VERSION ""

NS_ :

BS_:

BU_: BMS_Controller NF_Controller NF_Controllers

BO_ 2499758692 BATT_Version: 8 BMS_Controller
 SG_ BATT_SwVerSubMinorApp m0 : 24|8@1+ (1,0) [0|255] ""  NF_Controller
 SG_ BATT_SwVerMinorApp m0 : 16|8@1+ (1,0) [0|255] ""  NF_Controller
 SG_ BATT_SwVerMajorApp m0 : 8|8@1+ (1,0) [0|255] ""  NF_Controller
 SG_ BATT_HwVerApp m0 : 32|8@1+ (1,0) [0|255] ""  NF_Controller
 SG_ BATT_SwVerAbsCusApp m0 : 40|8@1+ (1,0) [0|255] ""  NF_Controller
 SG_ BATT_SwVerAbsIntApp m0 : 48|8@1+ (1,0) [0|255] ""  NF_Controller
 SG_ BATT_SwVerSubMinorBl m1 : 24|8@1+ (1,0) [0|255] ""  NF_Controller
 SG_ BATT_SwVerMinorBl m1 : 16|8@1+ (1,0) [0|255] ""  NF_Controller
 SG_ BATT_SwVerMajorBl m1 : 8|8@1+ (1,0) [0|255] ""  NF_Controller
 SG_ BATT_HwVerBl m1 : 32|8@1+ (1,0) [0|255] ""  NF_Controller
 SG_ BATT_SwVerAbsCusBl m1 : 40|8@1+ (1,0) [0|255] ""  NF_Controller
 SG_ BATT_SwVerAbsIntBl m1 : 48|8@1+ (1,0) [0|255] ""  NF_Controller
 SG_ BATT_SwVerSubMinorCal m2 : 24|8@1+ (1,0) [0|255] ""  NF_Controller
 SG_ BATT_SwVerMinorCal m2 : 16|8@1+ (1,0) [0|255] ""  NF_Controller
 SG_ BATT_SwVerMajorCal m2 : 8|8@1+ (1,0) [0|255] ""  NF_Controller
 SG_ BATT_HwVerCal m2 : 32|8@1+ (1,0) [0|255] ""  NF_Controller
 SG_ BATT_SwVerAbsCusCal m2 : 40|8@1+ (1,0) [0|255] ""  NF_Controller
 SG_ BATT_SwVerAbsIntCal m2 : 48|8@1+ (1,0) [0|255] ""  NF_Controller
 SG_ multiplexorvr M : 0|2@1+ (1,0) [0|2] ""  NF_Controllers

BO_ 2499763812 BATT_Pack_Inhibition: 8 BMS_Controller
 SG_ BATT_01_inhibitionPyroFuse m0 : 11|1@1+ (1,0) [0|1] ""  NF_Controller
 SG_ BATT_01_inhibitionRegen m0 : 10|1@1+ (1,0) [0|1] ""  NF_Controller
 SG_ BATT_01_inhibitionFullPower m0 : 9|1@1+ (1,0) [0|1] ""  NF_Controller
 SG_ BATT_01_inhibitionRampDown m0 : 8|1@1+ (1,0) [0|1] ""  NF_Controller
 SG_ BATT_01_inhibitionDriveEntry m0 : 3|1@1+ (1,0) [0|1] ""  NF_Controller
 SG_ BATT_01_inhibitionDrive m0 : 2|1@1+ (1,0) [0|1] ""  NF_Controller
 SG_ BATT_01_inhibitionCharge m0 : 1|1@1+ (1,0) [0|1] ""  NF_Controller
 SG_ BATT_01_inhibitionChargeEntry m0 : 0|1@1+ (1,0) [0|1] ""  NF_Controller
 SG_ BATT_02_inhibitionPyroFuse m1 : 11|1@1+ (1,0) [0|1] ""  NF_Controller
 SG_ BATT_02_inhibitionRegen m1 : 10|1@1+ (1,0) [0|1] ""  NF_Controller
 SG_ BATT_02_inhibitionFullPower m1 : 9|1@1+ (1,0) [0|1] ""  NF_Controller
 SG_ BATT_02_inhibitionRampDown m1 : 8|1@1+ (1,0) [0|1] ""  NF_Controller
 SG_ BATT_02_inhibitionDriveEntry m1 : 3|1@1+ (1,0) [0|1] ""  NF_Controller
 SG_ BATT_02_inhibitionDrive m1 : 2|1@1+ (1,0) [0|1] ""  NF_Controller
 SG_ BATT_02_inhibitionCharge m1 : 1|1@1+ (1,0) [0|1] ""  NF_Controller
 SG_ BATT_02_inhibitionChargeEntry m1 : 0|1@1+ (1,0) [0|1] ""  NF_Controller
 SG_ BATT_03_inhibitionPyroFuse m2 : 11|1@1+ (1,0) [0|1] ""  NF_Controller
 SG_ BATT_03_inhibitionRegen m2 : 10|1@1+ (1,0) [0|1] ""  NF_Controller
 SG_ BATT_03_inhibitionFullPower m2 : 9|1@1+ (1,0) [0|1] ""  NF_Controller
 SG_ BATT_03_inhibitionRampDown m2 : 8|1@1+ (1,0) [0|1] ""  NF_Controller
 SG_ BATT_03_inhibitionDriveEntry m2 : 3|1@1+ (1,0) [0|1] ""  NF_Controller
 SG_ BATT_03_inhibitionDrive m2 : 2|1@1+ (1,0) [0|1] ""  NF_Controller
 SG_ BATT_03_inhibitionCharge m2 : 1|1@1+ (1,0) [0|1] ""  NF_Controller
 SG_ BATT_03_inhibitionChargeEntry m2 : 0|1@1+ (1,0) [0|1] ""  NF_Controller
 SG_ BATT_04_inhibitionPyroFuse m3 : 11|1@1+ (1,0) [0|1] ""  NF_Controller
 SG_ BATT_04_inhibitionRegen m3 : 10|1@1+ (1,0) [0|1] ""  NF_Controller
 SG_ BATT_04_inhibitionFullPower m3 : 9|1@1+ (1,0) [0|1] ""  NF_Controller
 SG_ BATT_04_inhibitionRampDown m3 : 8|1@1+ (1,0) [0|1] ""  NF_Controller
 SG_ BATT_04_inhibitionDriveEntry m3 : 3|1@1+ (1,0) [0|1] ""  NF_Controller
 SG_ BATT_04_inhibitionDrive m3 : 2|1@1+ (1,0) [0|1] ""  NF_Controller
 SG_ BATT_04_inhibitionCharge m3 : 1|1@1+ (1,0) [0|1] ""  NF_Controller
 SG_ BATT_04_inhibitionChargeEntry m3 : 0|1@1+ (1,0) [0|1] ""  NF_Controller
 SG_ BATT_05_inhibitionPyroFuse m4 : 11|1@1+ (1,0) [0|1] ""  NF_Controller
 SG_ BATT_05_inhibitionRegen m4 : 10|1@1+ (1,0) [0|1] ""  NF_Controller
 SG_ BATT_05_inhibitionFullPower m4 : 9|1@1+ (1,0) [0|1] ""  NF_Controller
 SG_ BATT_05_inhibitionRampDown m4 : 8|1@1+ (1,0) [0|1] ""  NF_Controller
 SG_ BATT_05_inhibitionDriveEntry m4 : 3|1@1+ (1,0) [0|1] ""  NF_Controller
 SG_ BATT_05_inhibitionDrive m4 : 2|1@1+ (1,0) [0|1] ""  NF_Controller
 SG_ BATT_05_inhibitionCharge m4 : 1|1@1+ (1,0) [0|1] ""  NF_Controller
 SG_ BATT_05_inhibitionChargeEntry m4 : 0|1@1+ (1,0) [0|1] ""  NF_Controller
 SG_ BATT_06_inhibitionPyroFuse m5 : 11|1@1+ (1,0) [0|1] ""  NF_Controller
 SG_ BATT_06_inhibitionRegen m5 : 10|1@1+ (1,0) [0|1] ""  NF_Controller
 SG_ BATT_06_inhibitionFullPower m5 : 9|1@1+ (1,0) [0|1] ""  NF_Controller
 SG_ BATT_06_inhibitionRampDown m5 : 8|1@1+ (1,0) [0|1] ""  NF_Controller
 SG_ BATT_06_inhibitionDriveEntry m5 : 3|1@1+ (1,0) [0|1] ""  NF_Controller
 SG_ BATT_06_inhibitionDrive m5 : 2|1@1+ (1,0) [0|1] ""  NF_Controller
 SG_ BATT_06_inhibitionCharge m5 : 1|1@1+ (1,0) [0|1] ""  NF_Controller
 SG_ BATT_06_inhibitionChargeEntry m5 : 0|1@1+ (1,0) [0|1] ""  NF_Controller
 SG_ BATT_07_inhibitionPyroFuse m6 : 11|1@1+ (1,0) [0|1] ""  NF_Controller
 SG_ BATT_07_inhibitionRegen m6 : 10|1@1+ (1,0) [0|1] ""  NF_Controller
 SG_ BATT_07_inhibitionFullPower m6 : 9|1@1+ (1,0) [0|1] ""  NF_Controller
 SG_ BATT_07_inhibitionRampDown m6 : 8|1@1+ (1,0) [0|1] ""  NF_Controller
 SG_ BATT_07_inhibitionDriveEntry m6 : 3|1@1+ (1,0) [0|1] ""  NF_Controller
 SG_ BATT_07_inhibitionDrive m6 : 2|1@1+ (1,0) [0|1] ""  NF_Controller
 SG_ BATT_07_inhibitionCharge m6 : 1|1@1+ (1,0) [0|1] ""  NF_Controller
 SG_ BATT_07_inhibitionChargeEntry m6 : 0|1@1+ (1,0) [0|1] ""  NF_Controller
 SG_ BATT_08_inhibitionPyroFuse m7 : 11|1@1+ (1,0) [0|1] ""  NF_Controller
 SG_ BATT_08_inhibitionRegen m7 : 10|1@1+ (1,0) [0|1] ""  NF_Controller
 SG_ BATT_08_inhibitionFullPower m7 : 9|1@1+ (1,0) [0|1] ""  NF_Controller
 SG_ BATT_08_inhibitionRampDown m7 : 8|1@1+ (1,0) [0|1] ""  NF_Controller
 SG_ BATT_08_inhibitionDriveEntry m7 : 3|1@1+ (1,0) [0|1] ""  NF_Controller
 SG_ BATT_08_inhibitionDrive m7 : 2|1@1+ (1,0) [0|1] ""  NF_Controller
 SG_ BATT_08_inhibitionCharge m7 : 1|1@1+ (1,0) [0|1] ""  NF_Controller
 SG_ BATT_08_inhibitionChargeEntry m7 : 0|1@1+ (1,0) [0|1] ""  NF_Controller
 SG_ BATT_09_inhibitionPyroFuse m8 : 11|1@1+ (1,0) [0|1] ""  NF_Controller
 SG_ BATT_09_inhibitionRegen m8 : 10|1@1+ (1,0) [0|1] ""  NF_Controller
 SG_ BATT_09_inhibitionFullPower m8 : 9|1@1+ (1,0) [0|1] ""  NF_Controller
 SG_ BATT_09_inhibitionRampDown m8 : 8|1@1+ (1,0) [0|1] ""  NF_Controller
 SG_ BATT_09_inhibitionDriveEntry m8 : 3|1@1+ (1,0) [0|1] ""  NF_Controller
 SG_ BATT_09_inhibitionDrive m8 : 2|1@1+ (1,0) [0|1] ""  NF_Controller
 SG_ BATT_09_inhibitionCharge m8 : 1|1@1+ (1,0) [0|1] ""  NF_Controller
 SG_ BATT_09_inhibitionChargeEntry m8 : 0|1@1+ (1,0) [0|1] ""  NF_Controller
 SG_ BATT_10_inhibitionPyroFuse m9 : 11|1@1+ (1,0) [0|1] ""  NF_Controller
 SG_ BATT_10_inhibitionRegen m9 : 10|1@1+ (1,0) [0|1] ""  NF_Controller
 SG_ BATT_10_inhibitionFullPower m9 : 9|1@1+ (1,0) [0|1] ""  NF_Controller
 SG_ BATT_10_inhibitionRampDown m9 : 8|1@1+ (1,0) [0|1] ""  NF_Controller
 SG_ BATT_10_inhibitionDriveEntry m9 : 3|1@1+ (1,0) [0|1] ""  NF_Controller
 SG_ BATT_10_inhibitionDrive m9 : 2|1@1+ (1,0) [0|1] ""  NF_Controller
 SG_ BATT_10_inhibitionCharge m9 : 1|1@1+ (1,0) [0|1] ""  NF_Controller
 SG_ BATT_10_inhibitionChargeEntry m9 : 0|1@1+ (1,0) [0|1] ""  NF_Controller
 SG_ BATT_packInhMux M : 4|4@1+ (1,0) [0|15] ""  NF_Controller

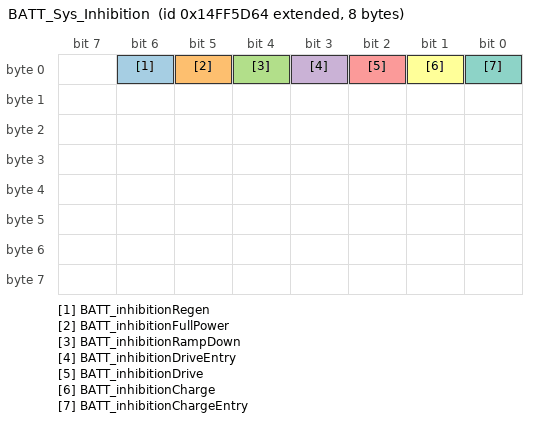
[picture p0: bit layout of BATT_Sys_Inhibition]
BO_ 2499763556 BATT_Sys_Inhibition: 8 BMS_Controller
 SG_ BATT_inhibitionRegen : 6|1@1+ (1,0) [0|1] ""  NF_Controller
 SG_ BATT_inhibitionFullPower : 5|1@1+ (1,0) [0|1] ""  NF_Controller
 SG_ BATT_inhibitionRampDown : 4|1@1+ (1,0) [0|1] ""  NF_Controller
 SG_ BATT_inhibitionDriveEntry : 3|1@1+ (1,0) [0|1] ""  NF_Controller
 SG_ BATT_inhibitionDrive : 2|1@1+ (1,0) [0|1] ""  NF_Controller
 SG_ BATT_inhibitionCharge : 1|1@1+ (1,0) [0|1] ""  NF_Controller
 SG_ BATT_inhibitionChargeEntry : 0|1@1+ (1,0) [0|1] ""  NF_Controller

BO_ 2499763300 BATT_Diagnostic_Pack_D: 8 BMS_Controller
 SG_ BATT_01_Placeholder16 m0 : 10|2@1+ (1,0) [0|3] ""  NF_Controller
 SG_ BATT_01_Placeholder15 m0 : 8|2@1+ (1,0) [0|3] ""  NF_Controller
 SG_ BATT_01_Placeholder14 m0 : 22|2@1+ (1,0) [0|3] ""  NF_Controller
 SG_ BATT_01_Placeholder13 m0 : 20|2@1+ (1,0) [0|3] ""  NF_Controller
 SG_ BATT_01_Placeholder02 m0 : 46|2@1+ (1,0) [0|3] ""  NF_Controller
 SG_ BATT_01_Placeholder01 m0 : 44|2@1+ (1,0) [0|3] ""  NF_Controller
 SG_ BATT_01_Placeholder12 m0 : 18|2@1+ (1,0) [0|3] ""  NF_Controller
 SG_ BATT_01_Placeholder11 m0 : 16|2@1+ (1,0) [0|3] ""  NF_Controller
 SG_ BATT_01_Placeholder10 m0 : 30|2@1+ (1,0) [0|3] ""  NF_Controller
 SG_ BATT_01_Placeholder09 m0 : 28|2@1+ (1,0) [0|3] ""  NF_Controller
 SG_ BATT_01_Placeholder08 m0 : 26|2@1+ (1,0) [0|3] ""  NF_Controller
 SG_ BATT_01_Placeholder07 m0 : 24|2@1+ (1,0) [0|3] ""  NF_Controller
 SG_ BATT_01_Placeholder06 m0 : 38|2@1+ (1,0) [0|3] ""  NF_Controller
 SG_ BATT_01_Placeholder05 m0 : 36|2@1+ (1,0) [0|3] ""  NF_Controller
 SG_ BATT_01_SpeakerMia m0 : 2|2@1+ (1,0) [0|3] ""  NF_Controller
 SG_ BATT_01_Placeholder19 m0 : 0|2@1+ (1,0) [0|3] ""  NF_Controller
 SG_ BATT_01_Placeholder18 m0 : 14|2@1+ (1,0) [0|3] ""  NF_Controller
 SG_ BATT_01_Placeholder17 m0 : 12|2@1+ (1,0) [0|3] ""  NF_Controller
 SG_ BATT_01_Placeholder04 m0 : 34|2@1+ (1,0) [0|3] ""  NF_Controller
 SG_ BATT_01_Placeholder03 m0 : 32|2@1+ (1,0) [0|3] ""  NF_Controller
 SG_ BATT_02_Placeholder16 m1 : 10|2@1+ (1,0) [0|3] ""  NF_Controller
 SG_ BATT_02_Placeholder15 m1 : 8|2@1+ (1,0) [0|3] ""  NF_Controller
 SG_ BATT_02_Placeholder14 m1 : 22|2@1+ (1,0) [0|3] ""  NF_Controller
 SG_ BATT_02_Placeholder13 m1 : 20|2@1+ (1,0) [0|3] ""  NF_Controller
 SG_ BATT_02_Placeholder02 m1 : 46|2@1+ (1,0) [0|3] ""  NF_Controller
 SG_ BATT_02_Placeholder01 m1 : 44|2@1+ (1,0) [0|3] ""  NF_Controller
 SG_ BATT_02_Placeholder12 m1 : 18|2@1+ (1,0) [0|3] ""  NF_Controller
 SG_ BATT_02_Placeholder11 m1 : 16|2@1+ (1,0) [0|3] ""  NF_Controller
 SG_ BATT_02_Placeholder10 m1 : 30|2@1+ (1,0) [0|3] ""  NF_Controller
 SG_ BATT_02_Placeholder09 m1 : 28|2@1+ (1,0) [0|3] ""  NF_Controller
 SG_ BATT_02_Placeholder08 m1 : 26|2@1+ (1,0) [0|3] ""  NF_Controller
 SG_ BATT_02_Placeholder07 m1 : 24|2@1+ (1,0) [0|3] ""  NF_Controller
 SG_ BATT_02_Placeholder06 m1 : 38|2@1+ (1,0) [0|3] ""  NF_Controller
 SG_ BATT_02_Placeholder05 m1 : 36|2@1+ (1,0) [0|3] ""  NF_Controller
 SG_ BATT_02_SpeakerMia m1 : 2|2@1+ (1,0) [0|3] ""  NF_Controller
 SG_ BATT_02_Placeholder19 m1 : 0|2@1+ (1,0) [0|3] ""  NF_Controller
 SG_ BATT_02_Placeholder18 m1 : 14|2@1+ (1,0) [0|3] ""  NF_Controller
 SG_ BATT_02_Placeholder17 m1 : 12|2@1+ (1,0) [0|3] ""  NF_Controller
 SG_ BATT_02_Placeholder04 m1 : 34|2@1+ (1,0) [0|3] ""  NF_Controller
 SG_ BATT_02_Placeholder03 m1 : 32|2@1+ (1,0) [0|3] ""  NF_Controller
 SG_ BATT_03_Placeholder16 m2: 10|2@1+ (1,0) [0|3] ""  NF_Controller
 SG_ BATT_03_Placeholder15 m2: 8|2@1+ (1,0) [0|3] ""  NF_Controller
 SG_ BATT_03_Placeholder14 m2: 22|2@1+ (1,0) [0|3] ""  NF_Controller
 SG_ BATT_03_Placeholder13 m2: 20|2@1+ (1,0) [0|3] ""  NF_Controller
 SG_ BATT_03_Placeholder02 m2: 46|2@1+ (1,0) [0|3] ""  NF_Controller
 SG_ BATT_03_Placeholder01 m2: 44|2@1+ (1,0) [0|3] ""  NF_Controller
 SG_ BATT_03_Placeholder12 m2: 18|2@1+ (1,0) [0|3] ""  NF_Controller
 SG_ BATT_03_Placeholder11 m2: 16|2@1+ (1,0) [0|3] ""  NF_Controller
 SG_ BATT_03_Placeholder10 m2: 30|2@1+ (1,0) [0|3] ""  NF_Controller
 SG_ BATT_03_Placeholder09 m2: 28|2@1+ (1,0) [0|3] ""  NF_Controller
 SG_ BATT_03_Placeholder08 m2: 26|2@1+ (1,0) [0|3] ""  NF_Controller
 SG_ BATT_03_Placeholder07 m2: 24|2@1+ (1,0) [0|3] ""  NF_Controller
 SG_ BATT_03_Placeholder06 m2: 38|2@1+ (1,0) [0|3] ""  NF_Controller
 SG_ BATT_03_Placeholder05 m2: 36|2@1+ (1,0) [0|3] ""  NF_Controller
 SG_ BATT_03_SpeakerMia m2: 2|2@1+ (1,0) [0|3] ""  NF_Controller
 SG_ BATT_03_Placeholder19 m2: 0|2@1+ (1,0) [0|3] ""  NF_Controller
 SG_ BATT_03_Placeholder18 m2: 14|2@1+ (1,0) [0|3] ""  NF_Controller
 SG_ BATT_03_Placeholder17 m2: 12|2@1+ (1,0) [0|3] ""  NF_Controller
 SG_ BATT_03_Placeholder04 m2: 34|2@1+ (1,0) [0|3] ""  NF_Controller
 SG_ BATT_03_Placeholder03 m2: 32|2@1+ (1,0) [0|3] ""  NF_Controller
 SG_ BATT_04_Placeholder16 m3 : 10|2@1+ (1,0) [0|3] ""  NF_Controller
 SG_ BATT_04_Placeholder15 m3 : 8|2@1+ (1,0) [0|3] ""  NF_Controller
 SG_ BATT_04_Placeholder14 m3 : 22|2@1+ (1,0) [0|3] ""  NF_Controller
 SG_ BATT_04_Placeholder13 m3 : 20|2@1+ (1,0) [0|3] ""  NF_Controller
 SG_ BATT_04_Placeholder02 m3 : 46|2@1+ (1,0) [0|3] ""  NF_Controller
 SG_ BATT_04_Placeholder01 m3 : 44|2@1+ (1,0) [0|3] ""  NF_Controller
 SG_ BATT_04_Placeholder12 m3 : 18|2@1+ (1,0) [0|3] ""  NF_Controller
 SG_ BATT_04_Placeholder11 m3 : 16|2@1+ (1,0) [0|3] ""  NF_Controller
 SG_ BATT_04_Placeholder10 m3 : 30|2@1+ (1,0) [0|3] ""  NF_Controller
 SG_ BATT_04_Placeholder09 m3 : 28|2@1+ (1,0) [0|3] ""  NF_Controller
 SG_ BATT_04_Placeholder08 m3 : 26|2@1+ (1,0) [0|3] ""  NF_Controller
 SG_ BATT_04_Placeholder07 m3 : 24|2@1+ (1,0) [0|3] ""  NF_Controller
 SG_ BATT_04_Placeholder06 m3 : 38|2@1+ (1,0) [0|3] ""  NF_Controller
 SG_ BATT_04_Placeholder05 m3 : 36|2@1+ (1,0) [0|3] ""  NF_Controller
 SG_ BATT_04_SpeakerMia m3 : 2|2@1+ (1,0) [0|3] ""  NF_Controller
 SG_ BATT_04_Placeholder19 m3 : 0|2@1+ (1,0) [0|3] ""  NF_Controller
 SG_ BATT_04_Placeholder18 m3 : 14|2@1+ (1,0) [0|3] ""  NF_Controller
 SG_ BATT_04_Placeholder17 m3 : 12|2@1+ (1,0) [0|3] ""  NF_Controller
 SG_ BATT_04_Placeholder04 m3 : 34|2@1+ (1,0) [0|3] ""  NF_Controller
 SG_ BATT_04_Placeholder03 m3 : 32|2@1+ (1,0) [0|3] ""  NF_Controller
 SG_ BATT_05_Placeholder16 m4 : 10|2@1+ (1,0) [0|3] ""  NF_Controller
 SG_ BATT_05_Placeholder15 m4 : 8|2@1+ (1,0) [0|3] ""  NF_Controller
 SG_ BATT_05_Placeholder14 m4 : 22|2@1+ (1,0) [0|3] ""  NF_Controller
 SG_ BATT_05_Placeholder13 m4 : 20|2@1+ (1,0) [0|3] ""  NF_Controller
 SG_ BATT_05_Placeholder02 m4 : 46|2@1+ (1,0) [0|3] ""  NF_Controller
 SG_ BATT_05_Placeholder01 m4 : 44|2@1+ (1,0) [0|3] ""  NF_Controller
 SG_ BATT_05_Placeholder12 m4 : 18|2@1+ (1,0) [0|3] ""  NF_Controller
 SG_ BATT_05_Placeholder11 m4 : 16|2@1+ (1,0) [0|3] ""  NF_Controller
 SG_ BATT_05_Placeholder10 m4 : 30|2@1+ (1,0) [0|3] ""  NF_Controller
 SG_ BATT_05_Placeholder09 m4 : 28|2@1+ (1,0) [0|3] ""  NF_Controller
 SG_ BATT_05_Placeholder08 m4 : 26|2@1+ (1,0) [0|3] ""  NF_Controller
 SG_ BATT_05_Placeholder07 m4 : 24|2@1+ (1,0) [0|3] ""  NF_Controller
 SG_ BATT_05_Placeholder06 m4 : 38|2@1+ (1,0) [0|3] ""  NF_Controller
 SG_ BATT_05_Placeholder05 m4 : 36|2@1+ (1,0) [0|3] ""  NF_Controller
 SG_ BATT_05_SpeakerMia m4 : 2|2@1+ (1,0) [0|3] ""  NF_Controller
 SG_ BATT_05_Placeholder19 m4 : 0|2@1+ (1,0) [0|3] ""  NF_Controller
 SG_ BATT_05_Placeholder18 m4 : 14|2@1+ (1,0) [0|3] ""  NF_Controller
 SG_ BATT_05_Placeholder17 m4 : 12|2@1+ (1,0) [0|3] ""  NF_Controller
 SG_ BATT_05_Placeholder04 m4 : 34|2@1+ (1,0) [0|3] ""  NF_Controller
 SG_ BATT_05_Placeholder03 m4 : 32|2@1+ (1,0) [0|3] ""  NF_Controller
 SG_ BATT_06_Placeholder16 m5 : 10|2@1+ (1,0) [0|3] ""  NF_Controller
 SG_ BATT_06_Placeholder15 m5 : 8|2@1+ (1,0) [0|3] ""  NF_Controller
 SG_ BATT_06_Placeholder14 m5 : 22|2@1+ (1,0) [0|3] ""  NF_Controller
 SG_ BATT_06_Placeholder13 m5 : 20|2@1+ (1,0) [0|3] ""  NF_Controller
 SG_ BATT_06_Placeholder02 m5 : 46|2@1+ (1,0) [0|3] ""  NF_Controller
 SG_ BATT_06_Placeholder01 m5 : 44|2@1+ (1,0) [0|3] ""  NF_Controller
 SG_ BATT_06_Placeholder12 m5 : 18|2@1+ (1,0) [0|3] ""  NF_Controller
 SG_ BATT_06_Placeholder11 m5 : 16|2@1+ (1,0) [0|3] ""  NF_Controller
 SG_ BATT_06_Placeholder10 m5 : 30|2@1+ (1,0) [0|3] ""  NF_Controller
 SG_ BATT_06_Placeholder09 m5 : 28|2@1+ (1,0) [0|3] ""  NF_Controller
 SG_ BATT_06_Placeholder08 m5 : 26|2@1+ (1,0) [0|3] ""  NF_Controller
 SG_ BATT_06_Placeholder07 m5 : 24|2@1+ (1,0) [0|3] ""  NF_Controller
 SG_ BATT_06_Placeholder06 m5 : 38|2@1+ (1,0) [0|3] ""  NF_Controller
 SG_ BATT_06_Placeholder05 m5 : 36|2@1+ (1,0) [0|3] ""  NF_Controller
 SG_ BATT_06_SpeakerMia m5 : 2|2@1+ (1,0) [0|3] ""  NF_Controller
 SG_ BATT_06_Placeholder19 m5 : 0|2@1+ (1,0) [0|3] ""  NF_Controller
 SG_ BATT_06_Placeholder18 m5 : 14|2@1+ (1,0) [0|3] ""  NF_Controller
 SG_ BATT_06_Placeholder17 m5 : 12|2@1+ (1,0) [0|3] ""  NF_Controller
 SG_ BATT_06_Placeholder04 m5 : 34|2@1+ (1,0) [0|3] ""  NF_Controller
 SG_ BATT_06_Placeholder03 m5 : 32|2@1+ (1,0) [0|3] ""  NF_Controller
 SG_ BATT_07_Placeholder16 m6 : 10|2@1+ (1,0) [0|3] ""  NF_Controller
 SG_ BATT_07_Placeholder15 m6 : 8|2@1+ (1,0) [0|3] ""  NF_Controller
 SG_ BATT_07_Placeholder14 m6 : 22|2@1+ (1,0) [0|3] ""  NF_Controller
 SG_ BATT_07_Placeholder13 m6 : 20|2@1+ (1,0) [0|3] ""  NF_Controller
 SG_ BATT_07_Placeholder02 m6 : 46|2@1+ (1,0) [0|3] ""  NF_Controller
 SG_ BATT_07_Placeholder01 m6 : 44|2@1+ (1,0) [0|3] ""  NF_Controller
 SG_ BATT_07_Placeholder12 m6 : 18|2@1+ (1,0) [0|3] ""  NF_Controller
 SG_ BATT_07_Placeholder11 m6 : 16|2@1+ (1,0) [0|3] ""  NF_Controller
 SG_ BATT_07_Placeholder10 m6 : 30|2@1+ (1,0) [0|3] ""  NF_Controller
 SG_ BATT_07_Placeholder09 m6 : 28|2@1+ (1,0) [0|3] ""  NF_Controller
 SG_ BATT_07_Placeholder08 m6 : 26|2@1+ (1,0) [0|3] ""  NF_Controller
 SG_ BATT_07_Placeholder07 m6 : 24|2@1+ (1,0) [0|3] ""  NF_Controller
 SG_ BATT_07_Placeholder06 m6 : 38|2@1+ (1,0) [0|3] ""  NF_Controller
 SG_ BATT_07_Placeholder05 m6 : 36|2@1+ (1,0) [0|3] ""  NF_Controller
 SG_ BATT_07_SpeakerMia m6 : 2|2@1+ (1,0) [0|3] ""  NF_Controller
 SG_ BATT_07_Placeholder19 m6 : 0|2@1+ (1,0) [0|3] ""  NF_Controller
 SG_ BATT_07_Placeholder18 m6 : 14|2@1+ (1,0) [0|3] ""  NF_Controller
 SG_ BATT_07_Placeholder17 m6 : 12|2@1+ (1,0) [0|3] ""  NF_Controller
 SG_ BATT_07_Placeholder04 m6 : 34|2@1+ (1,0) [0|3] ""  NF_Controller
 SG_ BATT_07_Placeholder03 m6 : 32|2@1+ (1,0) [0|3] ""  NF_Controller
 SG_ BATT_08_Placeholder16 m7 : 10|2@1+ (1,0) [0|3] ""  NF_Controller
 SG_ BATT_08_Placeholder15 m7 : 8|2@1+ (1,0) [0|3] ""  NF_Controller
 SG_ BATT_08_Placeholder14 m7 : 22|2@1+ (1,0) [0|3] ""  NF_Controller
 SG_ BATT_08_Placeholder13 m7 : 20|2@1+ (1,0) [0|3] ""  NF_Controller
 SG_ BATT_08_Placeholder02 m7 : 46|2@1+ (1,0) [0|3] ""  NF_Controller
 SG_ BATT_08_Placeholder01 m7 : 44|2@1+ (1,0) [0|3] ""  NF_Controller
 SG_ BATT_08_Placeholder12 m7 : 18|2@1+ (1,0) [0|3] ""  NF_Controller
 SG_ BATT_08_Placeholder11 m7 : 16|2@1+ (1,0) [0|3] ""  NF_Controller
 SG_ BATT_08_Placeholder10 m7 : 30|2@1+ (1,0) [0|3] ""  NF_Controller
 SG_ BATT_08_Placeholder09 m7 : 28|2@1+ (1,0) [0|3] ""  NF_Controller
 SG_ BATT_08_Placeholder08 m7 : 26|2@1+ (1,0) [0|3] ""  NF_Controller
 SG_ BATT_08_Placeholder07 m7 : 24|2@1+ (1,0) [0|3] ""  NF_Controller
 SG_ BATT_08_Placeholder06 m7 : 38|2@1+ (1,0) [0|3] ""  NF_Controller
 SG_ BATT_08_Placeholder05 m7 : 36|2@1+ (1,0) [0|3] ""  NF_Controller
 SG_ BATT_08_SpeakerMia m7 : 2|2@1+ (1,0) [0|3] ""  NF_Controller
 SG_ BATT_08_Placeholder19 m7 : 0|2@1+ (1,0) [0|3] ""  NF_Controller
 SG_ BATT_08_Placeholder18 m7 : 14|2@1+ (1,0) [0|3] ""  NF_Controller
 SG_ BATT_08_Placeholder17 m7 : 12|2@1+ (1,0) [0|3] ""  NF_Controller
 SG_ BATT_08_Placeholder04 m7 : 34|2@1+ (1,0) [0|3] ""  NF_Controller
 SG_ BATT_08_Placeholder03 m7 : 32|2@1+ (1,0) [0|3] ""  NF_Controller
 SG_ BATT_09_Placeholder16 m8 : 10|2@1+ (1,0) [0|3] ""  NF_Controller
 SG_ BATT_09_Placeholder15 m8 : 8|2@1+ (1,0) [0|3] ""  NF_Controller
 SG_ BATT_09_Placeholder14 m8 : 22|2@1+ (1,0) [0|3] ""  NF_Controller
 SG_ BATT_09_Placeholder13 m8 : 20|2@1+ (1,0) [0|3] ""  NF_Controller
 SG_ BATT_09_Placeholder02 m8 : 46|2@1+ (1,0) [0|3] ""  NF_Controller
 SG_ BATT_09_Placeholder01 m8 : 44|2@1+ (1,0) [0|3] ""  NF_Controller
 SG_ BATT_09_Placeholder12 m8 : 18|2@1+ (1,0) [0|3] ""  NF_Controller
 SG_ BATT_09_Placeholder11 m8 : 16|2@1+ (1,0) [0|3] ""  NF_Controller
 SG_ BATT_09_Placeholder10 m8 : 30|2@1+ (1,0) [0|3] ""  NF_Controller
 SG_ BATT_09_Placeholder09 m8 : 28|2@1+ (1,0) [0|3] ""  NF_Controller
 SG_ BATT_09_Placeholder08 m8 : 26|2@1+ (1,0) [0|3] ""  NF_Controller
 SG_ BATT_09_Placeholder07 m8 : 24|2@1+ (1,0) [0|3] ""  NF_Controller
 SG_ BATT_09_Placeholder06 m8 : 38|2@1+ (1,0) [0|3] ""  NF_Controller
 SG_ BATT_09_Placeholder05 m8 : 36|2@1+ (1,0) [0|3] ""  NF_Controller
 SG_ BATT_09_SpeakerMia m8 : 2|2@1+ (1,0) [0|3] ""  NF_Controller
 SG_ BATT_09_Placeholder19 m8 : 0|2@1+ (1,0) [0|3] ""  NF_Controller
 SG_ BATT_09_Placeholder18 m8 : 14|2@1+ (1,0) [0|3] ""  NF_Controller
 SG_ BATT_09_Placeholder17 m8 : 12|2@1+ (1,0) [0|3] ""  NF_Controller
 SG_ BATT_09_Placeholder04 m8 : 34|2@1+ (1,0) [0|3] ""  NF_Controller
 SG_ BATT_09_Placeholder03 m8 : 32|2@1+ (1,0) [0|3] ""  NF_Controller
 SG_ BATT_10_Placeholder16 m9 : 10|2@1+ (1,0) [0|3] ""  NF_Controller
 SG_ BATT_10_Placeholder15 m9 : 8|2@1+ (1,0) [0|3] ""  NF_Controller
 SG_ BATT_10_Placeholder14 m9 : 22|2@1+ (1,0) [0|3] ""  NF_Controller
 SG_ BATT_10_Placeholder13 m9 : 20|2@1+ (1,0) [0|3] ""  NF_Controller
 SG_ BATT_10_Placeholder02 m9 : 46|2@1+ (1,0) [0|3] ""  NF_Controller
 SG_ BATT_10_Placeholder01 m9 : 44|2@1+ (1,0) [0|3] ""  NF_Controller
 SG_ BATT_10_Placeholder12 m9 : 18|2@1+ (1,0) [0|3] ""  NF_Controller
 SG_ BATT_10_Placeholder11 m9 : 16|2@1+ (1,0) [0|3] ""  NF_Controller
 SG_ BATT_10_Placeholder10 m9 : 30|2@1+ (1,0) [0|3] ""  NF_Controller
 SG_ BATT_10_Placeholder09 m9 : 28|2@1+ (1,0) [0|3] ""  NF_Controller
 SG_ BATT_10_Placeholder08 m9 : 26|2@1+ (1,0) [0|3] ""  NF_Controller
 SG_ BATT_10_Placeholder07 m9 : 24|2@1+ (1,0) [0|3] ""  NF_Controller
 SG_ BATT_10_Placeholder06 m9 : 38|2@1+ (1,0) [0|3] ""  NF_Controller
 SG_ BATT_10_Placeholder05 m9 : 36|2@1+ (1,0) [0|3] ""  NF_Controller
 SG_ BATT_10_SpeakerMia m9 : 2|2@1+ (1,0) [0|3] ""  NF_Controller
 SG_ BATT_10_Placeholder19 m9 : 0|2@1+ (1,0) [0|3] ""  NF_Controller
 SG_ BATT_10_Placeholder18 m9 : 14|2@1+ (1,0) [0|3] ""  NF_Controller
 SG_ BATT_10_Placeholder17 m9 : 12|2@1+ (1,0) [0|3] ""  NF_Controller
 SG_ BATT_10_Placeholder04 m9 : 34|2@1+ (1,0) [0|3] ""  NF_Controller
 SG_ BATT_10_Placeholder03 m9 : 32|2@1+ (1,0) [0|3] ""  NF_Controller
 SG_ BATT_11_Placeholder16 m10 : 10|2@1+ (1,0) [0|3] ""  NF_Controller
 SG_ BATT_11_Placeholder15 m10 : 8|2@1+ (1,0) [0|3] ""  NF_Controller
 SG_ BATT_11_Placeholder14 m10 : 22|2@1+ (1,0) [0|3] ""  NF_Controller
 SG_ BATT_11_Placeholder13 m10 : 20|2@1+ (1,0) [0|3] ""  NF_Controller
 SG_ BATT_11_Placeholder02 m10 : 46|2@1+ (1,0) [0|3] ""  NF_Controller
 SG_ BATT_11_Placeholder01 m10 : 44|2@1+ (1,0) [0|3] ""  NF_Controller
 SG_ BATT_11_Placeholder12 m10 : 18|2@1+ (1,0) [0|3] ""  NF_Controller
 SG_ BATT_11_Placeholder11 m10 : 16|2@1+ (1,0) [0|3] ""  NF_Controller
 SG_ BATT_11_Placeholder10 m10 : 30|2@1+ (1,0) [0|3] ""  NF_Controller
 SG_ BATT_11_Placeholder09 m10 : 28|2@1+ (1,0) [0|3] ""  NF_Controller
 SG_ BATT_11_Placeholder08 m10 : 26|2@1+ (1,0) [0|3] ""  NF_Controller
 SG_ BATT_11_Placeholder07 m10 : 24|2@1+ (1,0) [0|3] ""  NF_Controller
 SG_ BATT_11_Placeholder06 m10 : 38|2@1+ (1,0) [0|3] ""  NF_Controller
 SG_ BATT_11_Placeholder05 m10 : 36|2@1+ (1,0) [0|3] ""  NF_Controller
 SG_ BATT_11_SpeakerMia m10 : 2|2@1+ (1,0) [0|3] ""  NF_Controller
 SG_ BATT_11_Placeholder19 m10 : 0|2@1+ (1,0) [0|3] ""  NF_Controller
 SG_ BATT_11_Placeholder18 m10 : 14|2@1+ (1,0) [0|3] ""  NF_Controller
 SG_ BATT_11_Placeholder17 m10 : 12|2@1+ (1,0) [0|3] ""  NF_Controller
 SG_ BATT_11_Placeholder04 m10 : 34|2@1+ (1,0) [0|3] ""  NF_Controller
 SG_ BATT_11_Placeholder03 m10 : 32|2@1+ (1,0) [0|3] ""  NF_Controller
 SG_ BATT_12_Placeholder16 m11 : 10|2@1+ (1,0) [0|3] ""  NF_Controller
 SG_ BATT_12_Placeholder15 m11 : 8|2@1+ (1,0) [0|3] ""  NF_Controller
 SG_ BATT_12_Placeholder14 m11 : 22|2@1+ (1,0) [0|3] ""  NF_Controller
 SG_ BATT_12_Placeholder13 m11 : 20|2@1+ (1,0) [0|3] ""  NF_Controller
 SG_ BATT_12_Placeholder02 m11 : 46|2@1+ (1,0) [0|3] ""  NF_Controller
 SG_ BATT_12_Placeholder01 m11 : 44|2@1+ (1,0) [0|3] ""  NF_Controller
 SG_ BATT_12_Placeholder12 m11 : 18|2@1+ (1,0) [0|3] ""  NF_Controller
 SG_ BATT_12_Placeholder11 m11 : 16|2@1+ (1,0) [0|3] ""  NF_Controller
 SG_ BATT_12_Placeholder10 m11 : 30|2@1+ (1,0) [0|3] ""  NF_Controller
 SG_ BATT_12_Placeholder09 m11 : 28|2@1+ (1,0) [0|3] ""  NF_Controller
 SG_ BATT_12_Placeholder08 m11 : 26|2@1+ (1,0) [0|3] ""  NF_Controller
 SG_ BATT_12_Placeholder07 m11 : 24|2@1+ (1,0) [0|3] ""  NF_Controller
 SG_ BATT_12_Placeholder06 m11 : 38|2@1+ (1,0) [0|3] ""  NF_Controller
 SG_ BATT_12_Placeholder05 m11 : 36|2@1+ (1,0) [0|3] ""  NF_Controller
 SG_ BATT_12_SpeakerMia m11 : 2|2@1+ (1,0) [0|3] ""  NF_Controller
 SG_ BATT_12_Placeholder19 m11 : 0|2@1+ (1,0) [0|3] ""  NF_Controller
 SG_ BATT_12_Placeholder18 m11 : 14|2@1+ (1,0) [0|3] ""  NF_Controller
 SG_ BATT_12_Placeholder17 m11 : 12|2@1+ (1,0) [0|3] ""  NF_Controller
 SG_ BATT_12_Placeholder04 m11 : 34|2@1+ (1,0) [0|3] ""  NF_Controller
 SG_ BATT_12_Placeholder03 m11 : 32|2@1+ (1,0) [0|3] ""  NF_Controller
 SG_ BATT_13_Placeholder16 m12 : 10|2@1+ (1,0) [0|3] ""  NF_Controller
 SG_ BATT_13_Placeholder15 m12 : 8|2@1+ (1,0) [0|3] ""  NF_Controller
 SG_ BATT_13_Placeholder14 m12 : 22|2@1+ (1,0) [0|3] ""  NF_Controller
 SG_ BATT_13_Placeholder13 m12 : 20|2@1+ (1,0) [0|3] ""  NF_Controller
 SG_ BATT_13_Placeholder02 m12 : 46|2@1+ (1,0) [0|3] ""  NF_Controller
 SG_ BATT_13_Placeholder01 m12 : 44|2@1+ (1,0) [0|3] ""  NF_Controller
 SG_ BATT_13_Placeholder12 m12 : 18|2@1+ (1,0) [0|3] ""  NF_Controller
 SG_ BATT_13_Placeholder11 m12 : 16|2@1+ (1,0) [0|3] ""  NF_Controller
 SG_ BATT_13_Placeholder10 m12 : 30|2@1+ (1,0) [0|3] ""  NF_Controller
 SG_ BATT_13_Placeholder09 m12 : 28|2@1+ (1,0) [0|3] ""  NF_Controller
 SG_ BATT_13_Placeholder08 m12 : 26|2@1+ (1,0) [0|3] ""  NF_Controller
 SG_ BATT_13_Placeholder07 m12 : 24|2@1+ (1,0) [0|3] ""  NF_Controller
 SG_ BATT_13_Placeholder06 m12 : 38|2@1+ (1,0) [0|3] ""  NF_Controller
 SG_ BATT_13_Placeholder05 m12 : 36|2@1+ (1,0) [0|3] ""  NF_Controller
 SG_ BATT_13_SpeakerMia m12 : 2|2@1+ (1,0) [0|3] ""  NF_Controller
 SG_ BATT_13_Placeholder19 m12 : 0|2@1+ (1,0) [0|3] ""  NF_Controller
 SG_ BATT_13_Placeholder18 m12 : 14|2@1+ (1,0) [0|3] ""  NF_Controller
 SG_ BATT_13_Placeholder17 m12 : 12|2@1+ (1,0) [0|3] ""  NF_Controller
 SG_ BATT_13_Placeholder04 m12 : 34|2@1+ (1,0) [0|3] ""  NF_Controller
 SG_ BATT_13_Placeholder03 m12 : 32|2@1+ (1,0) [0|3] ""  NF_Controller
 SG_ BATT_14_Placeholder16 m13 : 10|2@1+ (1,0) [0|3] ""  NF_Controller
 SG_ BATT_14_Placeholder15 m13 : 8|2@1+ (1,0) [0|3] ""  NF_Controller
 SG_ BATT_14_Placeholder14 m13 : 22|2@1+ (1,0) [0|3] ""  NF_Controller
 SG_ BATT_14_Placeholder13 m13 : 20|2@1+ (1,0) [0|3] ""  NF_Controller
 SG_ BATT_14_Placeholder02 m13 : 46|2@1+ (1,0) [0|3] ""  NF_Controller
 SG_ BATT_14_Placeholder01 m13 : 44|2@1+ (1,0) [0|3] ""  NF_Controller
 SG_ BATT_14_Placeholder12 m13 : 18|2@1+ (1,0) [0|3] ""  NF_Controller
 SG_ BATT_14_Placeholder11 m13 : 16|2@1+ (1,0) [0|3] ""  NF_Controller
 SG_ BATT_14_Placeholder10 m13 : 30|2@1+ (1,0) [0|3] ""  NF_Controller
 SG_ BATT_14_Placeholder09 m13 : 28|2@1+ (1,0) [0|3] ""  NF_Controller
 SG_ BATT_14_Placeholder08 m13 : 26|2@1+ (1,0) [0|3] ""  NF_Controller
 SG_ BATT_14_Placeholder07 m13 : 24|2@1+ (1,0) [0|3] ""  NF_Controller
 SG_ BATT_14_Placeholder06 m13 : 38|2@1+ (1,0) [0|3] ""  NF_Controller
 SG_ BATT_14_Placeholder05 m13 : 36|2@1+ (1,0) [0|3] ""  NF_Controller
 SG_ BATT_14_SpeakerMia m13 : 2|2@1+ (1,0) [0|3] ""  NF_Controller
 SG_ BATT_14_Placeholder19 m13 : 0|2@1+ (1,0) [0|3] ""  NF_Controller
 SG_ BATT_14_Placeholder18 m13 : 14|2@1+ (1,0) [0|3] ""  NF_Controller
 SG_ BATT_14_Placeholder17 m13 : 12|2@1+ (1,0) [0|3] ""  NF_Controller
 SG_ BATT_14_Placeholder04 m13 : 34|2@1+ (1,0) [0|3] ""  NF_Controller
 SG_ BATT_14_Placeholder03 m13 : 32|2@1+ (1,0) [0|3] ""  NF_Controller
 SG_ BATT_15_Placeholder16 m14 : 10|2@1+ (1,0) [0|3] ""  NF_Controller
 SG_ BATT_15_Placeholder15 m14 : 8|2@1+ (1,0) [0|3] ""  NF_Controller
 SG_ BATT_15_Placeholder14 m14 : 22|2@1+ (1,0) [0|3] ""  NF_Controller
 SG_ BATT_15_Placeholder13 m14 : 20|2@1+ (1,0) [0|3] ""  NF_Controller
 SG_ BATT_15_Placeholder02 m14 : 46|2@1+ (1,0) [0|3] ""  NF_Controller
 SG_ BATT_15_Placeholder01 m14 : 44|2@1+ (1,0) [0|3] ""  NF_Controller
 SG_ BATT_15_Placeholder12 m14 : 18|2@1+ (1,0) [0|3] ""  NF_Controller
 SG_ BATT_15_Placeholder11 m14 : 16|2@1+ (1,0) [0|3] ""  NF_Controller
 SG_ BATT_15_Placeholder10 m14 : 30|2@1+ (1,0) [0|3] ""  NF_Controller
 SG_ BATT_15_Placeholder09 m14 : 28|2@1+ (1,0) [0|3] ""  NF_Controller
 SG_ BATT_15_Placeholder08 m14 : 26|2@1+ (1,0) [0|3] ""  NF_Controller
 SG_ BATT_15_Placeholder07 m14 : 24|2@1+ (1,0) [0|3] ""  NF_Controller
 SG_ BATT_15_Placeholder06 m14 : 38|2@1+ (1,0) [0|3] ""  NF_Controller
 SG_ BATT_15_Placeholder05 m14 : 36|2@1+ (1,0) [0|3] ""  NF_Controller
 SG_ BATT_15_SpeakerMia m14 : 2|2@1+ (1,0) [0|3] ""  NF_Controller
 SG_ BATT_15_Placeholder19 m14 : 0|2@1+ (1,0) [0|3] ""  NF_Controller
 SG_ BATT_15_Placeholder18 m14 : 14|2@1+ (1,0) [0|3] ""  NF_Controller
 SG_ BATT_15_Placeholder17 m14 : 12|2@1+ (1,0) [0|3] ""  NF_Controller
 SG_ BATT_15_Placeholder04 m14 : 34|2@1+ (1,0) [0|3] ""  NF_Controller
 SG_ BATT_15_Placeholder03 m14 : 32|2@1+ (1,0) [0|3] ""  NF_Controller
 SG_ multiplexor_batt_diag_D M : 4|4@1+ (1,0) [0|15] ""  NF_Controller

BO_ 2499763044 BATT_Diagnostic_Pack_C: 8 BMS_Controller
 SG_ BATT_01_PackVoltageImbalance m0 : 58|2@1+ (1,0) [0|3] "" NF_Controller
 SG_ BATT_01_PrechargeOvercurrent m0 : 56|2@1+ (1,0) [0|3] "" NF_Controller
 SG_ BATT_01_HVILvoltageError m0 : 2|2@1+ (1,0) [0|3] ""  NF_Controller
 SG_ BATT_01_HVILcurrentReturnError m0 : 0|2@1+ (1,0) [0|3] ""  NF_Controller
 SG_ BATT_01_PosFcContWelded m0 : 14|2@1+ (1,0) [0|3] ""  NF_Controller
 SG_ BATT_01_PosFcContStuckOpen m0 : 12|2@1+ (1,0) [0|3] ""  NF_Controller
 SG_ BATT_01_NegFcContWelded m0 : 10|2@1+ (1,0) [0|3] ""  NF_Controller
 SG_ BATT_01_NegFcContStuckOpen m0 : 8|2@1+ (1,0) [0|3] ""  NF_Controller
 SG_ BATT_01_IsospiBreak m0 : 22|2@1+ (1,0) [0|3] ""  NF_Controller
 SG_ BATT_01_IsolationIntFault m0 : 20|2@1+ (1,0) [0|3] ""  NF_Controller
 SG_ BATT_01_IsolationExtFault m0 : 18|2@1+ (1,0) [0|3] ""  NF_Controller
 SG_ BATT_01_event_12v_filter_error m0 : 16|2@1+ (1,0) [0|3] ""  NF_Controller
 SG_ BATT_01_event_hall_eff_hi_rang_e m0 : 30|2@1+ (1,0) [0|3] ""  NF_Controller
 SG_ BATT_01_event_brick_volt_sns_ope m0 : 28|2@1+ (1,0) [0|3] ""  NF_Controller
 SG_ BATT_01_event_5v_error m0 : 26|2@1+ (1,0) [0|3] ""  NF_Controller
 SG_ BATT_01_event_3_3_hot_error m0 : 24|2@1+ (1,0) [0|3] ""  NF_Controller
 SG_ BATT_01_event_12v_input_error m0 : 38|2@1+ (1,0) [0|3] ""  NF_Controller
 SG_ BATT_01_event_1_25v_error m0 : 36|2@1+ (1,0) [0|3] ""  NF_Controller
 SG_ BATT_01_event_shunt_MIA m0 : 34|2@1+ (1,0) [0|3] ""  NF_Controller
 SG_ BATT_01_event_SBC_int_reg_error m0 : 32|2@1+ (1,0) [0|3] ""  NF_Controller
 SG_ BATT_01_event_pos_3_3v_analog_er m0 : 46|2@1+ (1,0) [0|3] ""  NF_Controller
 SG_ BATT_01_event_outlt_clnt_thrm_op m0 : 44|2@1+ (1,0) [0|3] ""  NF_Controller
 SG_ BATT_01_event_neg_3_3_analog_err m0 : 42|2@1+ (1,0) [0|3] ""  NF_Controller
 SG_ BATT_01_event_inlet_clnt_thrm_op m0 : 40|2@1+ (1,0) [0|3] ""  NF_Controller
 SG_ BATT_01_event_hall_eff_lo_rang_e m0 : 54|2@1+ (1,0) [0|3] ""  NF_Controller
 SG_ BATT_01_event_outlt_clnt_thrm_sh m0 : 52|2@1+ (1,0) [0|3] ""  NF_Controller
 SG_ BATT_01_event_inlet_clnt_thrm_sh m0 : 50|2@1+ (1,0) [0|3] ""  NF_Controller
 SG_ BATT_01_event_3_3v_error m0 : 48|2@1+ (1,0) [0|3] ""  NF_Controller
 SG_ BATT_02_PackVoltageImbalance m1 : 58|2@1+ (1,0) [0|3] "" NF_Controller
 SG_ BATT_02_PrechargeOvercurrent m1 : 56|2@1+ (1,0) [0|3] "" NF_Controller
 SG_ BATT_02_HVILvoltageError m1 : 2|2@1+ (1,0) [0|3] ""  NF_Controller
 SG_ BATT_02_HVILcurrentReturnError m1 : 0|2@1+ (1,0) [0|3] ""  NF_Controller
 SG_ BATT_02_PosFcContWelded m1 : 14|2@1+ (1,0) [0|3] ""  NF_Controller
 SG_ BATT_02_PosFcContStuckOpen m1 : 12|2@1+ (1,0) [0|3] ""  NF_Controller
 SG_ BATT_02_NegFcContWelded m1 : 10|2@1+ (1,0) [0|3] ""  NF_Controller
 SG_ BATT_02_NegFcContStuckOpen m1 : 8|2@1+ (1,0) [0|3] ""  NF_Controller
 SG_ BATT_02_IsospiBreak m1 : 22|2@1+ (1,0) [0|3] ""  NF_Controller
 SG_ BATT_02_IsolationIntFault m1 : 20|2@1+ (1,0) [0|3] ""  NF_Controller
 SG_ BATT_02_IsolationExtFault m1 : 18|2@1+ (1,0) [0|3] ""  NF_Controller
 SG_ BATT_02_event_12v_filter_error m1 : 16|2@1+ (1,0) [0|3] ""  NF_Controller
 SG_ BATT_02_event_hall_eff_hi_rang_e m1 : 30|2@1+ (1,0) [0|3] ""  NF_Controller
 SG_ BATT_02_event_brick_volt_sns_ope m1 : 28|2@1+ (1,0) [0|3] ""  NF_Controller
 SG_ BATT_02_event_5v_error m1 : 26|2@1+ (1,0) [0|3] ""  NF_Controller
 SG_ BATT_02_event_3_3_hot_error m1 : 24|2@1+ (1,0) [0|3] ""  NF_Controller
 SG_ BATT_02_event_12v_input_error m1 : 38|2@1+ (1,0) [0|3] ""  NF_Controller
 SG_ BATT_02_event_1_25v_error m1 : 36|2@1+ (1,0) [0|3] ""  NF_Controller
 SG_ BATT_02_event_shunt_MIA m1 : 34|2@1+ (1,0) [0|3] ""  NF_Controller
 SG_ BATT_02_event_SBC_int_reg_error m1 : 32|2@1+ (1,0) [0|3] ""  NF_Controller
 SG_ BATT_02_event_pos_3_3v_analog_er m1 : 46|2@1+ (1,0) [0|3] ""  NF_Controller
 SG_ BATT_02_event_outlt_clnt_thrm_op m1 : 44|2@1+ (1,0) [0|3] ""  NF_Controller
 SG_ BATT_02_event_neg_3_3_analog_err m1 : 42|2@1+ (1,0) [0|3] ""  NF_Controller
 SG_ BATT_02_event_inlet_clnt_thrm_op m1 : 40|2@1+ (1,0) [0|3] ""  NF_Controller
 SG_ BATT_02_event_hall_eff_lo_rang_e m1 : 54|2@1+ (1,0) [0|3] ""  NF_Controller
 SG_ BATT_02_event_outlt_clnt_thrm_sh m1 : 52|2@1+ (1,0) [0|3] ""  NF_Controller
 SG_ BATT_02_event_inlet_clnt_thrm_sh m1 : 50|2@1+ (1,0) [0|3] ""  NF_Controller
 SG_ BATT_02_event_3_3v_error m1 : 48|2@1+ (1,0) [0|3] ""  NF_Controller
 SG_ BATT_03_PackVoltageImbalance m2 : 58|2@1+ (1,0) [0|3] "" NF_Controller
 SG_ BATT_03_PrechargeOvercurrent m2 : 56|2@1+ (1,0) [0|3] "" NF_Controller
 SG_ BATT_03_HVILvoltageError m2 : 2|2@1+ (1,0) [0|3] ""  NF_Controller
 SG_ BATT_03_HVILcurrentReturnError m2 : 0|2@1+ (1,0) [0|3] ""  NF_Controller
 SG_ BATT_03_PosFcContWelded m2 : 14|2@1+ (1,0) [0|3] ""  NF_Controller
 SG_ BATT_03_PosFcContStuckOpen m2 : 12|2@1+ (1,0) [0|3] ""  NF_Controller
 SG_ BATT_03_NegFcContWelded m2 : 10|2@1+ (1,0) [0|3] ""  NF_Controller
 SG_ BATT_03_NegFcContStuckOpen m2 : 8|2@1+ (1,0) [0|3] ""  NF_Controller
 SG_ BATT_03_IsospiBreak m2 : 22|2@1+ (1,0) [0|3] ""  NF_Controller
 SG_ BATT_03_IsolationIntFault m2 : 20|2@1+ (1,0) [0|3] ""  NF_Controller
 SG_ BATT_03_IsolationExtFault m2 : 18|2@1+ (1,0) [0|3] ""  NF_Controller
 SG_ BATT_03_event_12v_filter_error m2 : 16|2@1+ (1,0) [0|3] ""  NF_Controller
 SG_ BATT_03_event_hall_eff_hi_rang_e m2 : 30|2@1+ (1,0) [0|3] ""  NF_Controller
 SG_ BATT_03_event_brick_volt_sns_ope m2 : 28|2@1+ (1,0) [0|3] ""  NF_Controller
 SG_ BATT_03_event_5v_error m2 : 26|2@1+ (1,0) [0|3] ""  NF_Controller
 SG_ BATT_03_event_3_3_hot_error m2 : 24|2@1+ (1,0) [0|3] ""  NF_Controller
 SG_ BATT_03_event_12v_input_error m2 : 38|2@1+ (1,0) [0|3] ""  NF_Controller
 SG_ BATT_03_event_1_25v_error m2 : 36|2@1+ (1,0) [0|3] ""  NF_Controller
 SG_ BATT_03_event_shunt_MIA m2 : 34|2@1+ (1,0) [0|3] ""  NF_Controller
 SG_ BATT_03_event_SBC_int_reg_error m2 : 32|2@1+ (1,0) [0|3] ""  NF_Controller
 SG_ BATT_03_event_pos_3_3v_analog_er m2 : 46|2@1+ (1,0) [0|3] ""  NF_Controller
 SG_ BATT_03_event_outlt_clnt_thrm_op m2 : 44|2@1+ (1,0) [0|3] ""  NF_Controller
 SG_ BATT_03_event_neg_3_3_analog_err m2 : 42|2@1+ (1,0) [0|3] ""  NF_Controller
 SG_ BATT_03_event_inlet_clnt_thrm_op m2 : 40|2@1+ (1,0) [0|3] ""  NF_Controller
 SG_ BATT_03_event_hall_eff_lo_rang_e m2 : 54|2@1+ (1,0) [0|3] ""  NF_Controller
 SG_ BATT_03_event_outlt_clnt_thrm_sh m2 : 52|2@1+ (1,0) [0|3] ""  NF_Controller
 SG_ BATT_03_event_inlet_clnt_thrm_sh m2 : 50|2@1+ (1,0) [0|3] ""  NF_Controller
 SG_ BATT_03_event_3_3v_error m2 : 48|2@1+ (1,0) [0|3] ""  NF_Controller
 SG_ BATT_04_PackVoltageImbalance m3 : 58|2@1+ (1,0) [0|3] "" NF_Controller
 SG_ BATT_04_PrechargeOvercurrent m3 : 56|2@1+ (1,0) [0|3] "" NF_Controller
 SG_ BATT_04_HVILvoltageError m3 : 2|2@1+ (1,0) [0|3] ""  NF_Controller
 SG_ BATT_04_HVILcurrentReturnError m3 : 0|2@1+ (1,0) [0|3] ""  NF_Controller
 SG_ BATT_04_PosFcContWelded m3 : 14|2@1+ (1,0) [0|3] ""  NF_Controller
 SG_ BATT_04_PosFcContStuckOpen m3 : 12|2@1+ (1,0) [0|3] ""  NF_Controller
 SG_ BATT_04_NegFcContWelded m3 : 10|2@1+ (1,0) [0|3] ""  NF_Controller
 SG_ BATT_04_NegFcContStuckOpen m3 : 8|2@1+ (1,0) [0|3] ""  NF_Controller
 SG_ BATT_04_IsospiBreak m3 : 22|2@1+ (1,0) [0|3] ""  NF_Controller
 SG_ BATT_04_IsolationIntFault m3 : 20|2@1+ (1,0) [0|3] ""  NF_Controller
 SG_ BATT_04_IsolationExtFault m3 : 18|2@1+ (1,0) [0|3] ""  NF_Controller
 SG_ BATT_04_event_12v_filter_error m3 : 16|2@1+ (1,0) [0|3] ""  NF_Controller
 SG_ BATT_04_event_hall_eff_hi_rang_e m3 : 30|2@1+ (1,0) [0|3] ""  NF_Controller
 SG_ BATT_04_event_brick_volt_sns_ope m3 : 28|2@1+ (1,0) [0|3] ""  NF_Controller
 SG_ BATT_04_event_5v_error m3 : 26|2@1+ (1,0) [0|3] ""  NF_Controller
 SG_ BATT_04_event_3_3_hot_error m3 : 24|2@1+ (1,0) [0|3] ""  NF_Controller
 SG_ BATT_04_event_12v_input_error m3 : 38|2@1+ (1,0) [0|3] ""  NF_Controller
 SG_ BATT_04_event_1_25v_error m3 : 36|2@1+ (1,0) [0|3] ""  NF_Controller
 SG_ BATT_04_event_shunt_MIA m3 : 34|2@1+ (1,0) [0|3] ""  NF_Controller
 SG_ BATT_04_event_SBC_int_reg_error m3 : 32|2@1+ (1,0) [0|3] ""  NF_Controller
 SG_ BATT_04_event_pos_3_3v_analog_er m3 : 46|2@1+ (1,0) [0|3] ""  NF_Controller
 SG_ BATT_04_event_outlt_clnt_thrm_op m3 : 44|2@1+ (1,0) [0|3] ""  NF_Controller
 SG_ BATT_04_event_neg_3_3_analog_err m3 : 42|2@1+ (1,0) [0|3] ""  NF_Controller
 SG_ BATT_04_event_inlet_clnt_thrm_op m3 : 40|2@1+ (1,0) [0|3] ""  NF_Controller
 SG_ BATT_04_event_hall_eff_lo_rang_e m3 : 54|2@1+ (1,0) [0|3] ""  NF_Controller
 SG_ BATT_04_event_outlt_clnt_thrm_sh m3 : 52|2@1+ (1,0) [0|3] ""  NF_Controller
 SG_ BATT_04_event_inlet_clnt_thrm_sh m3 : 50|2@1+ (1,0) [0|3] ""  NF_Controller
 SG_ BATT_04_event_3_3v_error m3 : 48|2@1+ (1,0) [0|3] ""  NF_Controller
 SG_ BATT_05_PackVoltageImbalance m4 : 58|2@1+ (1,0) [0|3] "" NF_Controller
 SG_ BATT_05_PrechargeOvercurrent m4 : 56|2@1+ (1,0) [0|3] "" NF_Controller
 SG_ BATT_05_HVILvoltageError m4 : 2|2@1+ (1,0) [0|3] ""  NF_Controller
 SG_ BATT_05_HVILcurrentReturnError m4 : 0|2@1+ (1,0) [0|3] ""  NF_Controller
 SG_ BATT_05_PosFcContWelded m4 : 14|2@1+ (1,0) [0|3] ""  NF_Controller
 SG_ BATT_05_PosFcContStuckOpen m4 : 12|2@1+ (1,0) [0|3] ""  NF_Controller
 SG_ BATT_05_NegFcContWelded m4 : 10|2@1+ (1,0) [0|3] ""  NF_Controller
 SG_ BATT_05_NegFcContStuckOpen m4 : 8|2@1+ (1,0) [0|3] ""  NF_Controller
 SG_ BATT_05_IsospiBreak m4 : 22|2@1+ (1,0) [0|3] ""  NF_Controller
 SG_ BATT_05_IsolationIntFault m4 : 20|2@1+ (1,0) [0|3] ""  NF_Controller
 SG_ BATT_05_IsolationExtFault m4 : 18|2@1+ (1,0) [0|3] ""  NF_Controller
 SG_ BATT_05_event_12v_filter_error m4 : 16|2@1+ (1,0) [0|3] ""  NF_Controller
 SG_ BATT_05_event_hall_eff_hi_rang_e m4 : 30|2@1+ (1,0) [0|3] ""  NF_Controller
 SG_ BATT_05_event_brick_volt_sns_ope m4 : 28|2@1+ (1,0) [0|3] ""  NF_Controller
 SG_ BATT_05_event_5v_error m4 : 26|2@1+ (1,0) [0|3] ""  NF_Controller
 SG_ BATT_05_event_3_3_hot_error m4 : 24|2@1+ (1,0) [0|3] ""  NF_Controller
 SG_ BATT_05_event_12v_input_error m4 : 38|2@1+ (1,0) [0|3] ""  NF_Controller
 SG_ BATT_05_event_1_25v_error m4 : 36|2@1+ (1,0) [0|3] ""  NF_Controller
 SG_ BATT_05_event_shunt_MIA m4 : 34|2@1+ (1,0) [0|3] ""  NF_Controller
 SG_ BATT_05_event_SBC_int_reg_error m4 : 32|2@1+ (1,0) [0|3] ""  NF_Controller
 SG_ BATT_05_event_pos_3_3v_analog_er m4 : 46|2@1+ (1,0) [0|3] ""  NF_Controller
 SG_ BATT_05_event_outlt_clnt_thrm_op m4 : 44|2@1+ (1,0) [0|3] ""  NF_Controller
 SG_ BATT_05_event_neg_3_3_analog_err m4 : 42|2@1+ (1,0) [0|3] ""  NF_Controller
 SG_ BATT_05_event_inlet_clnt_thrm_op m4 : 40|2@1+ (1,0) [0|3] ""  NF_Controller
 SG_ BATT_05_event_hall_eff_lo_rang_e m4 : 54|2@1+ (1,0) [0|3] ""  NF_Controller
 SG_ BATT_05_event_outlt_clnt_thrm_sh m4 : 52|2@1+ (1,0) [0|3] ""  NF_Controller
 SG_ BATT_05_event_inlet_clnt_thrm_sh m4 : 50|2@1+ (1,0) [0|3] ""  NF_Controller
 SG_ BATT_05_event_3_3v_error m4 : 48|2@1+ (1,0) [0|3] ""  NF_Controller
 SG_ BATT_06_PackVoltageImbalance m5 : 58|2@1+ (1,0) [0|3] "" NF_Controller
 SG_ BATT_06_PrechargeOvercurrent m5 : 56|2@1+ (1,0) [0|3] "" NF_Controller
 SG_ BATT_06_HVILvoltageError m5 : 2|2@1+ (1,0) [0|3] ""  NF_Controller
 SG_ BATT_06_HVILcurrentReturnError m5 : 0|2@1+ (1,0) [0|3] ""  NF_Controller
 SG_ BATT_06_PosFcContWelded m5 : 14|2@1+ (1,0) [0|3] ""  NF_Controller
 SG_ BATT_06_PosFcContStuckOpen m5 : 12|2@1+ (1,0) [0|3] ""  NF_Controller
 SG_ BATT_06_NegFcContWelded m5 : 10|2@1+ (1,0) [0|3] ""  NF_Controller
 SG_ BATT_06_NegFcContStuckOpen m5 : 8|2@1+ (1,0) [0|3] ""  NF_Controller
 SG_ BATT_06_IsospiBreak m5 : 22|2@1+ (1,0) [0|3] ""  NF_Controller
 SG_ BATT_06_IsolationIntFault m5 : 20|2@1+ (1,0) [0|3] ""  NF_Controller
 SG_ BATT_06_IsolationExtFault m5 : 18|2@1+ (1,0) [0|3] ""  NF_Controller
 SG_ BATT_06_event_12v_filter_error m5 : 16|2@1+ (1,0) [0|3] ""  NF_Controller
 SG_ BATT_06_event_hall_eff_hi_rang_e m5 : 30|2@1+ (1,0) [0|3] ""  NF_Controller
 SG_ BATT_06_event_brick_volt_sns_ope m5 : 28|2@1+ (1,0) [0|3] ""  NF_Controller
 SG_ BATT_06_event_5v_error m5 : 26|2@1+ (1,0) [0|3] ""  NF_Controller
 SG_ BATT_06_event_3_3_hot_error m5 : 24|2@1+ (1,0) [0|3] ""  NF_Controller
 SG_ BATT_06_event_12v_input_error m5 : 38|2@1+ (1,0) [0|3] ""  NF_Controller
 SG_ BATT_06_event_1_25v_error m5 : 36|2@1+ (1,0) [0|3] ""  NF_Controller
 SG_ BATT_06_event_shunt_MIA m5 : 34|2@1+ (1,0) [0|3] ""  NF_Controller
 SG_ BATT_06_event_SBC_int_reg_error m5 : 32|2@1+ (1,0) [0|3] ""  NF_Controller
 SG_ BATT_06_event_pos_3_3v_analog_er m5 : 46|2@1+ (1,0) [0|3] ""  NF_Controller
 SG_ BATT_06_event_outlt_clnt_thrm_op m5 : 44|2@1+ (1,0) [0|3] ""  NF_Controller
 SG_ BATT_06_event_neg_3_3_analog_err m5 : 42|2@1+ (1,0) [0|3] ""  NF_Controller
 SG_ BATT_06_event_inlet_clnt_thrm_op m5 : 40|2@1+ (1,0) [0|3] ""  NF_Controller
 SG_ BATT_06_event_hall_eff_lo_rang_e m5 : 54|2@1+ (1,0) [0|3] ""  NF_Controller
 SG_ BATT_06_event_outlt_clnt_thrm_sh m5 : 52|2@1+ (1,0) [0|3] ""  NF_Controller
 SG_ BATT_06_event_inlet_clnt_thrm_sh m5 : 50|2@1+ (1,0) [0|3] ""  NF_Controller
 SG_ BATT_06_event_3_3v_error m5 : 48|2@1+ (1,0) [0|3] ""  NF_Controller
 SG_ BATT_07_PackVoltageImbalance m6 : 58|2@1+ (1,0) [0|3] "" NF_Controller
 SG_ BATT_07_PrechargeOvercurrent m6 : 56|2@1+ (1,0) [0|3] "" NF_Controller
 SG_ BATT_07_HVILvoltageError m6 : 2|2@1+ (1,0) [0|3] ""  NF_Controller
 SG_ BATT_07_HVILcurrentReturnError m6 : 0|2@1+ (1,0) [0|3] ""  NF_Controller
 SG_ BATT_07_PosFcContWelded m6 : 14|2@1+ (1,0) [0|3] ""  NF_Controller
 SG_ BATT_07_PosFcContStuckOpen m6 : 12|2@1+ (1,0) [0|3] ""  NF_Controller
 SG_ BATT_07_NegFcContWelded m6 : 10|2@1+ (1,0) [0|3] ""  NF_Controller
 SG_ BATT_07_NegFcContStuckOpen m6 : 8|2@1+ (1,0) [0|3] ""  NF_Controller
 SG_ BATT_07_IsospiBreak m6 : 22|2@1+ (1,0) [0|3] ""  NF_Controller
 SG_ BATT_07_IsolationIntFault m6 : 20|2@1+ (1,0) [0|3] ""  NF_Controller
 SG_ BATT_07_IsolationExtFault m6 : 18|2@1+ (1,0) [0|3] ""  NF_Controller
 SG_ BATT_07_event_12v_filter_error m6 : 16|2@1+ (1,0) [0|3] ""  NF_Controller
 SG_ BATT_07_event_hall_eff_hi_rang_e m6 : 30|2@1+ (1,0) [0|3] ""  NF_Controller
 SG_ BATT_07_event_brick_volt_sns_ope m6 : 28|2@1+ (1,0) [0|3] ""  NF_Controller
 SG_ BATT_07_event_5v_error m6 : 26|2@1+ (1,0) [0|3] ""  NF_Controller
 SG_ BATT_07_event_3_3_hot_error m6 : 24|2@1+ (1,0) [0|3] ""  NF_Controller
 SG_ BATT_07_event_12v_input_error m6 : 38|2@1+ (1,0) [0|3] ""  NF_Controller
 SG_ BATT_07_event_1_25v_error m6 : 36|2@1+ (1,0) [0|3] ""  NF_Controller
 SG_ BATT_07_event_shunt_MIA m6 : 34|2@1+ (1,0) [0|3] ""  NF_Controller
 SG_ BATT_07_event_SBC_int_reg_error m6 : 32|2@1+ (1,0) [0|3] ""  NF_Controller
 SG_ BATT_07_event_pos_3_3v_analog_er m6 : 46|2@1+ (1,0) [0|3] ""  NF_Controller
 SG_ BATT_07_event_outlt_clnt_thrm_op m6 : 44|2@1+ (1,0) [0|3] ""  NF_Controller
 SG_ BATT_07_event_neg_3_3_analog_err m6 : 42|2@1+ (1,0) [0|3] ""  NF_Controller
 SG_ BATT_07_event_inlet_clnt_thrm_op m6 : 40|2@1+ (1,0) [0|3] ""  NF_Controller
 SG_ BATT_07_event_hall_eff_lo_rang_e m6 : 54|2@1+ (1,0) [0|3] ""  NF_Controller
 SG_ BATT_07_event_outlt_clnt_thrm_sh m6 : 52|2@1+ (1,0) [0|3] ""  NF_Controller
 SG_ BATT_07_event_inlet_clnt_thrm_sh m6 : 50|2@1+ (1,0) [0|3] ""  NF_Controller
 SG_ BATT_07_event_3_3v_error m6 : 48|2@1+ (1,0) [0|3] ""  NF_Controller
 SG_ BATT_08_PackVoltageImbalance m7 : 58|2@1+ (1,0) [0|3] "" NF_Controller
 SG_ BATT_08_PrechargeOvercurrent m7 : 56|2@1+ (1,0) [0|3] "" NF_Controller
 SG_ BATT_08_HVILvoltageError m7 : 2|2@1+ (1,0) [0|3] ""  NF_Controller
 SG_ BATT_08_HVILcurrentReturnError m7 : 0|2@1+ (1,0) [0|3] ""  NF_Controller
 SG_ BATT_08_PosFcContWelded m7 : 14|2@1+ (1,0) [0|3] ""  NF_Controller
 SG_ BATT_08_PosFcContStuckOpen m7 : 12|2@1+ (1,0) [0|3] ""  NF_Controller
 SG_ BATT_08_NegFcContWelded m7 : 10|2@1+ (1,0) [0|3] ""  NF_Controller
 SG_ BATT_08_NegFcContStuckOpen m7 : 8|2@1+ (1,0) [0|3] ""  NF_Controller
 SG_ BATT_08_IsospiBreak m7 : 22|2@1+ (1,0) [0|3] ""  NF_Controller
 SG_ BATT_08_IsolationIntFault m7 : 20|2@1+ (1,0) [0|3] ""  NF_Controller
 SG_ BATT_08_IsolationExtFault m7 : 18|2@1+ (1,0) [0|3] ""  NF_Controller
 SG_ BATT_08_event_12v_filter_error m7 : 16|2@1+ (1,0) [0|3] ""  NF_Controller
 SG_ BATT_08_event_hall_eff_hi_rang_e m7 : 30|2@1+ (1,0) [0|3] ""  NF_Controller
 SG_ BATT_08_event_brick_volt_sns_ope m7 : 28|2@1+ (1,0) [0|3] ""  NF_Controller
 SG_ BATT_08_event_5v_error m7 : 26|2@1+ (1,0) [0|3] ""  NF_Controller
 SG_ BATT_08_event_3_3_hot_error m7 : 24|2@1+ (1,0) [0|3] ""  NF_Controller
 SG_ BATT_08_event_12v_input_error m7 : 38|2@1+ (1,0) [0|3] ""  NF_Controller
 SG_ BATT_08_event_1_25v_error m7 : 36|2@1+ (1,0) [0|3] ""  NF_Controller
 SG_ BATT_08_event_shunt_MIA m7 : 34|2@1+ (1,0) [0|3] ""  NF_Controller
 SG_ BATT_08_event_SBC_int_reg_error m7 : 32|2@1+ (1,0) [0|3] ""  NF_Controller
 SG_ BATT_08_event_pos_3_3v_analog_er m7 : 46|2@1+ (1,0) [0|3] ""  NF_Controller
 SG_ BATT_08_event_outlt_clnt_thrm_op m7 : 44|2@1+ (1,0) [0|3] ""  NF_Controller
 SG_ BATT_08_event_neg_3_3_analog_err m7 : 42|2@1+ (1,0) [0|3] ""  NF_Controller
 SG_ BATT_08_event_inlet_clnt_thrm_op m7 : 40|2@1+ (1,0) [0|3] ""  NF_Controller
 SG_ BATT_08_event_hall_eff_lo_rang_e m7 : 54|2@1+ (1,0) [0|3] ""  NF_Controller
 SG_ BATT_08_event_outlt_clnt_thrm_sh m7 : 52|2@1+ (1,0) [0|3] ""  NF_Controller
 SG_ BATT_08_event_inlet_clnt_thrm_sh m7 : 50|2@1+ (1,0) [0|3] ""  NF_Controller
 SG_ BATT_08_event_3_3v_error m7 : 48|2@1+ (1,0) [0|3] ""  NF_Controller
 SG_ BATT_09_PackVoltageImbalance m8 : 58|2@1+ (1,0) [0|3] "" NF_Controller
 SG_ BATT_09_PrechargeOvercurrent m8 : 56|2@1+ (1,0) [0|3] "" NF_Controller
 SG_ BATT_09_HVILvoltageError m8 : 2|2@1+ (1,0) [0|3] ""  NF_Controller
 SG_ BATT_09_HVILcurrentReturnError m8 : 0|2@1+ (1,0) [0|3] ""  NF_Controller
 SG_ BATT_09_PosFcContWelded m8 : 14|2@1+ (1,0) [0|3] ""  NF_Controller
 SG_ BATT_09_NegFcContWelded m8 : 10|2@1+ (1,0) [0|3] ""  NF_Controller
 SG_ BATT_09_NegFcContStuckOpen m8 : 8|2@1+ (1,0) [0|3] ""  NF_Controller
 SG_ BATT_09_PosFcContStuckOpen m8 : 12|2@1+ (1,0) [0|3] ""  NF_Controller
 SG_ BATT_09_IsospiBreak m8 : 22|2@1+ (1,0) [0|3] ""  NF_Controller
 SG_ BATT_09_IsolationIntFault m8 : 20|2@1+ (1,0) [0|3] ""  NF_Controller
 SG_ BATT_09_IsolationExtFault m8 : 18|2@1+ (1,0) [0|3] ""  NF_Controller
 SG_ BATT_09_event_12v_filter_error m8 : 16|2@1+ (1,0) [0|3] ""  NF_Controller
 SG_ BATT_09_event_hall_eff_hi_rang_e m8 : 30|2@1+ (1,0) [0|3] ""  NF_Controller
 SG_ BATT_09_event_brick_volt_sns_ope m8 : 28|2@1+ (1,0) [0|3] ""  NF_Controller
 SG_ BATT_09_event_5v_error m8 : 26|2@1+ (1,0) [0|3] ""  NF_Controller
 SG_ BATT_09_event_3_3_hot_error m8 : 24|2@1+ (1,0) [0|3] ""  NF_Controller
 SG_ BATT_09_event_12v_input_error m8 : 38|2@1+ (1,0) [0|3] ""  NF_Controller
 SG_ BATT_09_event_1_25v_error m8 : 36|2@1+ (1,0) [0|3] ""  NF_Controller
 SG_ BATT_09_event_shunt_MIA m8 : 34|2@1+ (1,0) [0|3] ""  NF_Controller
 SG_ BATT_09_event_SBC_int_reg_error m8 : 32|2@1+ (1,0) [0|3] ""  NF_Controller
 SG_ BATT_09_event_pos_3_3v_analog_er m8 : 46|2@1+ (1,0) [0|3] ""  NF_Controller
 SG_ BATT_09_event_outlt_clnt_thrm_op m8 : 44|2@1+ (1,0) [0|3] ""  NF_Controller
 SG_ BATT_09_event_neg_3_3_analog_err m8 : 42|2@1+ (1,0) [0|3] ""  NF_Controller
 SG_ BATT_09_event_inlet_clnt_thrm_op m8 : 40|2@1+ (1,0) [0|3] ""  NF_Controller
 SG_ BATT_09_event_hall_eff_lo_rang_e m8 : 54|2@1+ (1,0) [0|3] ""  NF_Controller
 SG_ BATT_09_event_outlt_clnt_thrm_sh m8 : 52|2@1+ (1,0) [0|3] ""  NF_Controller
 SG_ BATT_09_event_inlet_clnt_thrm_sh m8 : 50|2@1+ (1,0) [0|3] ""  NF_Controller
 SG_ BATT_09_event_3_3v_error m8 : 48|2@1+ (1,0) [0|3] ""  NF_Controller
 SG_ BATT_10_PackVoltageImbalance m9 : 58|2@1+ (1,0) [0|3] "" NF_Controller
 SG_ BATT_10_PrechargeOvercurrent m9 : 56|2@1+ (1,0) [0|3] "" NF_Controller
 SG_ BATT_10_HVILvoltageError m9 : 2|2@1+ (1,0) [0|3] ""  NF_Controller
 SG_ BATT_10_HVILcurrentReturnError m9 : 0|2@1+ (1,0) [0|3] ""  NF_Controller
 SG_ BATT_10_PosFcContWelded m9 : 14|2@1+ (1,0) [0|3] ""  NF_Controller
 SG_ BATT_10_PosFcContStuckOpen m9 : 12|2@1+ (1,0) [0|3] ""  NF_Controller
 SG_ BATT_10_NegFcContWelded m9 : 10|2@1+ (1,0) [0|3] ""  NF_Controller
 SG_ BATT_10_NegFcContStuckOpen m9 : 8|2@1+ (1,0) [0|3] ""  NF_Controller
 SG_ BATT_10_IsospiBreak m9 : 22|2@1+ (1,0) [0|3] ""  NF_Controller
 SG_ BATT_10_IsolationIntFault m9 : 20|2@1+ (1,0) [0|3] ""  NF_Controller
 SG_ BATT_10_IsolationExtFault m9 : 18|2@1+ (1,0) [0|3] ""  NF_Controller
 SG_ BATT_10_event_12v_filter_error m9 : 16|2@1+ (1,0) [0|3] ""  NF_Controller
 SG_ BATT_10_event_hall_eff_hi_rang_e m9 : 30|2@1+ (1,0) [0|3] ""  NF_Controller
 SG_ BATT_10_event_brick_volt_sns_ope m9 : 28|2@1+ (1,0) [0|3] ""  NF_Controller
 SG_ BATT_10_event_5v_error m9 : 26|2@1+ (1,0) [0|3] ""  NF_Controller
 SG_ BATT_10_event_3_3_hot_error m9 : 24|2@1+ (1,0) [0|3] ""  NF_Controller
 SG_ BATT_10_event_12v_input_error m9 : 38|2@1+ (1,0) [0|3] ""  NF_Controller
 SG_ BATT_10_event_1_25v_error m9 : 36|2@1+ (1,0) [0|3] ""  NF_Controller
 SG_ BATT_10_event_shunt_MIA m9 : 34|2@1+ (1,0) [0|3] ""  NF_Controller
 SG_ BATT_10_event_SBC_int_reg_error m9 : 32|2@1+ (1,0) [0|3] ""  NF_Controller
 SG_ BATT_10_event_pos_3_3v_analog_er m9 : 46|2@1+ (1,0) [0|3] ""  NF_Controller
 SG_ BATT_10_event_outlt_clnt_thrm_op m9 : 44|2@1+ (1,0) [0|3] ""  NF_Controller
 SG_ BATT_10_event_neg_3_3_analog_err m9 : 42|2@1+ (1,0) [0|3] ""  NF_Controller
 SG_ BATT_10_event_inlet_clnt_thrm_op m9 : 40|2@1+ (1,0) [0|3] ""  NF_Controller
 SG_ BATT_10_event_hall_eff_lo_rang_e m9 : 54|2@1+ (1,0) [0|3] ""  NF_Controller
 SG_ BATT_10_event_outlt_clnt_thrm_sh m9 : 52|2@1+ (1,0) [0|3] ""  NF_Controller
 SG_ BATT_10_event_inlet_clnt_thrm_sh m9 : 50|2@1+ (1,0) [0|3] ""  NF_Controller
 SG_ BATT_10_event_3_3v_error m9 : 48|2@1+ (1,0) [0|3] ""  NF_Controller
 SG_ BATT_11_PackVoltageImbalance m10 : 58|2@1+ (1,0) [0|3] "" NF_Controller
 SG_ BATT_11_PrechargeOvercurrent m10 : 56|2@1+ (1,0) [0|3] "" NF_Controller
 SG_ BATT_11_HVILvoltageError m10 : 2|2@1+ (1,0) [0|3] ""  NF_Controller
 SG_ BATT_11_HVILcurrentReturnError m10 : 0|2@1+ (1,0) [0|3] ""  NF_Controller
 SG_ BATT_11_PosFcContWelded m10 : 14|2@1+ (1,0) [0|3] ""  NF_Controller
 SG_ BATT_11_PosFcContStuckOpen m10 : 12|2@1+ (1,0) [0|3] ""  NF_Controller
 SG_ BATT_11_NegFcContWelded m10 : 10|2@1+ (1,0) [0|3] ""  NF_Controller
 SG_ BATT_11_NegFcContStuckOpen m10 : 8|2@1+ (1,0) [0|3] ""  NF_Controller
 SG_ BATT_11_IsospiBreak m10 : 22|2@1+ (1,0) [0|3] ""  NF_Controller
 SG_ BATT_11_IsolationIntFault m10 : 20|2@1+ (1,0) [0|3] ""  NF_Controller
 SG_ BATT_11_IsolationExtFault m10 : 18|2@1+ (1,0) [0|3] ""  NF_Controller
 SG_ BATT_11_event_12v_filter_error m10 : 16|2@1+ (1,0) [0|3] ""  NF_Controller
 SG_ BATT_11_event_hall_eff_hi_rang_e m10 : 30|2@1+ (1,0) [0|3] ""  NF_Controller
 SG_ BATT_11_event_brick_volt_sns_ope m10 : 28|2@1+ (1,0) [0|3] ""  NF_Controller
 SG_ BATT_11_event_5v_error m10 : 26|2@1+ (1,0) [0|3] ""  NF_Controller
 SG_ BATT_11_event_3_3_hot_error m10 : 24|2@1+ (1,0) [0|3] ""  NF_Controller
 SG_ BATT_11_event_12v_input_error m10 : 38|2@1+ (1,0) [0|3] ""  NF_Controller
 SG_ BATT_11_event_1_25v_error m10 : 36|2@1+ (1,0) [0|3] ""  NF_Controller
 SG_ BATT_11_event_shunt_MIA m10 : 34|2@1+ (1,0) [0|3] ""  NF_Controller
 SG_ BATT_11_event_SBC_int_reg_error m10 : 32|2@1+ (1,0) [0|3] ""  NF_Controller
 SG_ BATT_11_event_pos_3_3v_analog_er m10 : 46|2@1+ (1,0) [0|3] ""  NF_Controller
 SG_ BATT_11_event_outlt_clnt_thrm_op m10 : 44|2@1+ (1,0) [0|3] ""  NF_Controller
 SG_ BATT_11_event_neg_3_3_analog_err m10 : 42|2@1+ (1,0) [0|3] ""  NF_Controller
 SG_ BATT_11_event_inlet_clnt_thrm_op m10 : 40|2@1+ (1,0) [0|3] ""  NF_Controller
 SG_ BATT_11_event_hall_eff_lo_rang_e m10 : 54|2@1+ (1,0) [0|3] ""  NF_Controller
 SG_ BATT_11_event_outlt_clnt_thrm_sh m10 : 52|2@1+ (1,0) [0|3] ""  NF_Controller
 SG_ BATT_11_event_inlet_clnt_thrm_sh m10 : 50|2@1+ (1,0) [0|3] ""  NF_Controller
 SG_ BATT_11_event_3_3v_error m10 : 48|2@1+ (1,0) [0|3] ""  NF_Controller
 SG_ BATT_12_PackVoltageImbalance m11 : 58|2@1+ (1,0) [0|3] "" NF_Controller
 SG_ BATT_12_PrechargeOvercurrent m11 : 56|2@1+ (1,0) [0|3] "" NF_Controller
 SG_ BATT_12_HVILvoltageError m11 : 2|2@1+ (1,0) [0|3] ""  NF_Controller
 SG_ BATT_12_HVILcurrentReturnError m11 : 0|2@1+ (1,0) [0|3] ""  NF_Controller
 SG_ BATT_12_PosFcContWelded m11 : 14|2@1+ (1,0) [0|3] ""  NF_Controller
 SG_ BATT_12_PosFcContStuckOpen m11 : 12|2@1+ (1,0) [0|3] ""  NF_Controller
 SG_ BATT_12_NegFcContWelded m11 : 10|2@1+ (1,0) [0|3] ""  NF_Controller
 SG_ BATT_12_NegFcContStuckOpen m11 : 8|2@1+ (1,0) [0|3] ""  NF_Controller
 SG_ BATT_12_IsospiBreak m11 : 22|2@1+ (1,0) [0|3] ""  NF_Controller
 SG_ BATT_12_IsolationIntFault m11 : 20|2@1+ (1,0) [0|3] ""  NF_Controller
 SG_ BATT_12_IsolationExtFault m11 : 18|2@1+ (1,0) [0|3] ""  NF_Controller
 SG_ BATT_12_event_12v_filter_error m11 : 16|2@1+ (1,0) [0|3] ""  NF_Controller
 SG_ BATT_12_event_hall_eff_hi_rang_e m11 : 30|2@1+ (1,0) [0|3] ""  NF_Controller
 SG_ BATT_12_event_brick_volt_sns_ope m11 : 28|2@1+ (1,0) [0|3] ""  NF_Controller
 SG_ BATT_12_event_5v_error m11 : 26|2@1+ (1,0) [0|3] ""  NF_Controller
 SG_ BATT_12_event_3_3_hot_error m11 : 24|2@1+ (1,0) [0|3] ""  NF_Controller
 SG_ BATT_12_event_12v_input_error m11 : 38|2@1+ (1,0) [0|3] ""  NF_Controller
 SG_ BATT_12_event_1_25v_error m11 : 36|2@1+ (1,0) [0|3] ""  NF_Controller
 SG_ BATT_12_event_shunt_MIA m11 : 34|2@1+ (1,0) [0|3] ""  NF_Controller
 SG_ BATT_12_event_SBC_int_reg_error m11 : 32|2@1+ (1,0) [0|3] ""  NF_Controller
 SG_ BATT_12_event_pos_3_3v_analog_er m11 : 46|2@1+ (1,0) [0|3] ""  NF_Controller
 SG_ BATT_12_event_outlt_clnt_thrm_op m11 : 44|2@1+ (1,0) [0|3] ""  NF_Controller
 SG_ BATT_12_event_neg_3_3_analog_err m11 : 42|2@1+ (1,0) [0|3] ""  NF_Controller
 SG_ BATT_12_event_inlet_clnt_thrm_op m11 : 40|2@1+ (1,0) [0|3] ""  NF_Controller
 SG_ BATT_12_event_hall_eff_lo_rang_e m11 : 54|2@1+ (1,0) [0|3] ""  NF_Controller
 SG_ BATT_12_event_outlt_clnt_thrm_sh m11 : 52|2@1+ (1,0) [0|3] ""  NF_Controller
 SG_ BATT_12_event_inlet_clnt_thrm_sh m11 : 50|2@1+ (1,0) [0|3] ""  NF_Controller
 SG_ BATT_12_event_3_3v_error m11 : 48|2@1+ (1,0) [0|3] ""  NF_Controller
 SG_ BATT_13_PackVoltageImbalance m12 : 58|2@1+ (1,0) [0|3] "" NF_Controller
 SG_ BATT_13_PrechargeOvercurrent m12 : 56|2@1+ (1,0) [0|3] "" NF_Controller
 SG_ BATT_13_HVILvoltageError m12 : 2|2@1+ (1,0) [0|3] ""  NF_Controller
 SG_ BATT_13_HVILcurrentReturnError m12 : 0|2@1+ (1,0) [0|3] ""  NF_Controller
 SG_ BATT_13_PosFcContWelded m12 : 14|2@1+ (1,0) [0|3] ""  NF_Controller
 SG_ BATT_13_PosFcContStuckOpen m12 : 12|2@1+ (1,0) [0|3] ""  NF_Controller
 SG_ BATT_13_NegFcContWelded m12 : 10|2@1+ (1,0) [0|3] ""  NF_Controller
 SG_ BATT_13_NegFcContStuckOpen m12 : 8|2@1+ (1,0) [0|3] ""  NF_Controller
 SG_ BATT_13_IsospiBreak m12 : 22|2@1+ (1,0) [0|3] ""  NF_Controller
 SG_ BATT_13_IsolationIntFault m12 : 20|2@1+ (1,0) [0|3] ""  NF_Controller
 SG_ BATT_13_IsolationExtFault m12 : 18|2@1+ (1,0) [0|3] ""  NF_Controller
 SG_ BATT_13_event_12v_filter_error m12 : 16|2@1+ (1,0) [0|3] ""  NF_Controller
 SG_ BATT_13_event_hall_eff_hi_rang_e m12 : 30|2@1+ (1,0) [0|3] ""  NF_Controller
 SG_ BATT_13_event_brick_volt_sns_ope m12 : 28|2@1+ (1,0) [0|3] ""  NF_Controller
 SG_ BATT_13_event_5v_error m12 : 26|2@1+ (1,0) [0|3] ""  NF_Controller
 SG_ BATT_13_event_3_3_hot_error m12 : 24|2@1+ (1,0) [0|3] ""  NF_Controller
 SG_ BATT_13_event_12v_input_error m12 : 38|2@1+ (1,0) [0|3] ""  NF_Controller
 SG_ BATT_13_event_1_25v_error m12 : 36|2@1+ (1,0) [0|3] ""  NF_Controller
 SG_ BATT_13_event_shunt_MIA m12 : 34|2@1+ (1,0) [0|3] ""  NF_Controller
 SG_ BATT_13_event_SBC_int_reg_error m12 : 32|2@1+ (1,0) [0|3] ""  NF_Controller
 SG_ BATT_13_event_pos_3_3v_analog_er m12 : 46|2@1+ (1,0) [0|3] ""  NF_Controller
 SG_ BATT_13_event_outlt_clnt_thrm_op m12 : 44|2@1+ (1,0) [0|3] ""  NF_Controller
 SG_ BATT_13_event_neg_3_3_analog_err m12 : 42|2@1+ (1,0) [0|3] ""  NF_Controller
 SG_ BATT_13_event_inlet_clnt_thrm_op m12 : 40|2@1+ (1,0) [0|3] ""  NF_Controller
 SG_ BATT_13_event_hall_eff_lo_rang_e m12 : 54|2@1+ (1,0) [0|3] ""  NF_Controller
 SG_ BATT_13_event_outlt_clnt_thrm_sh m12 : 52|2@1+ (1,0) [0|3] ""  NF_Controller
 SG_ BATT_13_event_inlet_clnt_thrm_sh m12 : 50|2@1+ (1,0) [0|3] ""  NF_Controller
 SG_ BATT_13_event_3_3v_error m12 : 48|2@1+ (1,0) [0|3] ""  NF_Controller
 SG_ BATT_14_PackVoltageImbalance m13 : 58|2@1+ (1,0) [0|3] "" NF_Controller
 SG_ BATT_14_PrechargeOvercurrent m13 : 56|2@1+ (1,0) [0|3] "" NF_Controller
 SG_ BATT_14_HVILvoltageError m13 : 2|2@1+ (1,0) [0|3] ""  NF_Controller
 SG_ BATT_14_HVILcurrentReturnError m13 : 0|2@1+ (1,0) [0|3] ""  NF_Controller
 SG_ BATT_14_PosFcContWelded m13 : 14|2@1+ (1,0) [0|3] ""  NF_Controller
 SG_ BATT_14_PosFcContStuckOpen m13 : 12|2@1+ (1,0) [0|3] ""  NF_Controller
 SG_ BATT_14_NegFcContWelded m13 : 10|2@1+ (1,0) [0|3] ""  NF_Controller
 SG_ BATT_14_NegFcContStuckOpen m13 : 8|2@1+ (1,0) [0|3] ""  NF_Controller
 SG_ BATT_14_IsospiBreak m13 : 22|2@1+ (1,0) [0|3] ""  NF_Controller
 SG_ BATT_14_IsolationIntFault m13 : 20|2@1+ (1,0) [0|3] ""  NF_Controller
 SG_ BATT_14_IsolationExtFault m13 : 18|2@1+ (1,0) [0|3] ""  NF_Controller
 SG_ BATT_14_event_12v_filter_error m13 : 16|2@1+ (1,0) [0|3] ""  NF_Controller
 SG_ BATT_14_event_hall_eff_hi_rang_e m13 : 30|2@1+ (1,0) [0|3] ""  NF_Controller
 SG_ BATT_14_event_brick_volt_sns_ope m13 : 28|2@1+ (1,0) [0|3] ""  NF_Controller
 SG_ BATT_14_event_5v_error m13 : 26|2@1+ (1,0) [0|3] ""  NF_Controller
 SG_ BATT_14_event_3_3_hot_error m13 : 24|2@1+ (1,0) [0|3] ""  NF_Controller
 SG_ BATT_14_event_12v_input_error m13 : 38|2@1+ (1,0) [0|3] ""  NF_Controller
 SG_ BATT_14_event_1_25v_error m13 : 36|2@1+ (1,0) [0|3] ""  NF_Controller
 SG_ BATT_14_event_shunt_MIA m13 : 34|2@1+ (1,0) [0|3] ""  NF_Controller
 SG_ BATT_14_event_SBC_int_reg_error m13 : 32|2@1+ (1,0) [0|3] ""  NF_Controller
 SG_ BATT_14_event_pos_3_3v_analog_er m13 : 46|2@1+ (1,0) [0|3] ""  NF_Controller
 SG_ BATT_14_event_outlt_clnt_thrm_op m13 : 44|2@1+ (1,0) [0|3] ""  NF_Controller
 SG_ BATT_14_event_neg_3_3_analog_err m13 : 42|2@1+ (1,0) [0|3] ""  NF_Controller
 SG_ BATT_14_event_inlet_clnt_thrm_op m13 : 40|2@1+ (1,0) [0|3] ""  NF_Controller
 SG_ BATT_14_event_hall_eff_lo_rang_e m13 : 54|2@1+ (1,0) [0|3] ""  NF_Controller
 SG_ BATT_14_event_outlt_clnt_thrm_sh m13 : 52|2@1+ (1,0) [0|3] ""  NF_Controller
 SG_ BATT_14_event_inlet_clnt_thrm_sh m13 : 50|2@1+ (1,0) [0|3] ""  NF_Controller
 SG_ BATT_14_event_3_3v_error m13 : 48|2@1+ (1,0) [0|3] ""  NF_Controller
 SG_ BATT_15_PackVoltageImbalance m14 : 58|2@1+ (1,0) [0|3] "" NF_Controller
 SG_ BATT_15_PrechargeOvercurrent m14 : 56|2@1+ (1,0) [0|3] "" NF_Controller
 SG_ BATT_15_HVILvoltageError m14 : 2|2@1+ (1,0) [0|3] ""  NF_Controller
 SG_ BATT_15_HVILcurrentReturnError m14 : 0|2@1+ (1,0) [0|3] ""  NF_Controller
 SG_ BATT_15_PosFcContWelded m14 : 14|2@1+ (1,0) [0|3] ""  NF_Controller
 SG_ BATT_15_PosFcContStuckOpen m14 : 12|2@1+ (1,0) [0|3] ""  NF_Controller
 SG_ BATT_15_NegFcContWelded m14 : 10|2@1+ (1,0) [0|3] ""  NF_Controller
 SG_ BATT_15_NegFcContStuckOpen m14 : 8|2@1+ (1,0) [0|3] ""  NF_Controller
 SG_ BATT_15_IsospiBreak m14 : 22|2@1+ (1,0) [0|3] ""  NF_Controller
 SG_ BATT_15_IsolationIntFault m14 : 20|2@1+ (1,0) [0|3] ""  NF_Controller
 SG_ BATT_15_IsolationExtFault m14 : 18|2@1+ (1,0) [0|3] ""  NF_Controller
 SG_ BATT_15_event_12v_filter_error m14 : 16|2@1+ (1,0) [0|3] ""  NF_Controller
 SG_ BATT_15_event_hall_eff_hi_rang_e m14 : 30|2@1+ (1,0) [0|3] ""  NF_Controller
 SG_ BATT_15_event_brick_volt_sns_ope m14 : 28|2@1+ (1,0) [0|3] ""  NF_Controller
 SG_ BATT_15_event_5v_error m14 : 26|2@1+ (1,0) [0|3] ""  NF_Controller
 SG_ BATT_15_event_3_3_hot_error m14 : 24|2@1+ (1,0) [0|3] ""  NF_Controller
 SG_ BATT_15_event_12v_input_error m14 : 38|2@1+ (1,0) [0|3] ""  NF_Controller
 SG_ BATT_15_event_1_25v_error m14 : 36|2@1+ (1,0) [0|3] ""  NF_Controller
 SG_ BATT_15_event_shunt_MIA m14 : 34|2@1+ (1,0) [0|3] ""  NF_Controller
 SG_ BATT_15_event_SBC_int_reg_error m14 : 32|2@1+ (1,0) [0|3] ""  NF_Controller
 SG_ BATT_15_event_pos_3_3v_analog_er m14 : 46|2@1+ (1,0) [0|3] ""  NF_Controller
 SG_ BATT_15_event_outlt_clnt_thrm_op m14 : 44|2@1+ (1,0) [0|3] ""  NF_Controller
 SG_ BATT_15_event_neg_3_3_analog_err m14 : 42|2@1+ (1,0) [0|3] ""  NF_Controller
 SG_ BATT_15_event_inlet_clnt_thrm_op m14 : 40|2@1+ (1,0) [0|3] ""  NF_Controller
 SG_ BATT_15_event_hall_eff_lo_rang_e m14 : 54|2@1+ (1,0) [0|3] ""  NF_Controller
 SG_ BATT_15_event_outlt_clnt_thrm_sh m14 : 52|2@1+ (1,0) [0|3] ""  NF_Controller
 SG_ BATT_15_event_inlet_clnt_thrm_sh m14 : 50|2@1+ (1,0) [0|3] ""  NF_Controller
 SG_ BATT_15_event_3_3v_error m14 : 48|2@1+ (1,0) [0|3] ""  NF_Controller
 SG_ multiplexor_batt_diag_C M : 4|4@1+ (1,0) [0|15] ""  NF_Controller

CM_ "Application CAN Version: 1908_01";
BA_DEF_  "NetworkSpeed" ENUM  "250kBit/s","500kBit/s","1000kBit/s";
BA_DEF_ SG_  "SigType" ENUM  "Default","Range","RangeSigned","ASCII","Discrete","Control","ReferencePGN","DTC","StringDelimiter","StringLength","StringLengthControl","MessageCounter","MessageChecksum";
BA_DEF_ SG_  "GenSigEVName" STRING ;
BA_DEF_ SG_  "GenSigILSupport" ENUM  "No","Yes";
BA_DEF_ SG_  "GenSigSendType" ENUM  "Cyclic","OnWrite","OnWriteWithRepetition","OnChange","OnChangeWithRepetition","IfActive","IfActiveWithRepetition","NoSigSendType";
BA_DEF_ SG_  "GenSigStartValue" INT 0 10000;
BA_DEF_ BO_  "GenMsgILSupport" ENUM  "No","Yes";
BA_DEF_ BU_  "NmStationAddress" INT 0 255;
BA_DEF_ BO_  "GenMsgSendType" ENUM  "cyclic","NotUsed","IfActive","NotUsed","NotUsed","NotUsed","NotUsed","NotUsed","noMsgSendType";
BA_DEF_ BO_  "GenMsgRequestable" INT 0 1;
BA_DEF_ BO_  "GenMsgCycleTime" INT 0 3600000;
BA_DEF_ SG_  "SPN" INT 0 524287;
BA_DEF_  "DBName" STRING ;
BA_DEF_  "BusType" STRING ;
BA_DEF_  "ProtocolType" STRING ;
BA_DEF_ BO_  "VFrameFormat" ENUM  "StandardCAN","ExtendedCAN","reserved","J1939PG";
BA_DEF_ SG_  "SystemSignalLongSymbol" STRING ;
BA_DEF_DEF_  "NetworkSpeed" "250kBit/s";
BA_DEF_DEF_  "SigType" "Default";
BA_DEF_DEF_  "GenSigEVName" "Env@Nodename_@Signame";
BA_DEF_DEF_  "GenSigILSupport" "Yes";
BA_DEF_DEF_  "GenSigSendType" "NoSigSendType";
BA_DEF_DEF_  "GenSigStartValue" 0;
BA_DEF_DEF_  "GenMsgILSupport" "Yes";
BA_DEF_DEF_  "NmStationAddress" 254;
BA_DEF_DEF_  "GenMsgSendType" "noMsgSendType";
BA_DEF_DEF_  "GenMsgRequestable" 1;
BA_DEF_DEF_  "GenMsgCycleTime" 0;
BA_DEF_DEF_  "SPN" 0;
BA_DEF_DEF_  "DBName" "";
BA_DEF_DEF_  "BusType" "CAN";
BA_DEF_DEF_  "ProtocolType" "J1939";
BA_DEF_DEF_  "VFrameFormat" "J1939PG";
BA_DEF_DEF_  "SystemSignalLongSymbol" "";
BA_ "ProtocolType" "CAN";
BA_ "DBName" "NF_BMS_Application";
BA_ "NmStationAddress" BU_ BMS_Controller 100;
BA_ "NmStationAddress" BU_ NF_Controller 73;
BA_ "VFrameFormat" BO_ 2499758692 1;
BA_ "GenMsgCycleTime" BO_ 2499758692 100;
BA_ "VFrameFormat" BO_ 2499763812 1;
BA_ "GenMsgSendType" BO_ 2499763812 0;
BA_ "GenMsgCycleTime" BO_ 2499763556 100;
BA_ "GenMsgSendType" BO_ 2499763556 0;
BA_ "VFrameFormat" BO_ 2499763556 1;
BA_ "VFrameFormat" BO_ 2499763300 1;
BA_ "GenMsgSendType" BO_ 2499763300 0;
BA_ "VFrameFormat" BO_ 2499763044 1;
BA_ "GenMsgSendType" BO_ 2499763044 0;
BA_ "GenSigStartValue" SG_ 2499763044 BATT_01_HVILvoltageError 2;
BA_ "GenSigStartValue" SG_ 2499763044 BATT_01_HVILcurrentReturnError 2;
BA_ "GenSigStartValue" SG_ 2499763044 BATT_01_PosFcContWelded 2;
BA_ "GenSigStartValue" SG_ 2499763044 BATT_01_PosFcContStuckOpen 2;
BA_ "GenSigStartValue" SG_ 2499763044 BATT_01_NegFcContWelded 2;
BA_ "GenSigStartValue" SG_ 2499763044 BATT_01_NegFcContStuckOpen 2;
BA_ "GenSigStartValue" SG_ 2499763044 BATT_01_IsospiBreak 2;
BA_ "GenSigStartValue" SG_ 2499763044 BATT_01_IsolationIntFault 2;
BA_ "GenSigStartValue" SG_ 2499763044 BATT_01_IsolationExtFault 2;
BA_ "GenSigStartValue" SG_ 2499763044 BATT_01_event_12v_filter_error 2;
BA_ "GenSigStartValue" SG_ 2499763044 BATT_01_event_hall_eff_hi_rang_e 2;
BA_ "SystemSignalLongSymbol" SG_ 2499763044 BATT_01_event_hall_eff_hi_rang_e "BATT_01_event_hall_eff_hi_rang_err";
BA_ "GenSigStartValue" SG_ 2499763044 BATT_01_event_brick_volt_sns_ope 2;
BA_ "SystemSignalLongSymbol" SG_ 2499763044 BATT_01_event_brick_volt_sns_ope "BATT_01_event_brick_volt_sns_open";
BA_ "GenSigStartValue" SG_ 2499763044 BATT_01_event_5v_error 2;
BA_ "GenSigStartValue" SG_ 2499763044 BATT_01_event_3_3_hot_error 2;
BA_ "GenSigStartValue" SG_ 2499763044 BATT_01_event_12v_input_error 2;
BA_ "GenSigStartValue" SG_ 2499763044 BATT_01_event_1_25v_error 2;
BA_ "GenSigStartValue" SG_ 2499763044 BATT_01_event_shunt_MIA 2;
BA_ "GenSigStartValue" SG_ 2499763044 BATT_01_event_SBC_int_reg_error 2;
BA_ "GenSigStartValue" SG_ 2499763044 BATT_01_event_pos_3_3v_analog_er 2;
BA_ "SystemSignalLongSymbol" SG_ 2499763044 BATT_01_event_pos_3_3v_analog_er "BATT_01_event_pos_3_3v_analog_error";
BA_ "GenSigStartValue" SG_ 2499763044 BATT_01_event_outlt_clnt_thrm_op 2;
BA_ "SystemSignalLongSymbol" SG_ 2499763044 BATT_01_event_outlt_clnt_thrm_op "BATT_01_event_outlt_clnt_thrm_open";
BA_ "GenSigStartValue" SG_ 2499763044 BATT_01_event_neg_3_3_analog_err 2;
BA_ "SystemSignalLongSymbol" SG_ 2499763044 BATT_01_event_neg_3_3_analog_err "BATT_01_event_neg_3_3_analog_error";
BA_ "GenSigStartValue" SG_ 2499763044 BATT_01_event_inlet_clnt_thrm_op 2;
BA_ "SystemSignalLongSymbol" SG_ 2499763044 BATT_01_event_inlet_clnt_thrm_op "BATT_01_event_inlet_clnt_thrm_open";
BA_ "GenSigStartValue" SG_ 2499763044 BATT_01_event_hall_eff_lo_rang_e 2;
BA_ "SystemSignalLongSymbol" SG_ 2499763044 BATT_01_event_hall_eff_lo_rang_e "BATT_01_event_hall_eff_lo_rang_err";
BA_ "GenSigStartValue" SG_ 2499763044 BATT_01_event_outlt_clnt_thrm_sh 2;
BA_ "SystemSignalLongSymbol" SG_ 2499763044 BATT_01_event_outlt_clnt_thrm_sh "BATT_01_event_outlt_clnt_thrm_short";
BA_ "GenSigStartValue" SG_ 2499763044 BATT_01_event_inlet_clnt_thrm_sh 2;
BA_ "SystemSignalLongSymbol" SG_ 2499763044 BATT_01_event_inlet_clnt_thrm_sh "BATT_01_event_inlet_clnt_thrm_short";
BA_ "GenSigStartValue" SG_ 2499763044 BATT_01_event_3_3v_error 2;
BA_ "GenSigStartValue" SG_ 2499763044 BATT_02_HVILvoltageError 2;
BA_ "GenSigStartValue" SG_ 2499763044 BATT_02_HVILcurrentReturnError 2;
BA_ "GenSigStartValue" SG_ 2499763044 BATT_02_PosFcContWelded 2;
BA_ "GenSigStartValue" SG_ 2499763044 BATT_02_PosFcContStuckOpen 2;
BA_ "GenSigStartValue" SG_ 2499763044 BATT_02_NegFcContWelded 2;
BA_ "GenSigStartValue" SG_ 2499763044 BATT_02_NegFcContStuckOpen 2;
BA_ "GenSigStartValue" SG_ 2499763044 BATT_02_IsospiBreak 2;
BA_ "GenSigStartValue" SG_ 2499763044 BATT_02_IsolationIntFault 2;
BA_ "GenSigStartValue" SG_ 2499763044 BATT_02_IsolationExtFault 2;
BA_ "GenSigStartValue" SG_ 2499763044 BATT_02_event_12v_filter_error 2;
BA_ "GenSigStartValue" SG_ 2499763044 BATT_02_event_hall_eff_hi_rang_e 2;
BA_ "SystemSignalLongSymbol" SG_ 2499763044 BATT_02_event_hall_eff_hi_rang_e "BATT_02_event_hall_eff_hi_rang_err";
BA_ "GenSigStartValue" SG_ 2499763044 BATT_02_event_brick_volt_sns_ope 2;
BA_ "SystemSignalLongSymbol" SG_ 2499763044 BATT_02_event_brick_volt_sns_ope "BATT_02_event_brick_volt_sns_open";
BA_ "GenSigStartValue" SG_ 2499763044 BATT_02_event_5v_error 2;
BA_ "GenSigStartValue" SG_ 2499763044 BATT_02_event_3_3_hot_error 2;
BA_ "GenSigStartValue" SG_ 2499763044 BATT_02_event_12v_input_error 2;
BA_ "GenSigStartValue" SG_ 2499763044 BATT_02_event_1_25v_error 2;
BA_ "GenSigStartValue" SG_ 2499763044 BATT_02_event_shunt_MIA 2;
BA_ "GenSigStartValue" SG_ 2499763044 BATT_02_event_SBC_int_reg_error 2;
BA_ "GenSigStartValue" SG_ 2499763044 BATT_02_event_pos_3_3v_analog_er 2;
BA_ "SystemSignalLongSymbol" SG_ 2499763044 BATT_02_event_pos_3_3v_analog_er "BATT_02_event_pos_3_3v_analog_error";
BA_ "GenSigStartValue" SG_ 2499763044 BATT_02_event_outlt_clnt_thrm_op 2;
BA_ "SystemSignalLongSymbol" SG_ 2499763044 BATT_02_event_outlt_clnt_thrm_op "BATT_02_event_outlt_clnt_thrm_open";
BA_ "GenSigStartValue" SG_ 2499763044 BATT_02_event_neg_3_3_analog_err 2;
BA_ "SystemSignalLongSymbol" SG_ 2499763044 BATT_02_event_neg_3_3_analog_err "BATT_02_event_neg_3_3_analog_error";
BA_ "GenSigStartValue" SG_ 2499763044 BATT_02_event_inlet_clnt_thrm_op 2;
BA_ "SystemSignalLongSymbol" SG_ 2499763044 BATT_02_event_inlet_clnt_thrm_op "BATT_02_event_inlet_clnt_thrm_open";
BA_ "GenSigStartValue" SG_ 2499763044 BATT_02_event_hall_eff_lo_rang_e 2;
BA_ "SystemSignalLongSymbol" SG_ 2499763044 BATT_02_event_hall_eff_lo_rang_e "BATT_02_event_hall_eff_lo_rang_err";
BA_ "GenSigStartValue" SG_ 2499763044 BATT_02_event_outlt_clnt_thrm_sh 2;
BA_ "SystemSignalLongSymbol" SG_ 2499763044 BATT_02_event_outlt_clnt_thrm_sh "BATT_02_event_outlt_clnt_thrm_short";
BA_ "GenSigStartValue" SG_ 2499763044 BATT_02_event_inlet_clnt_thrm_sh 2;
BA_ "SystemSignalLongSymbol" SG_ 2499763044 BATT_02_event_inlet_clnt_thrm_sh "BATT_02_event_inlet_clnt_thrm_short";
BA_ "GenSigStartValue" SG_ 2499763044 BATT_02_event_3_3v_error 2;
BA_ "GenSigStartValue" SG_ 2499763044 BATT_03_HVILvoltageError 2;
BA_ "GenSigStartValue" SG_ 2499763044 BATT_03_HVILcurrentReturnError 2;
BA_ "GenSigStartValue" SG_ 2499763044 BATT_03_PosFcContWelded 2;
BA_ "GenSigStartValue" SG_ 2499763044 BATT_03_PosFcContStuckOpen 2;
BA_ "GenSigStartValue" SG_ 2499763044 BATT_03_NegFcContWelded 2;
BA_ "GenSigStartValue" SG_ 2499763044 BATT_03_NegFcContStuckOpen 2;
BA_ "GenSigStartValue" SG_ 2499763044 BATT_03_IsospiBreak 2;
BA_ "GenSigStartValue" SG_ 2499763044 BATT_03_IsolationIntFault 2;
BA_ "GenSigStartValue" SG_ 2499763044 BATT_03_IsolationExtFault 2;
BA_ "GenSigStartValue" SG_ 2499763044 BATT_03_event_12v_filter_error 2;
BA_ "GenSigStartValue" SG_ 2499763044 BATT_03_event_hall_eff_hi_rang_e 2;
BA_ "SystemSignalLongSymbol" SG_ 2499763044 BATT_03_event_hall_eff_hi_rang_e "BATT_03_event_hall_eff_hi_rang_err";
BA_ "GenSigStartValue" SG_ 2499763044 BATT_03_event_brick_volt_sns_ope 2;
BA_ "SystemSignalLongSymbol" SG_ 2499763044 BATT_03_event_brick_volt_sns_ope "BATT_03_event_brick_volt_sns_open";
BA_ "GenSigStartValue" SG_ 2499763044 BATT_03_event_5v_error 2;
BA_ "GenSigStartValue" SG_ 2499763044 BATT_03_event_3_3_hot_error 2;
BA_ "GenSigStartValue" SG_ 2499763044 BATT_03_event_12v_input_error 2;
BA_ "GenSigStartValue" SG_ 2499763044 BATT_03_event_1_25v_error 2;
BA_ "GenSigStartValue" SG_ 2499763044 BATT_03_event_shunt_MIA 2;
BA_ "GenSigStartValue" SG_ 2499763044 BATT_03_event_SBC_int_reg_error 2;
BA_ "GenSigStartValue" SG_ 2499763044 BATT_03_event_pos_3_3v_analog_er 2;
BA_ "SystemSignalLongSymbol" SG_ 2499763044 BATT_03_event_pos_3_3v_analog_er "BATT_03_event_pos_3_3v_analog_error";
BA_ "GenSigStartValue" SG_ 2499763044 BATT_03_event_outlt_clnt_thrm_op 2;
BA_ "SystemSignalLongSymbol" SG_ 2499763044 BATT_03_event_outlt_clnt_thrm_op "BATT_03_event_outlt_clnt_thrm_open";
BA_ "GenSigStartValue" SG_ 2499763044 BATT_03_event_neg_3_3_analog_err 2;
BA_ "SystemSignalLongSymbol" SG_ 2499763044 BATT_03_event_neg_3_3_analog_err "BATT_03_event_neg_3_3_analog_error";
BA_ "GenSigStartValue" SG_ 2499763044 BATT_03_event_inlet_clnt_thrm_op 2;
BA_ "SystemSignalLongSymbol" SG_ 2499763044 BATT_03_event_inlet_clnt_thrm_op "BATT_03_event_inlet_clnt_thrm_open";
BA_ "GenSigStartValue" SG_ 2499763044 BATT_03_event_hall_eff_lo_rang_e 2;
BA_ "SystemSignalLongSymbol" SG_ 2499763044 BATT_03_event_hall_eff_lo_rang_e "BATT_03_event_hall_eff_lo_rang_err";
BA_ "GenSigStartValue" SG_ 2499763044 BATT_03_event_outlt_clnt_thrm_sh 2;
BA_ "SystemSignalLongSymbol" SG_ 2499763044 BATT_03_event_outlt_clnt_thrm_sh "BATT_03_event_outlt_clnt_thrm_short";
BA_ "GenSigStartValue" SG_ 2499763044 BATT_03_event_inlet_clnt_thrm_sh 2;
BA_ "SystemSignalLongSymbol" SG_ 2499763044 BATT_03_event_inlet_clnt_thrm_sh "BATT_03_event_inlet_clnt_thrm_short";
BA_ "GenSigStartValue" SG_ 2499763044 BATT_03_event_3_3v_error 2;
BA_ "GenSigStartValue" SG_ 2499763044 BATT_04_HVILvoltageError 2;
BA_ "GenSigStartValue" SG_ 2499763044 BATT_04_HVILcurrentReturnError 2;
BA_ "GenSigStartValue" SG_ 2499763044 BATT_04_PosFcContWelded 2;
BA_ "GenSigStartValue" SG_ 2499763044 BATT_04_PosFcContStuckOpen 2;
BA_ "GenSigStartValue" SG_ 2499763044 BATT_04_NegFcContWelded 2;
BA_ "GenSigStartValue" SG_ 2499763044 BATT_04_NegFcContStuckOpen 2;
BA_ "GenSigStartValue" SG_ 2499763044 BATT_04_IsospiBreak 2;
BA_ "GenSigStartValue" SG_ 2499763044 BATT_04_IsolationIntFault 2;
BA_ "GenSigStartValue" SG_ 2499763044 BATT_04_IsolationExtFault 2;
BA_ "GenSigStartValue" SG_ 2499763044 BATT_04_event_12v_filter_error 2;
BA_ "GenSigStartValue" SG_ 2499763044 BATT_04_event_hall_eff_hi_rang_e 2;
BA_ "SystemSignalLongSymbol" SG_ 2499763044 BATT_04_event_hall_eff_hi_rang_e "BATT_04_event_hall_eff_hi_rang_err";
BA_ "GenSigStartValue" SG_ 2499763044 BATT_04_event_brick_volt_sns_ope 2;
BA_ "SystemSignalLongSymbol" SG_ 2499763044 BATT_04_event_brick_volt_sns_ope "BATT_04_event_brick_volt_sns_open";
BA_ "GenSigStartValue" SG_ 2499763044 BATT_04_event_5v_error 2;
BA_ "GenSigStartValue" SG_ 2499763044 BATT_04_event_3_3_hot_error 2;
BA_ "GenSigStartValue" SG_ 2499763044 BATT_04_event_12v_input_error 2;
BA_ "GenSigStartValue" SG_ 2499763044 BATT_04_event_1_25v_error 2;
BA_ "GenSigStartValue" SG_ 2499763044 BATT_04_event_shunt_MIA 2;
BA_ "GenSigStartValue" SG_ 2499763044 BATT_04_event_SBC_int_reg_error 2;
BA_ "GenSigStartValue" SG_ 2499763044 BATT_04_event_pos_3_3v_analog_er 2;
BA_ "SystemSignalLongSymbol" SG_ 2499763044 BATT_04_event_pos_3_3v_analog_er "BATT_04_event_pos_3_3v_analog_error";
BA_ "GenSigStartValue" SG_ 2499763044 BATT_04_event_outlt_clnt_thrm_op 2;
BA_ "SystemSignalLongSymbol" SG_ 2499763044 BATT_04_event_outlt_clnt_thrm_op "BATT_04_event_outlt_clnt_thrm_open";
BA_ "GenSigStartValue" SG_ 2499763044 BATT_04_event_neg_3_3_analog_err 2;
BA_ "SystemSignalLongSymbol" SG_ 2499763044 BATT_04_event_neg_3_3_analog_err "BATT_04_event_neg_3_3_analog_error";
BA_ "GenSigStartValue" SG_ 2499763044 BATT_04_event_inlet_clnt_thrm_op 2;
BA_ "SystemSignalLongSymbol" SG_ 2499763044 BATT_04_event_inlet_clnt_thrm_op "BATT_04_event_inlet_clnt_thrm_open";
BA_ "GenSigStartValue" SG_ 2499763044 BATT_04_event_hall_eff_lo_rang_e 2;
BA_ "SystemSignalLongSymbol" SG_ 2499763044 BATT_04_event_hall_eff_lo_rang_e "BATT_04_event_hall_eff_lo_rang_err";
BA_ "GenSigStartValue" SG_ 2499763044 BATT_04_event_outlt_clnt_thrm_sh 2;
BA_ "SystemSignalLongSymbol" SG_ 2499763044 BATT_04_event_outlt_clnt_thrm_sh "BATT_04_event_outlt_clnt_thrm_short";
BA_ "GenSigStartValue" SG_ 2499763044 BATT_04_event_inlet_clnt_thrm_sh 2;
BA_ "SystemSignalLongSymbol" SG_ 2499763044 BATT_04_event_inlet_clnt_thrm_sh "BATT_04_event_inlet_clnt_thrm_short";
BA_ "GenSigStartValue" SG_ 2499763044 BATT_04_event_3_3v_error 2;
BA_ "GenSigStartValue" SG_ 2499763044 BATT_05_HVILvoltageError 2;
BA_ "GenSigStartValue" SG_ 2499763044 BATT_05_HVILcurrentReturnError 2;
BA_ "GenSigStartValue" SG_ 2499763044 BATT_05_PosFcContWelded 2;
BA_ "GenSigStartValue" SG_ 2499763044 BATT_05_PosFcContStuckOpen 2;
BA_ "GenSigStartValue" SG_ 2499763044 BATT_05_NegFcContWelded 2;
BA_ "GenSigStartValue" SG_ 2499763044 BATT_05_NegFcContStuckOpen 2;
BA_ "GenSigStartValue" SG_ 2499763044 BATT_05_IsospiBreak 2;
BA_ "GenSigStartValue" SG_ 2499763044 BATT_05_IsolationIntFault 2;
BA_ "GenSigStartValue" SG_ 2499763044 BATT_05_IsolationExtFault 2;
BA_ "GenSigStartValue" SG_ 2499763044 BATT_05_event_12v_filter_error 2;
BA_ "GenSigStartValue" SG_ 2499763044 BATT_05_event_hall_eff_hi_rang_e 2;
BA_ "SystemSignalLongSymbol" SG_ 2499763044 BATT_05_event_hall_eff_hi_rang_e "BATT_05_event_hall_eff_hi_rang_err";
BA_ "GenSigStartValue" SG_ 2499763044 BATT_05_event_brick_volt_sns_ope 2;
BA_ "SystemSignalLongSymbol" SG_ 2499763044 BATT_05_event_brick_volt_sns_ope "BATT_05_event_brick_volt_sns_open";
BA_ "GenSigStartValue" SG_ 2499763044 BATT_05_event_5v_error 2;
BA_ "GenSigStartValue" SG_ 2499763044 BATT_05_event_3_3_hot_error 2;
BA_ "GenSigStartValue" SG_ 2499763044 BATT_05_event_12v_input_error 2;
BA_ "GenSigStartValue" SG_ 2499763044 BATT_05_event_1_25v_error 2;
BA_ "GenSigStartValue" SG_ 2499763044 BATT_05_event_shunt_MIA 2;
BA_ "GenSigStartValue" SG_ 2499763044 BATT_05_event_SBC_int_reg_error 2;
BA_ "GenSigStartValue" SG_ 2499763044 BATT_05_event_pos_3_3v_analog_er 2;
BA_ "SystemSignalLongSymbol" SG_ 2499763044 BATT_05_event_pos_3_3v_analog_er "BATT_05_event_pos_3_3v_analog_error";
BA_ "GenSigStartValue" SG_ 2499763044 BATT_05_event_outlt_clnt_thrm_op 2;
BA_ "SystemSignalLongSymbol" SG_ 2499763044 BATT_05_event_outlt_clnt_thrm_op "BATT_05_event_outlt_clnt_thrm_open";
BA_ "GenSigStartValue" SG_ 2499763044 BATT_05_event_neg_3_3_analog_err 2;
BA_ "SystemSignalLongSymbol" SG_ 2499763044 BATT_05_event_neg_3_3_analog_err "BATT_05_event_neg_3_3_analog_error";
BA_ "GenSigStartValue" SG_ 2499763044 BATT_05_event_inlet_clnt_thrm_op 2;
BA_ "SystemSignalLongSymbol" SG_ 2499763044 BATT_05_event_inlet_clnt_thrm_op "BATT_05_event_inlet_clnt_thrm_open";
BA_ "GenSigStartValue" SG_ 2499763044 BATT_05_event_hall_eff_lo_rang_e 2;
BA_ "SystemSignalLongSymbol" SG_ 2499763044 BATT_05_event_hall_eff_lo_rang_e "BATT_05_event_hall_eff_lo_rang_err";
BA_ "GenSigStartValue" SG_ 2499763044 BATT_05_event_outlt_clnt_thrm_sh 2;
BA_ "SystemSignalLongSymbol" SG_ 2499763044 BATT_05_event_outlt_clnt_thrm_sh "BATT_05_event_outlt_clnt_thrm_short";
BA_ "GenSigStartValue" SG_ 2499763044 BATT_05_event_inlet_clnt_thrm_sh 2;
BA_ "SystemSignalLongSymbol" SG_ 2499763044 BATT_05_event_inlet_clnt_thrm_sh "BATT_05_event_inlet_clnt_thrm_short";
BA_ "GenSigStartValue" SG_ 2499763044 BATT_05_event_3_3v_error 2;
BA_ "GenSigStartValue" SG_ 2499763044 BATT_06_HVILvoltageError 2;
BA_ "GenSigStartValue" SG_ 2499763044 BATT_06_HVILcurrentReturnError 2;
BA_ "GenSigStartValue" SG_ 2499763044 BATT_06_PosFcContWelded 2;
BA_ "GenSigStartValue" SG_ 2499763044 BATT_06_PosFcContStuckOpen 2;
BA_ "GenSigStartValue" SG_ 2499763044 BATT_06_NegFcContWelded 2;
BA_ "GenSigStartValue" SG_ 2499763044 BATT_06_NegFcContStuckOpen 2;
BA_ "GenSigStartValue" SG_ 2499763044 BATT_06_IsospiBreak 2;
BA_ "GenSigStartValue" SG_ 2499763044 BATT_06_IsolationIntFault 2;
BA_ "GenSigStartValue" SG_ 2499763044 BATT_06_IsolationExtFault 2;
BA_ "GenSigStartValue" SG_ 2499763044 BATT_06_event_12v_filter_error 2;
BA_ "GenSigStartValue" SG_ 2499763044 BATT_06_event_hall_eff_hi_rang_e 2;
BA_ "SystemSignalLongSymbol" SG_ 2499763044 BATT_06_event_hall_eff_hi_rang_e "BATT_06_event_hall_eff_hi_rang_err";
BA_ "GenSigStartValue" SG_ 2499763044 BATT_06_event_brick_volt_sns_ope 2;
BA_ "SystemSignalLongSymbol" SG_ 2499763044 BATT_06_event_brick_volt_sns_ope "BATT_06_event_brick_volt_sns_open";
BA_ "GenSigStartValue" SG_ 2499763044 BATT_06_event_5v_error 2;
BA_ "GenSigStartValue" SG_ 2499763044 BATT_06_event_3_3_hot_error 2;
BA_ "GenSigStartValue" SG_ 2499763044 BATT_06_event_12v_input_error 2;
BA_ "GenSigStartValue" SG_ 2499763044 BATT_06_event_1_25v_error 2;
BA_ "GenSigStartValue" SG_ 2499763044 BATT_06_event_shunt_MIA 2;
BA_ "GenSigStartValue" SG_ 2499763044 BATT_06_event_SBC_int_reg_error 2;
BA_ "GenSigStartValue" SG_ 2499763044 BATT_06_event_pos_3_3v_analog_er 2;
BA_ "SystemSignalLongSymbol" SG_ 2499763044 BATT_06_event_pos_3_3v_analog_er "BATT_06_event_pos_3_3v_analog_error";
BA_ "GenSigStartValue" SG_ 2499763044 BATT_06_event_outlt_clnt_thrm_op 2;
BA_ "SystemSignalLongSymbol" SG_ 2499763044 BATT_06_event_outlt_clnt_thrm_op "BATT_06_event_outlt_clnt_thrm_open";
BA_ "GenSigStartValue" SG_ 2499763044 BATT_06_event_neg_3_3_analog_err 2;
BA_ "SystemSignalLongSymbol" SG_ 2499763044 BATT_06_event_neg_3_3_analog_err "BATT_06_event_neg_3_3_analog_error";
BA_ "GenSigStartValue" SG_ 2499763044 BATT_06_event_inlet_clnt_thrm_op 2;
BA_ "SystemSignalLongSymbol" SG_ 2499763044 BATT_06_event_inlet_clnt_thrm_op "BATT_06_event_inlet_clnt_thrm_open";
BA_ "GenSigStartValue" SG_ 2499763044 BATT_06_event_hall_eff_lo_rang_e 2;
BA_ "SystemSignalLongSymbol" SG_ 2499763044 BATT_06_event_hall_eff_lo_rang_e "BATT_06_event_hall_eff_lo_rang_err";
BA_ "GenSigStartValue" SG_ 2499763044 BATT_06_event_outlt_clnt_thrm_sh 2;
BA_ "SystemSignalLongSymbol" SG_ 2499763044 BATT_06_event_outlt_clnt_thrm_sh "BATT_06_event_outlt_clnt_thrm_short";
BA_ "GenSigStartValue" SG_ 2499763044 BATT_06_event_inlet_clnt_thrm_sh 2;
BA_ "SystemSignalLongSymbol" SG_ 2499763044 BATT_06_event_inlet_clnt_thrm_sh "BATT_06_event_inlet_clnt_thrm_short";
BA_ "GenSigStartValue" SG_ 2499763044 BATT_06_event_3_3v_error 2;
BA_ "GenSigStartValue" SG_ 2499763044 BATT_07_HVILvoltageError 2;
BA_ "GenSigStartValue" SG_ 2499763044 BATT_07_HVILcurrentReturnError 2;
BA_ "GenSigStartValue" SG_ 2499763044 BATT_07_PosFcContWelded 2;
BA_ "GenSigStartValue" SG_ 2499763044 BATT_07_PosFcContStuckOpen 2;
BA_ "GenSigStartValue" SG_ 2499763044 BATT_07_NegFcContWelded 2;
BA_ "GenSigStartValue" SG_ 2499763044 BATT_07_NegFcContStuckOpen 2;
BA_ "GenSigStartValue" SG_ 2499763044 BATT_07_IsospiBreak 2;
BA_ "GenSigStartValue" SG_ 2499763044 BATT_07_IsolationIntFault 2;
BA_ "GenSigStartValue" SG_ 2499763044 BATT_07_IsolationExtFault 2;
BA_ "GenSigStartValue" SG_ 2499763044 BATT_07_event_12v_filter_error 2;
BA_ "GenSigStartValue" SG_ 2499763044 BATT_07_event_hall_eff_hi_rang_e 2;
BA_ "SystemSignalLongSymbol" SG_ 2499763044 BATT_07_event_hall_eff_hi_rang_e "BATT_07_event_hall_eff_hi_rang_err";
BA_ "GenSigStartValue" SG_ 2499763044 BATT_07_event_brick_volt_sns_ope 2;
BA_ "SystemSignalLongSymbol" SG_ 2499763044 BATT_07_event_brick_volt_sns_ope "BATT_07_event_brick_volt_sns_open";
BA_ "GenSigStartValue" SG_ 2499763044 BATT_07_event_5v_error 2;
BA_ "GenSigStartValue" SG_ 2499763044 BATT_07_event_3_3_hot_error 2;
BA_ "GenSigStartValue" SG_ 2499763044 BATT_07_event_12v_input_error 2;
BA_ "GenSigStartValue" SG_ 2499763044 BATT_07_event_1_25v_error 2;
BA_ "GenSigStartValue" SG_ 2499763044 BATT_07_event_shunt_MIA 2;
BA_ "GenSigStartValue" SG_ 2499763044 BATT_07_event_SBC_int_reg_error 2;
BA_ "GenSigStartValue" SG_ 2499763044 BATT_07_event_pos_3_3v_analog_er 2;
BA_ "SystemSignalLongSymbol" SG_ 2499763044 BATT_07_event_pos_3_3v_analog_er "BATT_07_event_pos_3_3v_analog_error";
BA_ "GenSigStartValue" SG_ 2499763044 BATT_07_event_outlt_clnt_thrm_op 2;
BA_ "SystemSignalLongSymbol" SG_ 2499763044 BATT_07_event_outlt_clnt_thrm_op "BATT_07_event_outlt_clnt_thrm_open";
BA_ "GenSigStartValue" SG_ 2499763044 BATT_07_event_neg_3_3_analog_err 2;
BA_ "SystemSignalLongSymbol" SG_ 2499763044 BATT_07_event_neg_3_3_analog_err "BATT_07_event_neg_3_3_analog_error";
BA_ "GenSigStartValue" SG_ 2499763044 BATT_07_event_inlet_clnt_thrm_op 2;
BA_ "SystemSignalLongSymbol" SG_ 2499763044 BATT_07_event_inlet_clnt_thrm_op "BATT_07_event_inlet_clnt_thrm_open";
BA_ "GenSigStartValue" SG_ 2499763044 BATT_07_event_hall_eff_lo_rang_e 2;
BA_ "SystemSignalLongSymbol" SG_ 2499763044 BATT_07_event_hall_eff_lo_rang_e "BATT_07_event_hall_eff_lo_rang_err";
BA_ "GenSigStartValue" SG_ 2499763044 BATT_07_event_outlt_clnt_thrm_sh 2;
BA_ "SystemSignalLongSymbol" SG_ 2499763044 BATT_07_event_outlt_clnt_thrm_sh "BATT_07_event_outlt_clnt_thrm_short";
BA_ "GenSigStartValue" SG_ 2499763044 BATT_07_event_inlet_clnt_thrm_sh 2;
BA_ "SystemSignalLongSymbol" SG_ 2499763044 BATT_07_event_inlet_clnt_thrm_sh "BATT_07_event_inlet_clnt_thrm_short";
BA_ "GenSigStartValue" SG_ 2499763044 BATT_07_event_3_3v_error 2;
BA_ "GenSigStartValue" SG_ 2499763044 BATT_08_HVILvoltageError 2;
BA_ "GenSigStartValue" SG_ 2499763044 BATT_08_HVILcurrentReturnError 2;
BA_ "GenSigStartValue" SG_ 2499763044 BATT_08_PosFcContWelded 2;
BA_ "GenSigStartValue" SG_ 2499763044 BATT_08_PosFcContStuckOpen 2;
BA_ "GenSigStartValue" SG_ 2499763044 BATT_08_NegFcContWelded 2;
BA_ "GenSigStartValue" SG_ 2499763044 BATT_08_NegFcContStuckOpen 2;
BA_ "GenSigStartValue" SG_ 2499763044 BATT_08_IsospiBreak 2;
BA_ "GenSigStartValue" SG_ 2499763044 BATT_08_IsolationIntFault 2;
BA_ "GenSigStartValue" SG_ 2499763044 BATT_08_IsolationExtFault 2;
BA_ "GenSigStartValue" SG_ 2499763044 BATT_08_event_12v_filter_error 2;
BA_ "GenSigStartValue" SG_ 2499763044 BATT_08_event_hall_eff_hi_rang_e 2;
BA_ "SystemSignalLongSymbol" SG_ 2499763044 BATT_08_event_hall_eff_hi_rang_e "BATT_08_event_hall_eff_hi_rang_err";
BA_ "GenSigStartValue" SG_ 2499763044 BATT_08_event_brick_volt_sns_ope 2;
BA_ "SystemSignalLongSymbol" SG_ 2499763044 BATT_08_event_brick_volt_sns_ope "BATT_08_event_brick_volt_sns_open";
BA_ "GenSigStartValue" SG_ 2499763044 BATT_08_event_5v_error 2;
BA_ "GenSigStartValue" SG_ 2499763044 BATT_08_event_3_3_hot_error 2;
BA_ "GenSigStartValue" SG_ 2499763044 BATT_08_event_12v_input_error 2;
BA_ "GenSigStartValue" SG_ 2499763044 BATT_08_event_1_25v_error 2;
BA_ "GenSigStartValue" SG_ 2499763044 BATT_08_event_shunt_MIA 2;
BA_ "GenSigStartValue" SG_ 2499763044 BATT_08_event_SBC_int_reg_error 2;
BA_ "GenSigStartValue" SG_ 2499763044 BATT_08_event_pos_3_3v_analog_er 2;
BA_ "SystemSignalLongSymbol" SG_ 2499763044 BATT_08_event_pos_3_3v_analog_er "BATT_08_event_pos_3_3v_analog_error";
BA_ "GenSigStartValue" SG_ 2499763044 BATT_08_event_outlt_clnt_thrm_op 2;
BA_ "SystemSignalLongSymbol" SG_ 2499763044 BATT_08_event_outlt_clnt_thrm_op "BATT_08_event_outlt_clnt_thrm_open";
BA_ "GenSigStartValue" SG_ 2499763044 BATT_08_event_neg_3_3_analog_err 2;
BA_ "SystemSignalLongSymbol" SG_ 2499763044 BATT_08_event_neg_3_3_analog_err "BATT_08_event_neg_3_3_analog_error";
BA_ "GenSigStartValue" SG_ 2499763044 BATT_08_event_inlet_clnt_thrm_op 2;
BA_ "SystemSignalLongSymbol" SG_ 2499763044 BATT_08_event_inlet_clnt_thrm_op "BATT_08_event_inlet_clnt_thrm_open";
BA_ "GenSigStartValue" SG_ 2499763044 BATT_08_event_hall_eff_lo_rang_e 2;
BA_ "SystemSignalLongSymbol" SG_ 2499763044 BATT_08_event_hall_eff_lo_rang_e "BATT_08_event_hall_eff_lo_rang_err";
BA_ "GenSigStartValue" SG_ 2499763044 BATT_08_event_outlt_clnt_thrm_sh 2;
BA_ "SystemSignalLongSymbol" SG_ 2499763044 BATT_08_event_outlt_clnt_thrm_sh "BATT_08_event_outlt_clnt_thrm_short";
BA_ "GenSigStartValue" SG_ 2499763044 BATT_08_event_inlet_clnt_thrm_sh 2;
BA_ "SystemSignalLongSymbol" SG_ 2499763044 BATT_08_event_inlet_clnt_thrm_sh "BATT_08_event_inlet_clnt_thrm_short";
BA_ "GenSigStartValue" SG_ 2499763044 BATT_08_event_3_3v_error 2;
BA_ "GenSigStartValue" SG_ 2499763044 BATT_09_HVILvoltageError 2;
BA_ "GenSigStartValue" SG_ 2499763044 BATT_09_HVILcurrentReturnError 2;
BA_ "GenSigStartValue" SG_ 2499763044 BATT_09_PosFcContWelded 2;
BA_ "GenSigStartValue" SG_ 2499763044 BATT_09_NegFcContWelded 2;
BA_ "GenSigStartValue" SG_ 2499763044 BATT_09_NegFcContStuckOpen 2;
BA_ "GenSigStartValue" SG_ 2499763044 BATT_09_PosFcContStuckOpen 2;
BA_ "GenSigStartValue" SG_ 2499763044 BATT_09_IsospiBreak 2;
BA_ "GenSigStartValue" SG_ 2499763044 BATT_09_IsolationIntFault 2;
BA_ "GenSigStartValue" SG_ 2499763044 BATT_09_IsolationExtFault 2;
BA_ "GenSigStartValue" SG_ 2499763044 BATT_09_event_12v_filter_error 2;
BA_ "GenSigStartValue" SG_ 2499763044 BATT_09_event_hall_eff_hi_rang_e 2;
BA_ "SystemSignalLongSymbol" SG_ 2499763044 BATT_09_event_hall_eff_hi_rang_e "BATT_09_event_hall_eff_hi_rang_err";
BA_ "GenSigStartValue" SG_ 2499763044 BATT_09_event_brick_volt_sns_ope 2;
BA_ "SystemSignalLongSymbol" SG_ 2499763044 BATT_09_event_brick_volt_sns_ope "BATT_09_event_brick_volt_sns_open";
BA_ "GenSigStartValue" SG_ 2499763044 BATT_09_event_5v_error 2;
BA_ "GenSigStartValue" SG_ 2499763044 BATT_09_event_3_3_hot_error 2;
BA_ "GenSigStartValue" SG_ 2499763044 BATT_09_event_12v_input_error 2;
BA_ "GenSigStartValue" SG_ 2499763044 BATT_09_event_1_25v_error 2;
BA_ "GenSigStartValue" SG_ 2499763044 BATT_09_event_shunt_MIA 2;
BA_ "GenSigStartValue" SG_ 2499763044 BATT_09_event_SBC_int_reg_error 2;
BA_ "GenSigStartValue" SG_ 2499763044 BATT_09_event_pos_3_3v_analog_er 2;
BA_ "SystemSignalLongSymbol" SG_ 2499763044 BATT_09_event_pos_3_3v_analog_er "BATT_09_event_pos_3_3v_analog_error";
BA_ "GenSigStartValue" SG_ 2499763044 BATT_09_event_outlt_clnt_thrm_op 2;
BA_ "SystemSignalLongSymbol" SG_ 2499763044 BATT_09_event_outlt_clnt_thrm_op "BATT_09_event_outlt_clnt_thrm_open";
BA_ "GenSigStartValue" SG_ 2499763044 BATT_09_event_neg_3_3_analog_err 2;
BA_ "SystemSignalLongSymbol" SG_ 2499763044 BATT_09_event_neg_3_3_analog_err "BATT_09_event_neg_3_3_analog_error";
BA_ "GenSigStartValue" SG_ 2499763044 BATT_09_event_inlet_clnt_thrm_op 2;
BA_ "SystemSignalLongSymbol" SG_ 2499763044 BATT_09_event_inlet_clnt_thrm_op "BATT_09_event_inlet_clnt_thrm_open";
BA_ "GenSigStartValue" SG_ 2499763044 BATT_09_event_hall_eff_lo_rang_e 2;
BA_ "SystemSignalLongSymbol" SG_ 2499763044 BATT_09_event_hall_eff_lo_rang_e "BATT_09_event_hall_eff_lo_rang_err";
BA_ "GenSigStartValue" SG_ 2499763044 BATT_09_event_outlt_clnt_thrm_sh 2;
BA_ "SystemSignalLongSymbol" SG_ 2499763044 BATT_09_event_outlt_clnt_thrm_sh "BATT_09_event_outlt_clnt_thrm_short";
BA_ "GenSigStartValue" SG_ 2499763044 BATT_09_event_inlet_clnt_thrm_sh 2;
BA_ "SystemSignalLongSymbol" SG_ 2499763044 BATT_09_event_inlet_clnt_thrm_sh "BATT_09_event_inlet_clnt_thrm_short";
BA_ "GenSigStartValue" SG_ 2499763044 BATT_09_event_3_3v_error 2;
BA_ "GenSigStartValue" SG_ 2499763044 BATT_10_HVILvoltageError 2;
BA_ "GenSigStartValue" SG_ 2499763044 BATT_10_HVILcurrentReturnError 2;
BA_ "GenSigStartValue" SG_ 2499763044 BATT_10_PosFcContWelded 2;
BA_ "GenSigStartValue" SG_ 2499763044 BATT_10_PosFcContStuckOpen 2;
BA_ "GenSigStartValue" SG_ 2499763044 BATT_10_NegFcContWelded 2;
BA_ "GenSigStartValue" SG_ 2499763044 BATT_10_NegFcContStuckOpen 2;
BA_ "GenSigStartValue" SG_ 2499763044 BATT_10_IsospiBreak 2;
BA_ "GenSigStartValue" SG_ 2499763044 BATT_10_IsolationIntFault 2;
BA_ "GenSigStartValue" SG_ 2499763044 BATT_10_IsolationExtFault 2;
BA_ "GenSigStartValue" SG_ 2499763044 BATT_10_event_12v_filter_error 2;
BA_ "GenSigStartValue" SG_ 2499763044 BATT_10_event_hall_eff_hi_rang_e 2;
BA_ "SystemSignalLongSymbol" SG_ 2499763044 BATT_10_event_hall_eff_hi_rang_e "BATT_10_event_hall_eff_hi_rang_err";
BA_ "GenSigStartValue" SG_ 2499763044 BATT_10_event_brick_volt_sns_ope 2;
BA_ "SystemSignalLongSymbol" SG_ 2499763044 BATT_10_event_brick_volt_sns_ope "BATT_10_event_brick_volt_sns_open";
BA_ "GenSigStartValue" SG_ 2499763044 BATT_10_event_5v_error 2;
BA_ "GenSigStartValue" SG_ 2499763044 BATT_10_event_3_3_hot_error 2;
BA_ "GenSigStartValue" SG_ 2499763044 BATT_10_event_12v_input_error 2;
BA_ "GenSigStartValue" SG_ 2499763044 BATT_10_event_1_25v_error 2;
BA_ "GenSigStartValue" SG_ 2499763044 BATT_10_event_shunt_MIA 2;
BA_ "GenSigStartValue" SG_ 2499763044 BATT_10_event_SBC_int_reg_error 2;
BA_ "GenSigStartValue" SG_ 2499763044 BATT_10_event_pos_3_3v_analog_er 2;
BA_ "SystemSignalLongSymbol" SG_ 2499763044 BATT_10_event_pos_3_3v_analog_er "BATT_10_event_pos_3_3v_analog_error";
BA_ "GenSigStartValue" SG_ 2499763044 BATT_10_event_outlt_clnt_thrm_op 2;
BA_ "SystemSignalLongSymbol" SG_ 2499763044 BATT_10_event_outlt_clnt_thrm_op "BATT_10_event_outlt_clnt_thrm_open";
BA_ "GenSigStartValue" SG_ 2499763044 BATT_10_event_neg_3_3_analog_err 2;
BA_ "SystemSignalLongSymbol" SG_ 2499763044 BATT_10_event_neg_3_3_analog_err "BATT_10_event_neg_3_3_analog_error";
BA_ "GenSigStartValue" SG_ 2499763044 BATT_10_event_inlet_clnt_thrm_op 2;
BA_ "SystemSignalLongSymbol" SG_ 2499763044 BATT_10_event_inlet_clnt_thrm_op "BATT_10_event_inlet_clnt_thrm_open";
BA_ "GenSigStartValue" SG_ 2499763044 BATT_10_event_hall_eff_lo_rang_e 2;
BA_ "SystemSignalLongSymbol" SG_ 2499763044 BATT_10_event_hall_eff_lo_rang_e "BATT_10_event_hall_eff_lo_rang_err";
BA_ "GenSigStartValue" SG_ 2499763044 BATT_10_event_outlt_clnt_thrm_sh 2;
BA_ "SystemSignalLongSymbol" SG_ 2499763044 BATT_10_event_outlt_clnt_thrm_sh "BATT_10_event_outlt_clnt_thrm_short";
BA_ "GenSigStartValue" SG_ 2499763044 BATT_10_event_inlet_clnt_thrm_sh 2;
BA_ "SystemSignalLongSymbol" SG_ 2499763044 BATT_10_event_inlet_clnt_thrm_sh "BATT_10_event_inlet_clnt_thrm_short";
BA_ "GenSigStartValue" SG_ 2499763044 BATT_10_event_3_3v_error 2;
BA_ "GenSigStartValue" SG_ 2499763044 BATT_11_HVILvoltageError 2;
BA_ "GenSigStartValue" SG_ 2499763044 BATT_11_HVILcurrentReturnError 2;
BA_ "GenSigStartValue" SG_ 2499763044 BATT_11_PosFcContWelded 2;
BA_ "GenSigStartValue" SG_ 2499763044 BATT_11_PosFcContStuckOpen 2;
BA_ "GenSigStartValue" SG_ 2499763044 BATT_11_NegFcContWelded 2;
BA_ "GenSigStartValue" SG_ 2499763044 BATT_11_NegFcContStuckOpen 2;
BA_ "GenSigStartValue" SG_ 2499763044 BATT_11_IsospiBreak 2;
BA_ "GenSigStartValue" SG_ 2499763044 BATT_11_IsolationIntFault 2;
BA_ "GenSigStartValue" SG_ 2499763044 BATT_11_IsolationExtFault 2;
BA_ "GenSigStartValue" SG_ 2499763044 BATT_11_event_12v_filter_error 2;
BA_ "GenSigStartValue" SG_ 2499763044 BATT_11_event_hall_eff_hi_rang_e 2;
BA_ "SystemSignalLongSymbol" SG_ 2499763044 BATT_11_event_hall_eff_hi_rang_e "BATT_11_event_hall_eff_hi_rang_err";
BA_ "GenSigStartValue" SG_ 2499763044 BATT_11_event_brick_volt_sns_ope 2;
BA_ "SystemSignalLongSymbol" SG_ 2499763044 BATT_11_event_brick_volt_sns_ope "BATT_11_event_brick_volt_sns_open";
BA_ "GenSigStartValue" SG_ 2499763044 BATT_11_event_5v_error 2;
BA_ "GenSigStartValue" SG_ 2499763044 BATT_11_event_3_3_hot_error 2;
BA_ "GenSigStartValue" SG_ 2499763044 BATT_11_event_12v_input_error 2;
BA_ "GenSigStartValue" SG_ 2499763044 BATT_11_event_1_25v_error 2;
BA_ "GenSigStartValue" SG_ 2499763044 BATT_11_event_shunt_MIA 2;
BA_ "GenSigStartValue" SG_ 2499763044 BATT_11_event_SBC_int_reg_error 2;
BA_ "GenSigStartValue" SG_ 2499763044 BATT_11_event_pos_3_3v_analog_er 2;
BA_ "SystemSignalLongSymbol" SG_ 2499763044 BATT_11_event_pos_3_3v_analog_er "BATT_11_event_pos_3_3v_analog_error";
BA_ "GenSigStartValue" SG_ 2499763044 BATT_11_event_outlt_clnt_thrm_op 2;
BA_ "SystemSignalLongSymbol" SG_ 2499763044 BATT_11_event_outlt_clnt_thrm_op "BATT_11_event_outlt_clnt_thrm_open";
BA_ "GenSigStartValue" SG_ 2499763044 BATT_11_event_neg_3_3_analog_err 2;
BA_ "SystemSignalLongSymbol" SG_ 2499763044 BATT_11_event_neg_3_3_analog_err "BATT_11_event_neg_3_3_analog_error";
BA_ "GenSigStartValue" SG_ 2499763044 BATT_11_event_inlet_clnt_thrm_op 2;
BA_ "SystemSignalLongSymbol" SG_ 2499763044 BATT_11_event_inlet_clnt_thrm_op "BATT_11_event_inlet_clnt_thrm_open";
BA_ "GenSigStartValue" SG_ 2499763044 BATT_11_event_hall_eff_lo_rang_e 2;
BA_ "SystemSignalLongSymbol" SG_ 2499763044 BATT_11_event_hall_eff_lo_rang_e "BATT_11_event_hall_eff_lo_rang_err";
BA_ "GenSigStartValue" SG_ 2499763044 BATT_11_event_outlt_clnt_thrm_sh 2;
BA_ "SystemSignalLongSymbol" SG_ 2499763044 BATT_11_event_outlt_clnt_thrm_sh "BATT_11_event_outlt_clnt_thrm_short";
BA_ "GenSigStartValue" SG_ 2499763044 BATT_11_event_inlet_clnt_thrm_sh 2;
BA_ "SystemSignalLongSymbol" SG_ 2499763044 BATT_11_event_inlet_clnt_thrm_sh "BATT_11_event_inlet_clnt_thrm_short";
BA_ "GenSigStartValue" SG_ 2499763044 BATT_11_event_3_3v_error 2;
BA_ "GenSigStartValue" SG_ 2499763044 BATT_12_HVILvoltageError 2;
BA_ "GenSigStartValue" SG_ 2499763044 BATT_12_HVILcurrentReturnError 2;
BA_ "GenSigStartValue" SG_ 2499763044 BATT_12_PosFcContWelded 2;
BA_ "GenSigStartValue" SG_ 2499763044 BATT_12_PosFcContStuckOpen 2;
BA_ "GenSigStartValue" SG_ 2499763044 BATT_12_NegFcContWelded 2;
BA_ "GenSigStartValue" SG_ 2499763044 BATT_12_NegFcContStuckOpen 2;
BA_ "GenSigStartValue" SG_ 2499763044 BATT_12_IsospiBreak 2;
BA_ "GenSigStartValue" SG_ 2499763044 BATT_12_IsolationIntFault 2;
BA_ "GenSigStartValue" SG_ 2499763044 BATT_12_IsolationExtFault 2;
BA_ "GenSigStartValue" SG_ 2499763044 BATT_12_event_12v_filter_error 2;
BA_ "GenSigStartValue" SG_ 2499763044 BATT_12_event_hall_eff_hi_rang_e 2;
BA_ "SystemSignalLongSymbol" SG_ 2499763044 BATT_12_event_hall_eff_hi_rang_e "BATT_12_event_hall_eff_hi_rang_err";
BA_ "GenSigStartValue" SG_ 2499763044 BATT_12_event_brick_volt_sns_ope 2;
BA_ "SystemSignalLongSymbol" SG_ 2499763044 BATT_12_event_brick_volt_sns_ope "BATT_12_event_brick_volt_sns_open";
BA_ "GenSigStartValue" SG_ 2499763044 BATT_12_event_5v_error 2;
BA_ "GenSigStartValue" SG_ 2499763044 BATT_12_event_3_3_hot_error 2;
BA_ "GenSigStartValue" SG_ 2499763044 BATT_12_event_12v_input_error 2;
BA_ "GenSigStartValue" SG_ 2499763044 BATT_12_event_1_25v_error 2;
BA_ "GenSigStartValue" SG_ 2499763044 BATT_12_event_shunt_MIA 2;
BA_ "GenSigStartValue" SG_ 2499763044 BATT_12_event_SBC_int_reg_error 2;
BA_ "GenSigStartValue" SG_ 2499763044 BATT_12_event_pos_3_3v_analog_er 2;
BA_ "SystemSignalLongSymbol" SG_ 2499763044 BATT_12_event_pos_3_3v_analog_er "BATT_12_event_pos_3_3v_analog_error";
BA_ "GenSigStartValue" SG_ 2499763044 BATT_12_event_outlt_clnt_thrm_op 2;
BA_ "SystemSignalLongSymbol" SG_ 2499763044 BATT_12_event_outlt_clnt_thrm_op "BATT_12_event_outlt_clnt_thrm_open";
BA_ "GenSigStartValue" SG_ 2499763044 BATT_12_event_neg_3_3_analog_err 2;
BA_ "SystemSignalLongSymbol" SG_ 2499763044 BATT_12_event_neg_3_3_analog_err "BATT_12_event_neg_3_3_analog_error";
BA_ "GenSigStartValue" SG_ 2499763044 BATT_12_event_inlet_clnt_thrm_op 2;
BA_ "SystemSignalLongSymbol" SG_ 2499763044 BATT_12_event_inlet_clnt_thrm_op "BATT_12_event_inlet_clnt_thrm_open";
BA_ "GenSigStartValue" SG_ 2499763044 BATT_12_event_hall_eff_lo_rang_e 2;
BA_ "SystemSignalLongSymbol" SG_ 2499763044 BATT_12_event_hall_eff_lo_rang_e "BATT_12_event_hall_eff_lo_rang_err";
BA_ "GenSigStartValue" SG_ 2499763044 BATT_12_event_outlt_clnt_thrm_sh 2;
BA_ "SystemSignalLongSymbol" SG_ 2499763044 BATT_12_event_outlt_clnt_thrm_sh "BATT_12_event_outlt_clnt_thrm_short";
BA_ "GenSigStartValue" SG_ 2499763044 BATT_12_event_inlet_clnt_thrm_sh 2;
BA_ "SystemSignalLongSymbol" SG_ 2499763044 BATT_12_event_inlet_clnt_thrm_sh "BATT_12_event_inlet_clnt_thrm_short";
BA_ "GenSigStartValue" SG_ 2499763044 BATT_12_event_3_3v_error 2;
BA_ "GenSigStartValue" SG_ 2499763044 BATT_13_HVILvoltageError 2;
BA_ "GenSigStartValue" SG_ 2499763044 BATT_13_HVILcurrentReturnError 2;
BA_ "GenSigStartValue" SG_ 2499763044 BATT_13_PosFcContWelded 2;
BA_ "GenSigStartValue" SG_ 2499763044 BATT_13_PosFcContStuckOpen 2;
BA_ "GenSigStartValue" SG_ 2499763044 BATT_13_NegFcContWelded 2;
BA_ "GenSigStartValue" SG_ 2499763044 BATT_13_NegFcContStuckOpen 2;
BA_ "GenSigStartValue" SG_ 2499763044 BATT_13_IsospiBreak 2;
BA_ "GenSigStartValue" SG_ 2499763044 BATT_13_IsolationIntFault 2;
BA_ "GenSigStartValue" SG_ 2499763044 BATT_13_IsolationExtFault 2;
BA_ "GenSigStartValue" SG_ 2499763044 BATT_13_event_12v_filter_error 2;
BA_ "GenSigStartValue" SG_ 2499763044 BATT_13_event_hall_eff_hi_rang_e 2;
BA_ "SystemSignalLongSymbol" SG_ 2499763044 BATT_13_event_hall_eff_hi_rang_e "BATT_13_event_hall_eff_hi_rang_err";
BA_ "GenSigStartValue" SG_ 2499763044 BATT_13_event_brick_volt_sns_ope 2;
BA_ "SystemSignalLongSymbol" SG_ 2499763044 BATT_13_event_brick_volt_sns_ope "BATT_13_event_brick_volt_sns_open";
BA_ "GenSigStartValue" SG_ 2499763044 BATT_13_event_5v_error 2;
BA_ "GenSigStartValue" SG_ 2499763044 BATT_13_event_3_3_hot_error 2;
BA_ "GenSigStartValue" SG_ 2499763044 BATT_13_event_12v_input_error 2;
BA_ "GenSigStartValue" SG_ 2499763044 BATT_13_event_1_25v_error 2;
BA_ "GenSigStartValue" SG_ 2499763044 BATT_13_event_shunt_MIA 2;
BA_ "GenSigStartValue" SG_ 2499763044 BATT_13_event_SBC_int_reg_error 2;
BA_ "GenSigStartValue" SG_ 2499763044 BATT_13_event_pos_3_3v_analog_er 2;
BA_ "SystemSignalLongSymbol" SG_ 2499763044 BATT_13_event_pos_3_3v_analog_er "BATT_13_event_pos_3_3v_analog_error";
BA_ "GenSigStartValue" SG_ 2499763044 BATT_13_event_outlt_clnt_thrm_op 2;
BA_ "SystemSignalLongSymbol" SG_ 2499763044 BATT_13_event_outlt_clnt_thrm_op "BATT_13_event_outlt_clnt_thrm_open";
BA_ "GenSigStartValue" SG_ 2499763044 BATT_13_event_neg_3_3_analog_err 2;
BA_ "SystemSignalLongSymbol" SG_ 2499763044 BATT_13_event_neg_3_3_analog_err "BATT_13_event_neg_3_3_analog_error";
BA_ "GenSigStartValue" SG_ 2499763044 BATT_13_event_inlet_clnt_thrm_op 2;
BA_ "SystemSignalLongSymbol" SG_ 2499763044 BATT_13_event_inlet_clnt_thrm_op "BATT_13_event_inlet_clnt_thrm_open";
BA_ "GenSigStartValue" SG_ 2499763044 BATT_13_event_hall_eff_lo_rang_e 2;
BA_ "SystemSignalLongSymbol" SG_ 2499763044 BATT_13_event_hall_eff_lo_rang_e "BATT_13_event_hall_eff_lo_rang_err";
BA_ "GenSigStartValue" SG_ 2499763044 BATT_13_event_outlt_clnt_thrm_sh 2;
BA_ "SystemSignalLongSymbol" SG_ 2499763044 BATT_13_event_outlt_clnt_thrm_sh "BATT_13_event_outlt_clnt_thrm_short";
BA_ "GenSigStartValue" SG_ 2499763044 BATT_13_event_inlet_clnt_thrm_sh 2;
BA_ "SystemSignalLongSymbol" SG_ 2499763044 BATT_13_event_inlet_clnt_thrm_sh "BATT_13_event_inlet_clnt_thrm_short";
BA_ "GenSigStartValue" SG_ 2499763044 BATT_13_event_3_3v_error 2;
BA_ "GenSigStartValue" SG_ 2499763044 BATT_14_HVILvoltageError 2;
BA_ "GenSigStartValue" SG_ 2499763044 BATT_14_HVILcurrentReturnError 2;
BA_ "GenSigStartValue" SG_ 2499763044 BATT_14_PosFcContWelded 2;
BA_ "GenSigStartValue" SG_ 2499763044 BATT_14_PosFcContStuckOpen 2;
BA_ "GenSigStartValue" SG_ 2499763044 BATT_14_NegFcContWelded 2;
BA_ "GenSigStartValue" SG_ 2499763044 BATT_14_NegFcContStuckOpen 2;
BA_ "GenSigStartValue" SG_ 2499763044 BATT_14_IsospiBreak 2;
BA_ "GenSigStartValue" SG_ 2499763044 BATT_14_IsolationIntFault 2;
BA_ "GenSigStartValue" SG_ 2499763044 BATT_14_IsolationExtFault 2;
BA_ "GenSigStartValue" SG_ 2499763044 BATT_14_event_12v_filter_error 2;
BA_ "GenSigStartValue" SG_ 2499763044 BATT_14_event_hall_eff_hi_rang_e 2;
BA_ "SystemSignalLongSymbol" SG_ 2499763044 BATT_14_event_hall_eff_hi_rang_e "BATT_14_event_hall_eff_hi_rang_err";
BA_ "GenSigStartValue" SG_ 2499763044 BATT_14_event_brick_volt_sns_ope 2;
BA_ "SystemSignalLongSymbol" SG_ 2499763044 BATT_14_event_brick_volt_sns_ope "BATT_14_event_brick_volt_sns_open";
BA_ "GenSigStartValue" SG_ 2499763044 BATT_14_event_5v_error 2;
BA_ "GenSigStartValue" SG_ 2499763044 BATT_14_event_3_3_hot_error 2;
BA_ "GenSigStartValue" SG_ 2499763044 BATT_14_event_12v_input_error 2;
BA_ "GenSigStartValue" SG_ 2499763044 BATT_14_event_1_25v_error 2;
BA_ "GenSigStartValue" SG_ 2499763044 BATT_14_event_shunt_MIA 2;
BA_ "GenSigStartValue" SG_ 2499763044 BATT_14_event_SBC_int_reg_error 2;
BA_ "GenSigStartValue" SG_ 2499763044 BATT_14_event_pos_3_3v_analog_er 2;
BA_ "SystemSignalLongSymbol" SG_ 2499763044 BATT_14_event_pos_3_3v_analog_er "BATT_14_event_pos_3_3v_analog_error";
BA_ "GenSigStartValue" SG_ 2499763044 BATT_14_event_outlt_clnt_thrm_op 2;
BA_ "SystemSignalLongSymbol" SG_ 2499763044 BATT_14_event_outlt_clnt_thrm_op "BATT_14_event_outlt_clnt_thrm_open";
BA_ "GenSigStartValue" SG_ 2499763044 BATT_14_event_neg_3_3_analog_err 2;
BA_ "SystemSignalLongSymbol" SG_ 2499763044 BATT_14_event_neg_3_3_analog_err "BATT_14_event_neg_3_3_analog_error";
BA_ "GenSigStartValue" SG_ 2499763044 BATT_14_event_inlet_clnt_thrm_op 2;
BA_ "SystemSignalLongSymbol" SG_ 2499763044 BATT_14_event_inlet_clnt_thrm_op "BATT_14_event_inlet_clnt_thrm_open";
BA_ "GenSigStartValue" SG_ 2499763044 BATT_14_event_hall_eff_lo_rang_e 2;
BA_ "SystemSignalLongSymbol" SG_ 2499763044 BATT_14_event_hall_eff_lo_rang_e "BATT_14_event_hall_eff_lo_rang_err";
BA_ "GenSigStartValue" SG_ 2499763044 BATT_14_event_outlt_clnt_thrm_sh 2;
BA_ "SystemSignalLongSymbol" SG_ 2499763044 BATT_14_event_outlt_clnt_thrm_sh "BATT_14_event_outlt_clnt_thrm_short";
BA_ "GenSigStartValue" SG_ 2499763044 BATT_14_event_inlet_clnt_thrm_sh 2;
BA_ "SystemSignalLongSymbol" SG_ 2499763044 BATT_14_event_inlet_clnt_thrm_sh "BATT_14_event_inlet_clnt_thrm_short";
BA_ "GenSigStartValue" SG_ 2499763044 BATT_14_event_3_3v_error 2;
BA_ "GenSigStartValue" SG_ 2499763044 BATT_15_HVILvoltageError 2;
BA_ "GenSigStartValue" SG_ 2499763044 BATT_15_HVILcurrentReturnError 2;
BA_ "GenSigStartValue" SG_ 2499763044 BATT_15_PosFcContWelded 2;
BA_ "GenSigStartValue" SG_ 2499763044 BATT_15_PosFcContStuckOpen 2;
BA_ "GenSigStartValue" SG_ 2499763044 BATT_15_NegFcContWelded 2;
BA_ "GenSigStartValue" SG_ 2499763044 BATT_15_NegFcContStuckOpen 2;
BA_ "GenSigStartValue" SG_ 2499763044 BATT_15_IsospiBreak 2;
BA_ "GenSigStartValue" SG_ 2499763044 BATT_15_IsolationIntFault 2;
BA_ "GenSigStartValue" SG_ 2499763044 BATT_15_IsolationExtFault 2;
BA_ "GenSigStartValue" SG_ 2499763044 BATT_15_event_12v_filter_error 2;
BA_ "GenSigStartValue" SG_ 2499763044 BATT_15_event_hall_eff_hi_rang_e 2;
BA_ "SystemSignalLongSymbol" SG_ 2499763044 BATT_15_event_hall_eff_hi_rang_e "BATT_15_event_hall_eff_hi_rang_err";
BA_ "GenSigStartValue" SG_ 2499763044 BATT_15_event_brick_volt_sns_ope 2;
BA_ "SystemSignalLongSymbol" SG_ 2499763044 BATT_15_event_brick_volt_sns_ope "BATT_15_event_brick_volt_sns_open";
BA_ "GenSigStartValue" SG_ 2499763044 BATT_15_event_5v_error 2;
BA_ "GenSigStartValue" SG_ 2499763044 BATT_15_event_3_3_hot_error 2;
BA_ "GenSigStartValue" SG_ 2499763044 BATT_15_event_12v_input_error 2;
BA_ "GenSigStartValue" SG_ 2499763044 BATT_15_event_1_25v_error 2;
BA_ "GenSigStartValue" SG_ 2499763044 BATT_15_event_shunt_MIA 2;
BA_ "GenSigStartValue" SG_ 2499763044 BATT_15_event_SBC_int_reg_error 2;
BA_ "GenSigStartValue" SG_ 2499763044 BATT_15_event_pos_3_3v_analog_er 2;
BA_ "SystemSignalLongSymbol" SG_ 2499763044 BATT_15_event_pos_3_3v_analog_er "BATT_15_event_pos_3_3v_analog_error";
BA_ "GenSigStartValue" SG_ 2499763044 BATT_15_event_outlt_clnt_thrm_op 2;
BA_ "SystemSignalLongSymbol" SG_ 2499763044 BATT_15_event_outlt_clnt_thrm_op "BATT_15_event_outlt_clnt_thrm_open";
BA_ "GenSigStartValue" SG_ 2499763044 BATT_15_event_neg_3_3_analog_err 2;
BA_ "SystemSignalLongSymbol" SG_ 2499763044 BATT_15_event_neg_3_3_analog_err "BATT_15_event_neg_3_3_analog_error";
BA_ "GenSigStartValue" SG_ 2499763044 BATT_15_event_inlet_clnt_thrm_op 2;
BA_ "SystemSignalLongSymbol" SG_ 2499763044 BATT_15_event_inlet_clnt_thrm_op "BATT_15_event_inlet_clnt_thrm_open";
BA_ "GenSigStartValue" SG_ 2499763044 BATT_15_event_hall_eff_lo_rang_e 2;
BA_ "SystemSignalLongSymbol" SG_ 2499763044 BATT_15_event_hall_eff_lo_rang_e "BATT_15_event_hall_eff_lo_rang_err";
BA_ "GenSigStartValue" SG_ 2499763044 BATT_15_event_outlt_clnt_thrm_sh 2;
BA_ "SystemSignalLongSymbol" SG_ 2499763044 BATT_15_event_outlt_clnt_thrm_sh "BATT_15_event_outlt_clnt_thrm_short";
BA_ "GenSigStartValue" SG_ 2499763044 BATT_15_event_inlet_clnt_thrm_sh 2;
BA_ "SystemSignalLongSymbol" SG_ 2499763044 BATT_15_event_inlet_clnt_thrm_sh "BATT_15_event_inlet_clnt_thrm_short";
BA_ "GenSigStartValue" SG_ 2499763044 BATT_15_event_3_3v_error 2;
VAL_ 2499763044 BATT_01_HVILvoltageError 3 "Error" 2 "SNA" 1 "Active" 0 "Inactive" ;
VAL_ 2499763044 BATT_01_HVILcurrentReturnError 3 "Error" 2 "SNA" 1 "Active" 0 "Inactive" ;
VAL_ 2499763044 BATT_01_PosFcContWelded 3 "Error" 2 "SNA" 1 "Active" 0 "Inactive" ;
VAL_ 2499763044 BATT_01_PosFcContStuckOpen 3 "Error" 2 "SNA" 1 "Active" 0 "Inactive" ;
VAL_ 2499763044 BATT_01_NegFcContWelded 3 "Error" 2 "SNA" 1 "Active" 0 "Inactive" ;
VAL_ 2499763044 BATT_01_NegFcContStuckOpen 3 "Error" 2 "SNA" 1 "Active" 0 "Inactive" ;
VAL_ 2499763044 BATT_01_IsospiBreak 3 "Error" 2 "SNA" 1 "Active" 0 "Inactive" ;
VAL_ 2499763044 BATT_01_IsolationIntFault 3 "Error" 2 "SNA" 1 "Active" 0 "Inactive" ;
VAL_ 2499763044 BATT_01_IsolationExtFault 3 "Error" 2 "SNA" 1 "Active" 0 "Inactive" ;
VAL_ 2499763044 BATT_01_event_12v_filter_error 3 "Error" 2 "SNA" 1 "Active" 0 "Inactive" ;
VAL_ 2499763044 BATT_01_event_hall_eff_hi_rang_e 3 "Error" 2 "SNA" 1 "Active" 0 "Inactive" ;
VAL_ 2499763044 BATT_01_event_brick_volt_sns_ope 3 "Error" 2 "SNA" 1 "Active" 0 "Inactive" ;
VAL_ 2499763044 BATT_01_event_5v_error 3 "Error" 2 "SNA" 1 "Active" 0 "Inactive" ;
VAL_ 2499763044 BATT_01_event_3_3_hot_error 3 "Error" 2 "SNA" 1 "Active" 0 "Inactive" ;
VAL_ 2499763044 BATT_01_event_12v_input_error 3 "Error" 2 "SNA" 1 "Active" 0 "Inactive" ;
VAL_ 2499763044 BATT_01_event_1_25v_error 3 "Error" 2 "SNA" 1 "Active" 0 "Inactive" ;
VAL_ 2499763044 BATT_01_event_shunt_MIA 3 "Error" 2 "SNA" 1 "Active" 0 "Inactive" ;
VAL_ 2499763044 BATT_01_event_SBC_int_reg_error 3 "Error" 2 "SNA" 1 "Active" 0 "Inactive" ;
VAL_ 2499763044 BATT_01_event_pos_3_3v_analog_er 3 "Error" 2 "SNA" 1 "Active" 0 "Inactive" ;
VAL_ 2499763044 BATT_01_event_outlt_clnt_thrm_op 3 "Error" 2 "SNA" 1 "Active" 0 "Inactive" ;
VAL_ 2499763044 BATT_01_event_neg_3_3_analog_err 3 "Error" 2 "SNA" 1 "Active" 0 "Inactive" ;
VAL_ 2499763044 BATT_01_event_inlet_clnt_thrm_op 3 "Error" 2 "SNA" 1 "Active" 0 "Inactive" ;
VAL_ 2499763044 BATT_01_event_hall_eff_lo_rang_e 3 "Error" 2 "SNA" 1 "Active" 0 "Inactive" ;
VAL_ 2499763044 BATT_01_event_outlt_clnt_thrm_sh 3 "Error" 2 "SNA" 1 "Active" 0 "Inactive" ;
VAL_ 2499763044 BATT_01_event_inlet_clnt_thrm_sh 3 "Error" 2 "SNA" 1 "Active" 0 "Inactive" ;
VAL_ 2499763044 BATT_01_event_3_3v_error 3 "Error" 2 "SNA" 1 "Active" 0 "Inactive" ;
VAL_ 2499763044 BATT_02_HVILvoltageError 3 "Error" 2 "SNA" 1 "Active" 0 "Inactive" ;
VAL_ 2499763044 BATT_02_HVILcurrentReturnError 3 "Error" 2 "SNA" 1 "Active" 0 "Inactive" ;
VAL_ 2499763044 BATT_02_PosFcContWelded 3 "Error" 2 "SNA" 1 "Active" 0 "Inactive" ;
VAL_ 2499763044 BATT_02_PosFcContStuckOpen 3 "Error" 2 "SNA" 1 "Active" 0 "Inactive" ;
VAL_ 2499763044 BATT_02_NegFcContWelded 3 "Error" 2 "SNA" 1 "Active" 0 "Inactive" ;
VAL_ 2499763044 BATT_02_NegFcContStuckOpen 3 "Error" 2 "SNA" 1 "Active" 0 "Inactive" ;
VAL_ 2499763044 BATT_02_IsospiBreak 3 "Error" 2 "SNA" 1 "Active" 0 "Inactive" ;
VAL_ 2499763044 BATT_02_IsolationIntFault 3 "Error" 2 "SNA" 1 "Active" 0 "Inactive" ;
VAL_ 2499763044 BATT_02_IsolationExtFault 3 "Error" 2 "SNA" 1 "Active" 0 "Inactive" ;
VAL_ 2499763044 BATT_02_event_12v_filter_error 3 "Error" 2 "SNA" 1 "Active" 0 "Inactive" ;
VAL_ 2499763044 BATT_02_event_hall_eff_hi_rang_e 3 "Error" 2 "SNA" 1 "Active" 0 "Inactive" ;
VAL_ 2499763044 BATT_02_event_brick_volt_sns_ope 3 "Error" 2 "SNA" 1 "Active" 0 "Inactive" ;
VAL_ 2499763044 BATT_02_event_5v_error 3 "Error" 2 "SNA" 1 "Active" 0 "Inactive" ;
VAL_ 2499763044 BATT_02_event_3_3_hot_error 3 "Error" 2 "SNA" 1 "Active" 0 "Inactive" ;
VAL_ 2499763044 BATT_02_event_12v_input_error 3 "Error" 2 "SNA" 1 "Active" 0 "Inactive" ;
VAL_ 2499763044 BATT_02_event_1_25v_error 3 "Error" 2 "SNA" 1 "Active" 0 "Inactive" ;
VAL_ 2499763044 BATT_02_event_shunt_MIA 3 "Error" 2 "SNA" 1 "Active" 0 "Inactive" ;
VAL_ 2499763044 BATT_02_event_SBC_int_reg_error 3 "Error" 2 "SNA" 1 "Active" 0 "Inactive" ;
VAL_ 2499763044 BATT_02_event_pos_3_3v_analog_er 3 "Error" 2 "SNA" 1 "Active" 0 "Inactive" ;
VAL_ 2499763044 BATT_02_event_outlt_clnt_thrm_op 3 "Error" 2 "SNA" 1 "Active" 0 "Inactive" ;
VAL_ 2499763044 BATT_02_event_neg_3_3_analog_err 3 "Error" 2 "SNA" 1 "Active" 0 "Inactive" ;
VAL_ 2499763044 BATT_02_event_inlet_clnt_thrm_op 3 "Error" 2 "SNA" 1 "Active" 0 "Inactive" ;
VAL_ 2499763044 BATT_02_event_hall_eff_lo_rang_e 3 "Error" 2 "SNA" 1 "Active" 0 "Inactive" ;
VAL_ 2499763044 BATT_02_event_outlt_clnt_thrm_sh 3 "Error" 2 "SNA" 1 "Active" 0 "Inactive" ;
VAL_ 2499763044 BATT_02_event_inlet_clnt_thrm_sh 3 "Error" 2 "SNA" 1 "Active" 0 "Inactive" ;
VAL_ 2499763044 BATT_02_event_3_3v_error 3 "Error" 2 "SNA" 1 "Active" 0 "Inactive" ;
VAL_ 2499763044 BATT_03_HVILvoltageError 3 "Error" 2 "SNA" 1 "Active" 0 "Inactive" ;
VAL_ 2499763044 BATT_03_HVILcurrentReturnError 3 "Error" 2 "SNA" 1 "Active" 0 "Inactive" ;
VAL_ 2499763044 BATT_03_PosFcContWelded 3 "Error" 2 "SNA" 1 "Active" 0 "Inactive" ;
VAL_ 2499763044 BATT_03_PosFcContStuckOpen 3 "Error" 2 "SNA" 1 "Active" 0 "Inactive" ;
VAL_ 2499763044 BATT_03_NegFcContWelded 3 "Error" 2 "SNA" 1 "Active" 0 "Inactive" ;
VAL_ 2499763044 BATT_03_NegFcContStuckOpen 3 "Error" 2 "SNA" 1 "Active" 0 "Inactive" ;
VAL_ 2499763044 BATT_03_IsospiBreak 3 "Error" 2 "SNA" 1 "Active" 0 "Inactive" ;
VAL_ 2499763044 BATT_03_IsolationIntFault 3 "Error" 2 "SNA" 1 "Active" 0 "Inactive" ;
VAL_ 2499763044 BATT_03_IsolationExtFault 3 "Error" 2 "SNA" 1 "Active" 0 "Inactive" ;
VAL_ 2499763044 BATT_03_event_12v_filter_error 3 "Error" 2 "SNA" 1 "Active" 0 "Inactive" ;
VAL_ 2499763044 BATT_03_event_hall_eff_hi_rang_e 3 "Error" 2 "SNA" 1 "Active" 0 "Inactive" ;
VAL_ 2499763044 BATT_03_event_brick_volt_sns_ope 3 "Error" 2 "SNA" 1 "Active" 0 "Inactive" ;
VAL_ 2499763044 BATT_03_event_5v_error 3 "Error" 2 "SNA" 1 "Active" 0 "Inactive" ;
VAL_ 2499763044 BATT_03_event_3_3_hot_error 3 "Error" 2 "SNA" 1 "Active" 0 "Inactive" ;
VAL_ 2499763044 BATT_03_event_12v_input_error 3 "Error" 2 "SNA" 1 "Active" 0 "Inactive" ;
VAL_ 2499763044 BATT_03_event_1_25v_error 3 "Error" 2 "SNA" 1 "Active" 0 "Inactive" ;
VAL_ 2499763044 BATT_03_event_shunt_MIA 3 "Error" 2 "SNA" 1 "Active" 0 "Inactive" ;
VAL_ 2499763044 BATT_03_event_SBC_int_reg_error 3 "Error" 2 "SNA" 1 "Active" 0 "Inactive" ;
VAL_ 2499763044 BATT_03_event_pos_3_3v_analog_er 3 "Error" 2 "SNA" 1 "Active" 0 "Inactive" ;
VAL_ 2499763044 BATT_03_event_outlt_clnt_thrm_op 3 "Error" 2 "SNA" 1 "Active" 0 "Inactive" ;
VAL_ 2499763044 BATT_03_event_neg_3_3_analog_err 3 "Error" 2 "SNA" 1 "Active" 0 "Inactive" ;
VAL_ 2499763044 BATT_03_event_inlet_clnt_thrm_op 3 "Error" 2 "SNA" 1 "Active" 0 "Inactive" ;
VAL_ 2499763044 BATT_03_event_hall_eff_lo_rang_e 3 "Error" 2 "SNA" 1 "Active" 0 "Inactive" ;
VAL_ 2499763044 BATT_03_event_outlt_clnt_thrm_sh 3 "Error" 2 "SNA" 1 "Active" 0 "Inactive" ;
VAL_ 2499763044 BATT_03_event_inlet_clnt_thrm_sh 3 "Error" 2 "SNA" 1 "Active" 0 "Inactive" ;
VAL_ 2499763044 BATT_03_event_3_3v_error 3 "Error" 2 "SNA" 1 "Active" 0 "Inactive" ;
VAL_ 2499763044 BATT_04_HVILvoltageError 3 "Error" 2 "SNA" 1 "Active" 0 "Inactive" ;
VAL_ 2499763044 BATT_04_HVILcurrentReturnError 3 "Error" 2 "SNA" 1 "Active" 0 "Inactive" ;
VAL_ 2499763044 BATT_04_PosFcContWelded 3 "Error" 2 "SNA" 1 "Active" 0 "Inactive" ;
VAL_ 2499763044 BATT_04_PosFcContStuckOpen 3 "Error" 2 "SNA" 1 "Active" 0 "Inactive" ;
VAL_ 2499763044 BATT_04_NegFcContWelded 3 "Error" 2 "SNA" 1 "Active" 0 "Inactive" ;
VAL_ 2499763044 BATT_04_NegFcContStuckOpen 3 "Error" 2 "SNA" 1 "Active" 0 "Inactive" ;
VAL_ 2499763044 BATT_04_IsospiBreak 3 "Error" 2 "SNA" 1 "Active" 0 "Inactive" ;
VAL_ 2499763044 BATT_04_IsolationIntFault 3 "Error" 2 "SNA" 1 "Active" 0 "Inactive" ;
VAL_ 2499763044 BATT_04_IsolationExtFault 3 "Error" 2 "SNA" 1 "Active" 0 "Inactive" ;
VAL_ 2499763044 BATT_04_event_12v_filter_error 3 "Error" 2 "SNA" 1 "Active" 0 "Inactive" ;
VAL_ 2499763044 BATT_04_event_hall_eff_hi_rang_e 3 "Error" 2 "SNA" 1 "Active" 0 "Inactive" ;
VAL_ 2499763044 BATT_04_event_brick_volt_sns_ope 3 "Error" 2 "SNA" 1 "Active" 0 "Inactive" ;
VAL_ 2499763044 BATT_04_event_5v_error 3 "Error" 2 "SNA" 1 "Active" 0 "Inactive" ;
VAL_ 2499763044 BATT_04_event_3_3_hot_error 3 "Error" 2 "SNA" 1 "Active" 0 "Inactive" ;
VAL_ 2499763044 BATT_04_event_12v_input_error 3 "Error" 2 "SNA" 1 "Active" 0 "Inactive" ;
VAL_ 2499763044 BATT_04_event_1_25v_error 3 "Error" 2 "SNA" 1 "Active" 0 "Inactive" ;
VAL_ 2499763044 BATT_04_event_shunt_MIA 3 "Error" 2 "SNA" 1 "Active" 0 "Inactive" ;
VAL_ 2499763044 BATT_04_event_SBC_int_reg_error 3 "Error" 2 "SNA" 1 "Active" 0 "Inactive" ;
VAL_ 2499763044 BATT_04_event_pos_3_3v_analog_er 3 "Error" 2 "SNA" 1 "Active" 0 "Inactive" ;
VAL_ 2499763044 BATT_04_event_outlt_clnt_thrm_op 3 "Error" 2 "SNA" 1 "Active" 0 "Inactive" ;
VAL_ 2499763044 BATT_04_event_neg_3_3_analog_err 3 "Error" 2 "SNA" 1 "Active" 0 "Inactive" ;
VAL_ 2499763044 BATT_04_event_inlet_clnt_thrm_op 3 "Error" 2 "SNA" 1 "Active" 0 "Inactive" ;
VAL_ 2499763044 BATT_04_event_hall_eff_lo_rang_e 3 "Error" 2 "SNA" 1 "Active" 0 "Inactive" ;
VAL_ 2499763044 BATT_04_event_outlt_clnt_thrm_sh 3 "Error" 2 "SNA" 1 "Active" 0 "Inactive" ;
VAL_ 2499763044 BATT_04_event_inlet_clnt_thrm_sh 3 "Error" 2 "SNA" 1 "Active" 0 "Inactive" ;
VAL_ 2499763044 BATT_04_event_3_3v_error 3 "Error" 2 "SNA" 1 "Active" 0 "Inactive" ;
VAL_ 2499763044 BATT_05_HVILvoltageError 3 "Error" 2 "SNA" 1 "Active" 0 "Inactive" ;
VAL_ 2499763044 BATT_05_HVILcurrentReturnError 3 "Error" 2 "SNA" 1 "Active" 0 "Inactive" ;
VAL_ 2499763044 BATT_05_PosFcContWelded 3 "Error" 2 "SNA" 1 "Active" 0 "Inactive" ;
VAL_ 2499763044 BATT_05_PosFcContStuckOpen 3 "Error" 2 "SNA" 1 "Active" 0 "Inactive" ;
VAL_ 2499763044 BATT_05_NegFcContWelded 3 "Error" 2 "SNA" 1 "Active" 0 "Inactive" ;
VAL_ 2499763044 BATT_05_NegFcContStuckOpen 3 "Error" 2 "SNA" 1 "Active" 0 "Inactive" ;
VAL_ 2499763044 BATT_05_IsospiBreak 3 "Error" 2 "SNA" 1 "Active" 0 "Inactive" ;
VAL_ 2499763044 BATT_05_IsolationIntFault 3 "Error" 2 "SNA" 1 "Active" 0 "Inactive" ;
VAL_ 2499763044 BATT_05_IsolationExtFault 3 "Error" 2 "SNA" 1 "Active" 0 "Inactive" ;
VAL_ 2499763044 BATT_05_event_12v_filter_error 3 "Error" 2 "SNA" 1 "Active" 0 "Inactive" ;
VAL_ 2499763044 BATT_05_event_hall_eff_hi_rang_e 3 "Error" 2 "SNA" 1 "Active" 0 "Inactive" ;
VAL_ 2499763044 BATT_05_event_brick_volt_sns_ope 3 "Error" 2 "SNA" 1 "Active" 0 "Inactive" ;
VAL_ 2499763044 BATT_05_event_5v_error 3 "Error" 2 "SNA" 1 "Active" 0 "Inactive" ;
VAL_ 2499763044 BATT_05_event_3_3_hot_error 3 "Error" 2 "SNA" 1 "Active" 0 "Inactive" ;
VAL_ 2499763044 BATT_05_event_12v_input_error 3 "Error" 2 "SNA" 1 "Active" 0 "Inactive" ;
VAL_ 2499763044 BATT_05_event_1_25v_error 3 "Error" 2 "SNA" 1 "Active" 0 "Inactive" ;
VAL_ 2499763044 BATT_05_event_shunt_MIA 3 "Error" 2 "SNA" 1 "Active" 0 "Inactive" ;
VAL_ 2499763044 BATT_05_event_SBC_int_reg_error 3 "Error" 2 "SNA" 1 "Active" 0 "Inactive" ;
VAL_ 2499763044 BATT_05_event_pos_3_3v_analog_er 3 "Error" 2 "SNA" 1 "Active" 0 "Inactive" ;
VAL_ 2499763044 BATT_05_event_outlt_clnt_thrm_op 3 "Error" 2 "SNA" 1 "Active" 0 "Inactive" ;
VAL_ 2499763044 BATT_05_event_neg_3_3_analog_err 3 "Error" 2 "SNA" 1 "Active" 0 "Inactive" ;
VAL_ 2499763044 BATT_05_event_inlet_clnt_thrm_op 3 "Error" 2 "SNA" 1 "Active" 0 "Inactive" ;
VAL_ 2499763044 BATT_05_event_hall_eff_lo_rang_e 3 "Error" 2 "SNA" 1 "Active" 0 "Inactive" ;
VAL_ 2499763044 BATT_05_event_outlt_clnt_thrm_sh 3 "Error" 2 "SNA" 1 "Active" 0 "Inactive" ;
VAL_ 2499763044 BATT_05_event_inlet_clnt_thrm_sh 3 "Error" 2 "SNA" 1 "Active" 0 "Inactive" ;
VAL_ 2499763044 BATT_05_event_3_3v_error 3 "Error" 2 "SNA" 1 "Active" 0 "Inactive" ;
VAL_ 2499763044 BATT_06_HVILvoltageError 3 "Error" 2 "SNA" 1 "Active" 0 "Inactive" ;
VAL_ 2499763044 BATT_06_HVILcurrentReturnError 3 "Error" 2 "SNA" 1 "Active" 0 "Inactive" ;
VAL_ 2499763044 BATT_06_PosFcContWelded 3 "Error" 2 "SNA" 1 "Active" 0 "Inactive" ;
VAL_ 2499763044 BATT_06_PosFcContStuckOpen 3 "Error" 2 "SNA" 1 "Active" 0 "Inactive" ;
VAL_ 2499763044 BATT_06_NegFcContWelded 3 "Error" 2 "SNA" 1 "Active" 0 "Inactive" ;
VAL_ 2499763044 BATT_06_NegFcContStuckOpen 3 "Error" 2 "SNA" 1 "Active" 0 "Inactive" ;
VAL_ 2499763044 BATT_06_IsospiBreak 3 "Error" 2 "SNA" 1 "Active" 0 "Inactive" ;
VAL_ 2499763044 BATT_06_IsolationIntFault 3 "Error" 2 "SNA" 1 "Active" 0 "Inactive" ;
VAL_ 2499763044 BATT_06_IsolationExtFault 3 "Error" 2 "SNA" 1 "Active" 0 "Inactive" ;
VAL_ 2499763044 BATT_06_event_12v_filter_error 3 "Error" 2 "SNA" 1 "Active" 0 "Inactive" ;
VAL_ 2499763044 BATT_06_event_hall_eff_hi_rang_e 3 "Error" 2 "SNA" 1 "Active" 0 "Inactive" ;
VAL_ 2499763044 BATT_06_event_brick_volt_sns_ope 3 "Error" 2 "SNA" 1 "Active" 0 "Inactive" ;
VAL_ 2499763044 BATT_06_event_5v_error 3 "Error" 2 "SNA" 1 "Active" 0 "Inactive" ;
VAL_ 2499763044 BATT_06_event_3_3_hot_error 3 "Error" 2 "SNA" 1 "Active" 0 "Inactive" ;
VAL_ 2499763044 BATT_06_event_12v_input_error 3 "Error" 2 "SNA" 1 "Active" 0 "Inactive" ;
VAL_ 2499763044 BATT_06_event_1_25v_error 3 "Error" 2 "SNA" 1 "Active" 0 "Inactive" ;
VAL_ 2499763044 BATT_06_event_shunt_MIA 3 "Error" 2 "SNA" 1 "Active" 0 "Inactive" ;
VAL_ 2499763044 BATT_06_event_SBC_int_reg_error 3 "Error" 2 "SNA" 1 "Active" 0 "Inactive" ;
VAL_ 2499763044 BATT_06_event_pos_3_3v_analog_er 3 "Error" 2 "SNA" 1 "Active" 0 "Inactive" ;
VAL_ 2499763044 BATT_06_event_outlt_clnt_thrm_op 3 "Error" 2 "SNA" 1 "Active" 0 "Inactive" ;
VAL_ 2499763044 BATT_06_event_neg_3_3_analog_err 3 "Error" 2 "SNA" 1 "Active" 0 "Inactive" ;
VAL_ 2499763044 BATT_06_event_inlet_clnt_thrm_op 3 "Error" 2 "SNA" 1 "Active" 0 "Inactive" ;
VAL_ 2499763044 BATT_06_event_hall_eff_lo_rang_e 3 "Error" 2 "SNA" 1 "Active" 0 "Inactive" ;
VAL_ 2499763044 BATT_06_event_outlt_clnt_thrm_sh 3 "Error" 2 "SNA" 1 "Active" 0 "Inactive" ;
VAL_ 2499763044 BATT_06_event_inlet_clnt_thrm_sh 3 "Error" 2 "SNA" 1 "Active" 0 "Inactive" ;
VAL_ 2499763044 BATT_06_event_3_3v_error 3 "Error" 2 "SNA" 1 "Active" 0 "Inactive" ;
VAL_ 2499763044 BATT_07_HVILvoltageError 3 "Error" 2 "SNA" 1 "Active" 0 "Inactive" ;
VAL_ 2499763044 BATT_07_HVILcurrentReturnError 3 "Error" 2 "SNA" 1 "Active" 0 "Inactive" ;
VAL_ 2499763044 BATT_07_PosFcContWelded 3 "Error" 2 "SNA" 1 "Active" 0 "Inactive" ;
VAL_ 2499763044 BATT_07_PosFcContStuckOpen 3 "Error" 2 "SNA" 1 "Active" 0 "Inactive" ;
VAL_ 2499763044 BATT_07_NegFcContWelded 3 "Error" 2 "SNA" 1 "Active" 0 "Inactive" ;
VAL_ 2499763044 BATT_07_NegFcContStuckOpen 3 "Error" 2 "SNA" 1 "Active" 0 "Inactive" ;
VAL_ 2499763044 BATT_07_IsospiBreak 3 "Error" 2 "SNA" 1 "Active" 0 "Inactive" ;
VAL_ 2499763044 BATT_07_IsolationIntFault 3 "Error" 2 "SNA" 1 "Active" 0 "Inactive" ;
VAL_ 2499763044 BATT_07_IsolationExtFault 3 "Error" 2 "SNA" 1 "Active" 0 "Inactive" ;
VAL_ 2499763044 BATT_07_event_12v_filter_error 3 "Error" 2 "SNA" 1 "Active" 0 "Inactive" ;
VAL_ 2499763044 BATT_07_event_hall_eff_hi_rang_e 3 "Error" 2 "SNA" 1 "Active" 0 "Inactive" ;
VAL_ 2499763044 BATT_07_event_brick_volt_sns_ope 3 "Error" 2 "SNA" 1 "Active" 0 "Inactive" ;
VAL_ 2499763044 BATT_07_event_5v_error 3 "Error" 2 "SNA" 1 "Active" 0 "Inactive" ;
VAL_ 2499763044 BATT_07_event_3_3_hot_error 3 "Error" 2 "SNA" 1 "Active" 0 "Inactive" ;
VAL_ 2499763044 BATT_07_event_12v_input_error 3 "Error" 2 "SNA" 1 "Active" 0 "Inactive" ;
VAL_ 2499763044 BATT_07_event_1_25v_error 3 "Error" 2 "SNA" 1 "Active" 0 "Inactive" ;
VAL_ 2499763044 BATT_07_event_shunt_MIA 3 "Error" 2 "SNA" 1 "Active" 0 "Inactive" ;
VAL_ 2499763044 BATT_07_event_SBC_int_reg_error 3 "Error" 2 "SNA" 1 "Active" 0 "Inactive" ;
VAL_ 2499763044 BATT_07_event_pos_3_3v_analog_er 3 "Error" 2 "SNA" 1 "Active" 0 "Inactive" ;
VAL_ 2499763044 BATT_07_event_outlt_clnt_thrm_op 3 "Error" 2 "SNA" 1 "Active" 0 "Inactive" ;
VAL_ 2499763044 BATT_07_event_neg_3_3_analog_err 3 "Error" 2 "SNA" 1 "Active" 0 "Inactive" ;
VAL_ 2499763044 BATT_07_event_inlet_clnt_thrm_op 3 "Error" 2 "SNA" 1 "Active" 0 "Inactive" ;
VAL_ 2499763044 BATT_07_event_hall_eff_lo_rang_e 3 "Error" 2 "SNA" 1 "Active" 0 "Inactive" ;
VAL_ 2499763044 BATT_07_event_outlt_clnt_thrm_sh 3 "Error" 2 "SNA" 1 "Active" 0 "Inactive" ;
VAL_ 2499763044 BATT_07_event_inlet_clnt_thrm_sh 3 "Error" 2 "SNA" 1 "Active" 0 "Inactive" ;
VAL_ 2499763044 BATT_07_event_3_3v_error 3 "Error" 2 "SNA" 1 "Active" 0 "Inactive" ;
VAL_ 2499763044 BATT_08_HVILvoltageError 3 "Error" 2 "SNA" 1 "Active" 0 "Inactive" ;
VAL_ 2499763044 BATT_08_HVILcurrentReturnError 3 "Error" 2 "SNA" 1 "Active" 0 "Inactive" ;
VAL_ 2499763044 BATT_08_PosFcContWelded 3 "Error" 2 "SNA" 1 "Active" 0 "Inactive" ;
VAL_ 2499763044 BATT_08_PosFcContStuckOpen 3 "Error" 2 "SNA" 1 "Active" 0 "Inactive" ;
VAL_ 2499763044 BATT_08_NegFcContWelded 3 "Error" 2 "SNA" 1 "Active" 0 "Inactive" ;
VAL_ 2499763044 BATT_08_NegFcContStuckOpen 3 "Error" 2 "SNA" 1 "Active" 0 "Inactive" ;
VAL_ 2499763044 BATT_08_IsospiBreak 3 "Error" 2 "SNA" 1 "Active" 0 "Inactive" ;
VAL_ 2499763044 BATT_08_IsolationIntFault 3 "Error" 2 "SNA" 1 "Active" 0 "Inactive" ;
VAL_ 2499763044 BATT_08_IsolationExtFault 3 "Error" 2 "SNA" 1 "Active" 0 "Inactive" ;
VAL_ 2499763044 BATT_08_event_12v_filter_error 3 "Error" 2 "SNA" 1 "Active" 0 "Inactive" ;
VAL_ 2499763044 BATT_08_event_hall_eff_hi_rang_e 3 "Error" 2 "SNA" 1 "Active" 0 "Inactive" ;
VAL_ 2499763044 BATT_08_event_brick_volt_sns_ope 3 "Error" 2 "SNA" 1 "Active" 0 "Inactive" ;
VAL_ 2499763044 BATT_08_event_5v_error 3 "Error" 2 "SNA" 1 "Active" 0 "Inactive" ;
VAL_ 2499763044 BATT_08_event_3_3_hot_error 3 "Error" 2 "SNA" 1 "Active" 0 "Inactive" ;
VAL_ 2499763044 BATT_08_event_12v_input_error 3 "Error" 2 "SNA" 1 "Active" 0 "Inactive" ;
VAL_ 2499763044 BATT_08_event_1_25v_error 3 "Error" 2 "SNA" 1 "Active" 0 "Inactive" ;
VAL_ 2499763044 BATT_08_event_shunt_MIA 3 "Error" 2 "SNA" 1 "Active" 0 "Inactive" ;
VAL_ 2499763044 BATT_08_event_SBC_int_reg_error 3 "Error" 2 "SNA" 1 "Active" 0 "Inactive" ;
VAL_ 2499763044 BATT_08_event_pos_3_3v_analog_er 3 "Error" 2 "SNA" 1 "Active" 0 "Inactive" ;
VAL_ 2499763044 BATT_08_event_outlt_clnt_thrm_op 3 "Error" 2 "SNA" 1 "Active" 0 "Inactive" ;
VAL_ 2499763044 BATT_08_event_neg_3_3_analog_err 3 "Error" 2 "SNA" 1 "Active" 0 "Inactive" ;
VAL_ 2499763044 BATT_08_event_inlet_clnt_thrm_op 3 "Error" 2 "SNA" 1 "Active" 0 "Inactive" ;
VAL_ 2499763044 BATT_08_event_hall_eff_lo_rang_e 3 "Error" 2 "SNA" 1 "Active" 0 "Inactive" ;
VAL_ 2499763044 BATT_08_event_outlt_clnt_thrm_sh 3 "Error" 2 "SNA" 1 "Active" 0 "Inactive" ;
VAL_ 2499763044 BATT_08_event_inlet_clnt_thrm_sh 3 "Error" 2 "SNA" 1 "Active" 0 "Inactive" ;
VAL_ 2499763044 BATT_08_event_3_3v_error 3 "Error" 2 "SNA" 1 "Active" 0 "Inactive" ;
VAL_ 2499763044 BATT_09_HVILvoltageError 3 "Error" 2 "SNA" 1 "Active" 0 "Inactive" ;
VAL_ 2499763044 BATT_09_HVILcurrentReturnError 3 "Error" 2 "SNA" 1 "Active" 0 "Inactive" ;
VAL_ 2499763044 BATT_09_PosFcContWelded 3 "Error" 2 "SNA" 1 "Active" 0 "Inactive" ;
VAL_ 2499763044 BATT_09_NegFcContWelded 3 "Error" 2 "SNA" 1 "Active" 0 "Inactive" ;
VAL_ 2499763044 BATT_09_NegFcContStuckOpen 3 "Error" 2 "SNA" 1 "Active" 0 "Inactive" ;
VAL_ 2499763044 BATT_09_PosFcContStuckOpen 3 "Error" 2 "SNA" 1 "Active" 0 "Inactive" ;
VAL_ 2499763044 BATT_09_IsospiBreak 3 "Error" 2 "SNA" 1 "Active" 0 "Inactive" ;
VAL_ 2499763044 BATT_09_IsolationIntFault 3 "Error" 2 "SNA" 1 "Active" 0 "Inactive" ;
VAL_ 2499763044 BATT_09_IsolationExtFault 3 "Error" 2 "SNA" 1 "Active" 0 "Inactive" ;
VAL_ 2499763044 BATT_09_event_12v_filter_error 3 "Error" 2 "SNA" 1 "Active" 0 "Inactive" ;
VAL_ 2499763044 BATT_09_event_hall_eff_hi_rang_e 3 "Error" 2 "SNA" 1 "Active" 0 "Inactive" ;
VAL_ 2499763044 BATT_09_event_brick_volt_sns_ope 3 "Error" 2 "SNA" 1 "Active" 0 "Inactive" ;
VAL_ 2499763044 BATT_09_event_5v_error 3 "Error" 2 "SNA" 1 "Active" 0 "Inactive" ;
VAL_ 2499763044 BATT_09_event_3_3_hot_error 3 "Error" 2 "SNA" 1 "Active" 0 "Inactive" ;
VAL_ 2499763044 BATT_09_event_12v_input_error 3 "Error" 2 "SNA" 1 "Active" 0 "Inactive" ;
VAL_ 2499763044 BATT_09_event_1_25v_error 3 "Error" 2 "SNA" 1 "Active" 0 "Inactive" ;
VAL_ 2499763044 BATT_09_event_shunt_MIA 3 "Error" 2 "SNA" 1 "Active" 0 "Inactive" ;
VAL_ 2499763044 BATT_09_event_SBC_int_reg_error 3 "Error" 2 "SNA" 1 "Active" 0 "Inactive" ;
VAL_ 2499763044 BATT_09_event_pos_3_3v_analog_er 3 "Error" 2 "SNA" 1 "Active" 0 "Inactive" ;
VAL_ 2499763044 BATT_09_event_outlt_clnt_thrm_op 3 "Error" 2 "SNA" 1 "Active" 0 "Inactive" ;
VAL_ 2499763044 BATT_09_event_neg_3_3_analog_err 3 "Error" 2 "SNA" 1 "Active" 0 "Inactive" ;
VAL_ 2499763044 BATT_09_event_inlet_clnt_thrm_op 3 "Error" 2 "SNA" 1 "Active" 0 "Inactive" ;
VAL_ 2499763044 BATT_09_event_hall_eff_lo_rang_e 3 "Error" 2 "SNA" 1 "Active" 0 "Inactive" ;
VAL_ 2499763044 BATT_09_event_outlt_clnt_thrm_sh 3 "Error" 2 "SNA" 1 "Active" 0 "Inactive" ;
VAL_ 2499763044 BATT_09_event_inlet_clnt_thrm_sh 3 "Error" 2 "SNA" 1 "Active" 0 "Inactive" ;
VAL_ 2499763044 BATT_09_event_3_3v_error 3 "Error" 2 "SNA" 1 "Active" 0 "Inactive" ;
VAL_ 2499763044 BATT_10_HVILvoltageError 3 "Error" 2 "SNA" 1 "Active" 0 "Inactive" ;
VAL_ 2499763044 BATT_10_HVILcurrentReturnError 3 "Error" 2 "SNA" 1 "Active" 0 "Inactive" ;
VAL_ 2499763044 BATT_10_PosFcContWelded 3 "Error" 2 "SNA" 1 "Active" 0 "Inactive" ;
VAL_ 2499763044 BATT_10_PosFcContStuckOpen 3 "Error" 2 "SNA" 1 "Active" 0 "Inactive" ;
VAL_ 2499763044 BATT_10_NegFcContWelded 3 "Error" 2 "SNA" 1 "Active" 0 "Inactive" ;
VAL_ 2499763044 BATT_10_NegFcContStuckOpen 3 "Error" 2 "SNA" 1 "Active" 0 "Inactive" ;
VAL_ 2499763044 BATT_10_IsospiBreak 3 "Error" 2 "SNA" 1 "Active" 0 "Inactive" ;
VAL_ 2499763044 BATT_10_IsolationIntFault 3 "Error" 2 "SNA" 1 "Active" 0 "Inactive" ;
VAL_ 2499763044 BATT_10_IsolationExtFault 3 "Error" 2 "SNA" 1 "Active" 0 "Inactive" ;
VAL_ 2499763044 BATT_10_event_12v_filter_error 3 "Error" 2 "SNA" 1 "Active" 0 "Inactive" ;
VAL_ 2499763044 BATT_10_event_hall_eff_hi_rang_e 3 "Error" 2 "SNA" 1 "Active" 0 "Inactive" ;
VAL_ 2499763044 BATT_10_event_brick_volt_sns_ope 3 "Error" 2 "SNA" 1 "Active" 0 "Inactive" ;
VAL_ 2499763044 BATT_10_event_5v_error 3 "Error" 2 "SNA" 1 "Active" 0 "Inactive" ;
VAL_ 2499763044 BATT_10_event_3_3_hot_error 3 "Error" 2 "SNA" 1 "Active" 0 "Inactive" ;
VAL_ 2499763044 BATT_10_event_12v_input_error 3 "Error" 2 "SNA" 1 "Active" 0 "Inactive" ;
VAL_ 2499763044 BATT_10_event_1_25v_error 3 "Error" 2 "SNA" 1 "Active" 0 "Inactive" ;
VAL_ 2499763044 BATT_10_event_shunt_MIA 3 "Error" 2 "SNA" 1 "Active" 0 "Inactive" ;
VAL_ 2499763044 BATT_10_event_SBC_int_reg_error 3 "Error" 2 "SNA" 1 "Active" 0 "Inactive" ;
VAL_ 2499763044 BATT_10_event_pos_3_3v_analog_er 3 "Error" 2 "SNA" 1 "Active" 0 "Inactive" ;
VAL_ 2499763044 BATT_10_event_outlt_clnt_thrm_op 3 "Error" 2 "SNA" 1 "Active" 0 "Inactive" ;
VAL_ 2499763044 BATT_10_event_neg_3_3_analog_err 3 "Error" 2 "SNA" 1 "Active" 0 "Inactive" ;
VAL_ 2499763044 BATT_10_event_inlet_clnt_thrm_op 3 "Error" 2 "SNA" 1 "Active" 0 "Inactive" ;
VAL_ 2499763044 BATT_10_event_hall_eff_lo_rang_e 3 "Error" 2 "SNA" 1 "Active" 0 "Inactive" ;
VAL_ 2499763044 BATT_10_event_outlt_clnt_thrm_sh 3 "Error" 2 "SNA" 1 "Active" 0 "Inactive" ;
VAL_ 2499763044 BATT_10_event_inlet_clnt_thrm_sh 3 "Error" 2 "SNA" 1 "Active" 0 "Inactive" ;
VAL_ 2499763044 BATT_10_event_3_3v_error 3 "Error" 2 "SNA" 1 "Active" 0 "Inactive" ;
VAL_ 2499763044 BATT_11_HVILvoltageError 3 "Error" 2 "SNA" 1 "Active" 0 "Inactive" ;
VAL_ 2499763044 BATT_11_HVILcurrentReturnError 3 "Error" 2 "SNA" 1 "Active" 0 "Inactive" ;
VAL_ 2499763044 BATT_11_PosFcContWelded 3 "Error" 2 "SNA" 1 "Active" 0 "Inactive" ;
VAL_ 2499763044 BATT_11_PosFcContStuckOpen 3 "Error" 2 "SNA" 1 "Active" 0 "Inactive" ;
VAL_ 2499763044 BATT_11_NegFcContWelded 3 "Error" 2 "SNA" 1 "Active" 0 "Inactive" ;
VAL_ 2499763044 BATT_11_NegFcContStuckOpen 3 "Error" 2 "SNA" 1 "Active" 0 "Inactive" ;
VAL_ 2499763044 BATT_11_IsospiBreak 3 "Error" 2 "SNA" 1 "Active" 0 "Inactive" ;
VAL_ 2499763044 BATT_11_IsolationIntFault 3 "Error" 2 "SNA" 1 "Active" 0 "Inactive" ;
VAL_ 2499763044 BATT_11_IsolationExtFault 3 "Error" 2 "SNA" 1 "Active" 0 "Inactive" ;
VAL_ 2499763044 BATT_11_event_12v_filter_error 3 "Error" 2 "SNA" 1 "Active" 0 "Inactive" ;
VAL_ 2499763044 BATT_11_event_hall_eff_hi_rang_e 3 "Error" 2 "SNA" 1 "Active" 0 "Inactive" ;
VAL_ 2499763044 BATT_11_event_brick_volt_sns_ope 3 "Error" 2 "SNA" 1 "Active" 0 "Inactive" ;
VAL_ 2499763044 BATT_11_event_5v_error 3 "Error" 2 "SNA" 1 "Active" 0 "Inactive" ;
VAL_ 2499763044 BATT_11_event_3_3_hot_error 3 "Error" 2 "SNA" 1 "Active" 0 "Inactive" ;
VAL_ 2499763044 BATT_11_event_12v_input_error 3 "Error" 2 "SNA" 1 "Active" 0 "Inactive" ;
VAL_ 2499763044 BATT_11_event_1_25v_error 3 "Error" 2 "SNA" 1 "Active" 0 "Inactive" ;
VAL_ 2499763044 BATT_11_event_shunt_MIA 3 "Error" 2 "SNA" 1 "Active" 0 "Inactive" ;
VAL_ 2499763044 BATT_11_event_SBC_int_reg_error 3 "Error" 2 "SNA" 1 "Active" 0 "Inactive" ;
VAL_ 2499763044 BATT_11_event_pos_3_3v_analog_er 3 "Error" 2 "SNA" 1 "Active" 0 "Inactive" ;
VAL_ 2499763044 BATT_11_event_outlt_clnt_thrm_op 3 "Error" 2 "SNA" 1 "Active" 0 "Inactive" ;
VAL_ 2499763044 BATT_11_event_neg_3_3_analog_err 3 "Error" 2 "SNA" 1 "Active" 0 "Inactive" ;
VAL_ 2499763044 BATT_11_event_inlet_clnt_thrm_op 3 "Error" 2 "SNA" 1 "Active" 0 "Inactive" ;
VAL_ 2499763044 BATT_11_event_hall_eff_lo_rang_e 3 "Error" 2 "SNA" 1 "Active" 0 "Inactive" ;
VAL_ 2499763044 BATT_11_event_outlt_clnt_thrm_sh 3 "Error" 2 "SNA" 1 "Active" 0 "Inactive" ;
VAL_ 2499763044 BATT_11_event_inlet_clnt_thrm_sh 3 "Error" 2 "SNA" 1 "Active" 0 "Inactive" ;
VAL_ 2499763044 BATT_11_event_3_3v_error 3 "Error" 2 "SNA" 1 "Active" 0 "Inactive" ;
VAL_ 2499763044 BATT_12_HVILvoltageError 3 "Error" 2 "SNA" 1 "Active" 0 "Inactive" ;
VAL_ 2499763044 BATT_12_HVILcurrentReturnError 3 "Error" 2 "SNA" 1 "Active" 0 "Inactive" ;
VAL_ 2499763044 BATT_12_PosFcContWelded 3 "Error" 2 "SNA" 1 "Active" 0 "Inactive" ;
VAL_ 2499763044 BATT_12_PosFcContStuckOpen 3 "Error" 2 "SNA" 1 "Active" 0 "Inactive" ;
VAL_ 2499763044 BATT_12_NegFcContWelded 3 "Error" 2 "SNA" 1 "Active" 0 "Inactive" ;
VAL_ 2499763044 BATT_12_NegFcContStuckOpen 3 "Error" 2 "SNA" 1 "Active" 0 "Inactive" ;
VAL_ 2499763044 BATT_12_IsospiBreak 3 "Error" 2 "SNA" 1 "Active" 0 "Inactive" ;
VAL_ 2499763044 BATT_12_IsolationIntFault 3 "Error" 2 "SNA" 1 "Active" 0 "Inactive" ;
VAL_ 2499763044 BATT_12_IsolationExtFault 3 "Error" 2 "SNA" 1 "Active" 0 "Inactive" ;
VAL_ 2499763044 BATT_12_event_12v_filter_error 3 "Error" 2 "SNA" 1 "Active" 0 "Inactive" ;
VAL_ 2499763044 BATT_12_event_hall_eff_hi_rang_e 3 "Error" 2 "SNA" 1 "Active" 0 "Inactive" ;
VAL_ 2499763044 BATT_12_event_brick_volt_sns_ope 3 "Error" 2 "SNA" 1 "Active" 0 "Inactive" ;
VAL_ 2499763044 BATT_12_event_5v_error 3 "Error" 2 "SNA" 1 "Active" 0 "Inactive" ;
VAL_ 2499763044 BATT_12_event_3_3_hot_error 3 "Error" 2 "SNA" 1 "Active" 0 "Inactive" ;
VAL_ 2499763044 BATT_12_event_12v_input_error 3 "Error" 2 "SNA" 1 "Active" 0 "Inactive" ;
VAL_ 2499763044 BATT_12_event_1_25v_error 3 "Error" 2 "SNA" 1 "Active" 0 "Inactive" ;
VAL_ 2499763044 BATT_12_event_shunt_MIA 3 "Error" 2 "SNA" 1 "Active" 0 "Inactive" ;
VAL_ 2499763044 BATT_12_event_SBC_int_reg_error 3 "Error" 2 "SNA" 1 "Active" 0 "Inactive" ;
VAL_ 2499763044 BATT_12_event_pos_3_3v_analog_er 3 "Error" 2 "SNA" 1 "Active" 0 "Inactive" ;
VAL_ 2499763044 BATT_12_event_outlt_clnt_thrm_op 3 "Error" 2 "SNA" 1 "Active" 0 "Inactive" ;
VAL_ 2499763044 BATT_12_event_neg_3_3_analog_err 3 "Error" 2 "SNA" 1 "Active" 0 "Inactive" ;
VAL_ 2499763044 BATT_12_event_inlet_clnt_thrm_op 3 "Error" 2 "SNA" 1 "Active" 0 "Inactive" ;
VAL_ 2499763044 BATT_12_event_hall_eff_lo_rang_e 3 "Error" 2 "SNA" 1 "Active" 0 "Inactive" ;
VAL_ 2499763044 BATT_12_event_outlt_clnt_thrm_sh 3 "Error" 2 "SNA" 1 "Active" 0 "Inactive" ;
VAL_ 2499763044 BATT_12_event_inlet_clnt_thrm_sh 3 "Error" 2 "SNA" 1 "Active" 0 "Inactive" ;
VAL_ 2499763044 BATT_12_event_3_3v_error 3 "Error" 2 "SNA" 1 "Active" 0 "Inactive" ;
VAL_ 2499763044 BATT_13_HVILvoltageError 3 "Error" 2 "SNA" 1 "Active" 0 "Inactive" ;
VAL_ 2499763044 BATT_13_HVILcurrentReturnError 3 "Error" 2 "SNA" 1 "Active" 0 "Inactive" ;
VAL_ 2499763044 BATT_13_PosFcContWelded 3 "Error" 2 "SNA" 1 "Active" 0 "Inactive" ;
VAL_ 2499763044 BATT_13_PosFcContStuckOpen 3 "Error" 2 "SNA" 1 "Active" 0 "Inactive" ;
VAL_ 2499763044 BATT_13_NegFcContWelded 3 "Error" 2 "SNA" 1 "Active" 0 "Inactive" ;
VAL_ 2499763044 BATT_13_NegFcContStuckOpen 3 "Error" 2 "SNA" 1 "Active" 0 "Inactive" ;
VAL_ 2499763044 BATT_13_IsospiBreak 3 "Error" 2 "SNA" 1 "Active" 0 "Inactive" ;
VAL_ 2499763044 BATT_13_IsolationIntFault 3 "Error" 2 "SNA" 1 "Active" 0 "Inactive" ;
VAL_ 2499763044 BATT_13_IsolationExtFault 3 "Error" 2 "SNA" 1 "Active" 0 "Inactive" ;
VAL_ 2499763044 BATT_13_event_12v_filter_error 3 "Error" 2 "SNA" 1 "Active" 0 "Inactive" ;
VAL_ 2499763044 BATT_13_event_hall_eff_hi_rang_e 3 "Error" 2 "SNA" 1 "Active" 0 "Inactive" ;
VAL_ 2499763044 BATT_13_event_brick_volt_sns_ope 3 "Error" 2 "SNA" 1 "Active" 0 "Inactive" ;
VAL_ 2499763044 BATT_13_event_5v_error 3 "Error" 2 "SNA" 1 "Active" 0 "Inactive" ;
VAL_ 2499763044 BATT_13_event_3_3_hot_error 3 "Error" 2 "SNA" 1 "Active" 0 "Inactive" ;
VAL_ 2499763044 BATT_13_event_12v_input_error 3 "Error" 2 "SNA" 1 "Active" 0 "Inactive" ;
VAL_ 2499763044 BATT_13_event_1_25v_error 3 "Error" 2 "SNA" 1 "Active" 0 "Inactive" ;
VAL_ 2499763044 BATT_13_event_shunt_MIA 3 "Error" 2 "SNA" 1 "Active" 0 "Inactive" ;
VAL_ 2499763044 BATT_13_event_SBC_int_reg_error 3 "Error" 2 "SNA" 1 "Active" 0 "Inactive" ;
VAL_ 2499763044 BATT_13_event_pos_3_3v_analog_er 3 "Error" 2 "SNA" 1 "Active" 0 "Inactive" ;
VAL_ 2499763044 BATT_13_event_outlt_clnt_thrm_op 3 "Error" 2 "SNA" 1 "Active" 0 "Inactive" ;
VAL_ 2499763044 BATT_13_event_neg_3_3_analog_err 3 "Error" 2 "SNA" 1 "Active" 0 "Inactive" ;
VAL_ 2499763044 BATT_13_event_inlet_clnt_thrm_op 3 "Error" 2 "SNA" 1 "Active" 0 "Inactive" ;
VAL_ 2499763044 BATT_13_event_hall_eff_lo_rang_e 3 "Error" 2 "SNA" 1 "Active" 0 "Inactive" ;
VAL_ 2499763044 BATT_13_event_outlt_clnt_thrm_sh 3 "Error" 2 "SNA" 1 "Active" 0 "Inactive" ;
VAL_ 2499763044 BATT_13_event_inlet_clnt_thrm_sh 3 "Error" 2 "SNA" 1 "Active" 0 "Inactive" ;
VAL_ 2499763044 BATT_13_event_3_3v_error 3 "Error" 2 "SNA" 1 "Active" 0 "Inactive" ;
VAL_ 2499763044 BATT_14_HVILvoltageError 3 "Error" 2 "SNA" 1 "Active" 0 "Inactive" ;
VAL_ 2499763044 BATT_14_HVILcurrentReturnError 3 "Error" 2 "SNA" 1 "Active" 0 "Inactive" ;
VAL_ 2499763044 BATT_14_PosFcContWelded 3 "Error" 2 "SNA" 1 "Active" 0 "Inactive" ;
VAL_ 2499763044 BATT_14_PosFcContStuckOpen 3 "Error" 2 "SNA" 1 "Active" 0 "Inactive" ;
VAL_ 2499763044 BATT_14_NegFcContWelded 3 "Error" 2 "SNA" 1 "Active" 0 "Inactive" ;
VAL_ 2499763044 BATT_14_NegFcContStuckOpen 3 "Error" 2 "SNA" 1 "Active" 0 "Inactive" ;
VAL_ 2499763044 BATT_14_IsospiBreak 3 "Error" 2 "SNA" 1 "Active" 0 "Inactive" ;
VAL_ 2499763044 BATT_14_IsolationIntFault 3 "Error" 2 "SNA" 1 "Active" 0 "Inactive" ;
VAL_ 2499763044 BATT_14_IsolationExtFault 3 "Error" 2 "SNA" 1 "Active" 0 "Inactive" ;
VAL_ 2499763044 BATT_14_event_12v_filter_error 3 "Error" 2 "SNA" 1 "Active" 0 "Inactive" ;
VAL_ 2499763044 BATT_14_event_hall_eff_hi_rang_e 3 "Error" 2 "SNA" 1 "Active" 0 "Inactive" ;
VAL_ 2499763044 BATT_14_event_brick_volt_sns_ope 3 "Error" 2 "SNA" 1 "Active" 0 "Inactive" ;
VAL_ 2499763044 BATT_14_event_5v_error 3 "Error" 2 "SNA" 1 "Active" 0 "Inactive" ;
VAL_ 2499763044 BATT_14_event_3_3_hot_error 3 "Error" 2 "SNA" 1 "Active" 0 "Inactive" ;
VAL_ 2499763044 BATT_14_event_12v_input_error 3 "Error" 2 "SNA" 1 "Active" 0 "Inactive" ;
VAL_ 2499763044 BATT_14_event_1_25v_error 3 "Error" 2 "SNA" 1 "Active" 0 "Inactive" ;
VAL_ 2499763044 BATT_14_event_shunt_MIA 3 "Error" 2 "SNA" 1 "Active" 0 "Inactive" ;
VAL_ 2499763044 BATT_14_event_SBC_int_reg_error 3 "Error" 2 "SNA" 1 "Active" 0 "Inactive" ;
VAL_ 2499763044 BATT_14_event_pos_3_3v_analog_er 3 "Error" 2 "SNA" 1 "Active" 0 "Inactive" ;
VAL_ 2499763044 BATT_14_event_outlt_clnt_thrm_op 3 "Error" 2 "SNA" 1 "Active" 0 "Inactive" ;
VAL_ 2499763044 BATT_14_event_neg_3_3_analog_err 3 "Error" 2 "SNA" 1 "Active" 0 "Inactive" ;
VAL_ 2499763044 BATT_14_event_inlet_clnt_thrm_op 3 "Error" 2 "SNA" 1 "Active" 0 "Inactive" ;
VAL_ 2499763044 BATT_14_event_hall_eff_lo_rang_e 3 "Error" 2 "SNA" 1 "Active" 0 "Inactive" ;
VAL_ 2499763044 BATT_14_event_outlt_clnt_thrm_sh 3 "Error" 2 "SNA" 1 "Active" 0 "Inactive" ;
VAL_ 2499763044 BATT_14_event_inlet_clnt_thrm_sh 3 "Error" 2 "SNA" 1 "Active" 0 "Inactive" ;
VAL_ 2499763044 BATT_14_event_3_3v_error 3 "Error" 2 "SNA" 1 "Active" 0 "Inactive" ;
VAL_ 2499763044 BATT_15_HVILvoltageError 3 "Error" 2 "SNA" 1 "Active" 0 "Inactive" ;
VAL_ 2499763044 BATT_15_HVILcurrentReturnError 3 "Error" 2 "SNA" 1 "Active" 0 "Inactive" ;
VAL_ 2499763044 BATT_15_PosFcContWelded 3 "Error" 2 "SNA" 1 "Active" 0 "Inactive" ;
VAL_ 2499763044 BATT_15_PosFcContStuckOpen 3 "Error" 2 "SNA" 1 "Active" 0 "Inactive" ;
VAL_ 2499763044 BATT_15_NegFcContWelded 3 "Error" 2 "SNA" 1 "Active" 0 "Inactive" ;
VAL_ 2499763044 BATT_15_NegFcContStuckOpen 3 "Error" 2 "SNA" 1 "Active" 0 "Inactive" ;
VAL_ 2499763044 BATT_15_IsospiBreak 3 "Error" 2 "SNA" 1 "Active" 0 "Inactive" ;
VAL_ 2499763044 BATT_15_IsolationIntFault 3 "Error" 2 "SNA" 1 "Active" 0 "Inactive" ;
VAL_ 2499763044 BATT_15_IsolationExtFault 3 "Error" 2 "SNA" 1 "Active" 0 "Inactive" ;
VAL_ 2499763044 BATT_15_event_12v_filter_error 3 "Error" 2 "SNA" 1 "Active" 0 "Inactive" ;
VAL_ 2499763044 BATT_15_event_hall_eff_hi_rang_e 3 "Error" 2 "SNA" 1 "Active" 0 "Inactive" ;
VAL_ 2499763044 BATT_15_event_brick_volt_sns_ope 3 "Error" 2 "SNA" 1 "Active" 0 "Inactive" ;
VAL_ 2499763044 BATT_15_event_5v_error 3 "Error" 2 "SNA" 1 "Active" 0 "Inactive" ;
VAL_ 2499763044 BATT_15_event_3_3_hot_error 3 "Error" 2 "SNA" 1 "Active" 0 "Inactive" ;
VAL_ 2499763044 BATT_15_event_12v_input_error 3 "Error" 2 "SNA" 1 "Active" 0 "Inactive" ;
VAL_ 2499763044 BATT_15_event_1_25v_error 3 "Error" 2 "SNA" 1 "Active" 0 "Inactive" ;
VAL_ 2499763044 BATT_15_event_shunt_MIA 3 "Error" 2 "SNA" 1 "Active" 0 "Inactive" ;
VAL_ 2499763044 BATT_15_event_SBC_int_reg_error 3 "Error" 2 "SNA" 1 "Active" 0 "Inactive" ;
VAL_ 2499763044 BATT_15_event_pos_3_3v_analog_er 3 "Error" 2 "SNA" 1 "Active" 0 "Inactive" ;
VAL_ 2499763044 BATT_15_event_outlt_clnt_thrm_op 3 "Error" 2 "SNA" 1 "Active" 0 "Inactive" ;
VAL_ 2499763044 BATT_15_event_neg_3_3_analog_err 3 "Error" 2 "SNA" 1 "Active" 0 "Inactive" ;
VAL_ 2499763044 BATT_15_event_inlet_clnt_thrm_op 3 "Error" 2 "SNA" 1 "Active" 0 "Inactive" ;
VAL_ 2499763044 BATT_15_event_hall_eff_lo_rang_e 3 "Error" 2 "SNA" 1 "Active" 0 "Inactive" ;
VAL_ 2499763044 BATT_15_event_outlt_clnt_thrm_sh 3 "Error" 2 "SNA" 1 "Active" 0 "Inactive" ;
VAL_ 2499763044 BATT_15_event_inlet_clnt_thrm_sh 3 "Error" 2 "SNA" 1 "Active" 0 "Inactive" ;
VAL_ 2499763044 BATT_15_event_3_3v_error 3 "Error" 2 "SNA" 1 "Active" 0 "Inactive" ;
